VERSION ""

NS_ :

BS_:

BU_: RLPSU DPSU APSU PSB SHVU_RR vHS_B2 FCS EMCU SLB RCM CGW_CCU vDummy_HS_B ATS RLHV PFSU SGU ALBCU DSAU SWRC SHVU_FR RCS RRPSU BLTN_CAM SCM DLBCU OHCL RWPC RRHV WPC HOD ASAU

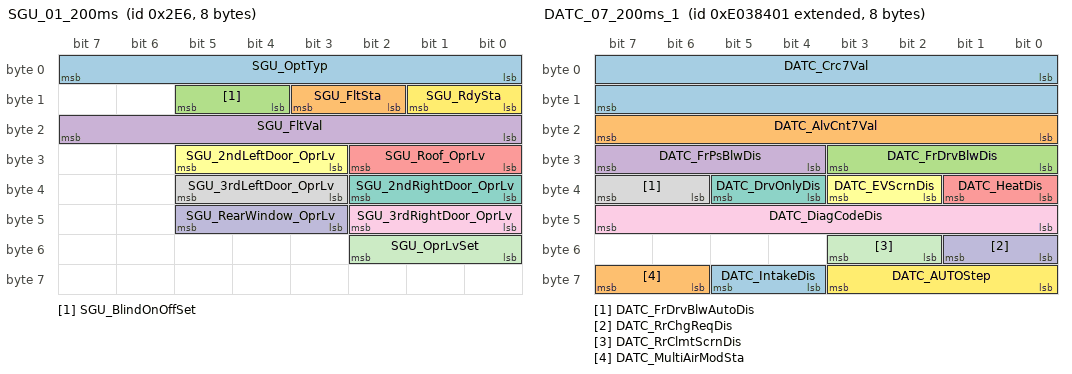
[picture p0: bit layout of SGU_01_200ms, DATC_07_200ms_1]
BO_ 742 SGU_01_200ms: 8 SGU
 SG_ SGU_OptTyp : 0|8@1+ (1,0) [0|0] ""  Vector__XXX
 SG_ SGU_FltSta : 10|2@1+ (1,0) [0|0] ""  Vector__XXX
 SG_ SGU_BlindOnOffSet : 12|2@1+ (1,0) [0|0] ""  CGW_CCU
 SG_ SGU_FltVal : 16|8@1+ (1,0) [0|0] ""  Vector__XXX
 SG_ SGU_Roof_OprLv : 24|3@1+ (1,0) [0|0] ""  CGW_CCU
 SG_ SGU_2ndLeftDoor_OprLv : 27|3@1+ (1,0) [0|0] ""  CGW_CCU
 SG_ SGU_2ndRightDoor_OprLv : 32|3@1+ (1,0) [0|0] ""  CGW_CCU
 SG_ SGU_3rdLeftDoor_OprLv : 35|3@1+ (1,0) [0|0] ""  CGW_CCU
 SG_ SGU_3rdRightDoor_OprLv : 40|3@1+ (1,0) [0|0] ""  CGW_CCU
 SG_ SGU_RearWindow_OprLv : 43|3@1+ (1,0) [0|0] ""  CGW_CCU
 SG_ SGU_OprLvSet : 48|3@1+ (1,0) [0|0] ""  CGW_CCU
 SG_ SGU_RdySta : 8|2@1+ (1,0) [0|0] ""  Vector__XXX

BO_ 2382595073 DATC_07_200ms_1: 8 CGW_CCU
 SG_ DATC_Crc7Val : 0|16@1+ (1,0) [0|0] ""  Vector__XXX
 SG_ DATC_AlvCnt7Val : 16|8@1+ (1,0) [0|0] ""  Vector__XXX
 SG_ DATC_FrDrvBlwDis : 24|4@1+ (1,0) [0|0] ""  ATS
 SG_ DATC_FrPsBlwDis : 28|4@1+ (1,0) [0|0] ""  ATS
 SG_ DATC_HeatDis : 32|2@1+ (1,0) [0|0] "flag"  ATS
 SG_ DATC_EVScrnDis : 34|2@1+ (1,0) [0|0] ""  Vector__XXX
 SG_ DATC_DrvOnlyDis : 36|2@1+ (1,0) [0|0] ""  ATS
 SG_ DATC_FrDrvBlwAutoDis : 38|2@1+ (1,0) [0|0] ""  Vector__XXX
 SG_ DATC_DiagCodeDis : 40|8@1+ (1,-1) [0|0] ""  Vector__XXX
 SG_ DATC_RrChgReqDis : 48|2@1+ (1,0) [0|0] ""  Vector__XXX
 SG_ DATC_RrClmtScrnDis : 50|2@1+ (1,0) [0|0] ""  ATS
 SG_ DATC_AUTOStep : 56|4@1+ (1,0) [0|0] ""  ATS
 SG_ DATC_IntakeDis : 60|2@1+ (1,0) [0|0] ""  ATS
 SG_ DATC_MultiAirModSta : 62|2@1+ (1,0) [0|0] ""  Vector__XXX

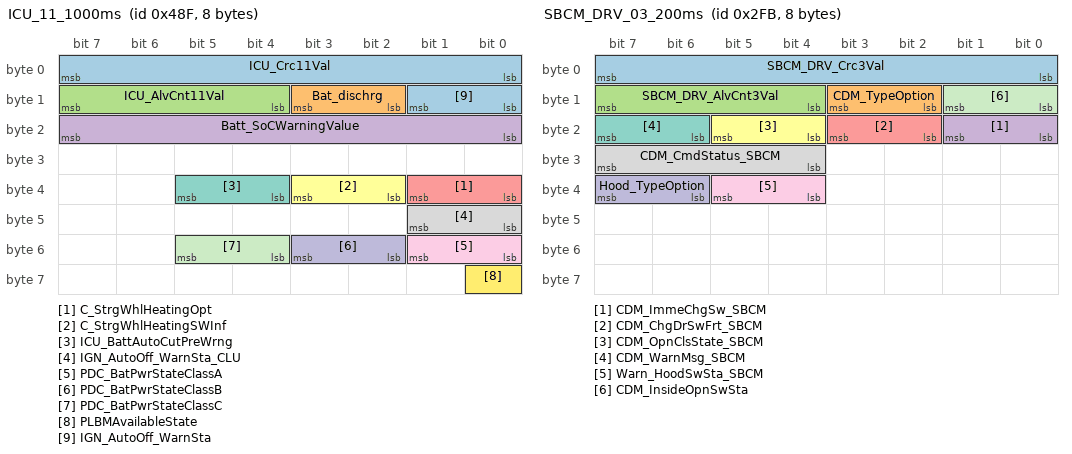
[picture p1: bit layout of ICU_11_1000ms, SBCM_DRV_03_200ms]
BO_ 1167 ICU_11_1000ms: 8 CGW_CCU
 SG_ ICU_Crc11Val : 0|8@1+ (1,0) [0|0] ""  Vector__XXX
 SG_ Bat_dischrg : 10|2@1+ (1,0) [0|0] ""  Vector__XXX
 SG_ ICU_AlvCnt11Val : 12|4@1+ (1,0) [0|0] ""  Vector__XXX
 SG_ Batt_SoCWarningValue : 16|8@1+ (1,0) [0|0] "%"  Vector__XXX
 SG_ C_StrgWhlHeatingOpt : 32|2@1+ (1,0) [0|0] ""  Vector__XXX
 SG_ C_StrgWhlHeatingSWInf : 34|2@1+ (1,0) [0|0] ""  Vector__XXX
 SG_ ICU_BattAutoCutPreWrng : 36|2@1+ (1,0) [0|0] ""  BLTN_CAM
 SG_ IGN_AutoOff_WarnSta_CLU : 40|2@1+ (1,0) [0|0] ""  Vector__XXX
 SG_ PDC_BatPwrStateClassA : 48|2@1+ (1,0) [0|0] ""  Vector__XXX
 SG_ PDC_BatPwrStateClassB : 50|2@1+ (1,0) [0|0] ""  Vector__XXX
 SG_ PDC_BatPwrStateClassC : 52|2@1+ (1,0) [0|0] ""  Vector__XXX
 SG_ PLBMAvailableState : 56|1@1+ (1,0) [0|0] ""  Vector__XXX
 SG_ IGN_AutoOff_WarnSta : 8|2@1+ (1,0) [0|0] ""  Vector__XXX

BO_ 763 SBCM_DRV_03_200ms: 8 CGW_CCU
 SG_ SBCM_DRV_Crc3Val : 0|8@1+ (1,0) [0|0] ""  Vector__XXX
 SG_ CDM_TypeOption : 10|2@1+ (1,0) [0|0] ""  Vector__XXX
 SG_ SBCM_DRV_AlvCnt3Val : 12|4@1+ (1,0) [0|0] ""  Vector__XXX
 SG_ CDM_ImmeChgSw_SBCM : 16|2@1+ (1,0) [0|0] ""  Vector__XXX
 SG_ CDM_ChgDrSwFrt_SBCM : 18|2@1+ (1,0) [0|0] ""  Vector__XXX
 SG_ CDM_OpnClsState_SBCM : 20|2@1+ (1,0) [0|0] ""  Vector__XXX
 SG_ CDM_WarnMsg_SBCM : 22|2@1+ (1,0) [0|0] ""  Vector__XXX
 SG_ CDM_CmdStatus_SBCM : 28|4@1+ (1,0) [0|0] ""  Vector__XXX
 SG_ Warn_HoodSwSta_SBCM : 36|2@1+ (1,0) [0|0] ""  BLTN_CAM
 SG_ Hood_TypeOption : 38|2@1+ (1,0) [0|0] ""  BLTN_CAM
 SG_ CDM_InsideOpnSwSta : 8|2@1+ (1,0) [0|0] ""  Vector__XXX

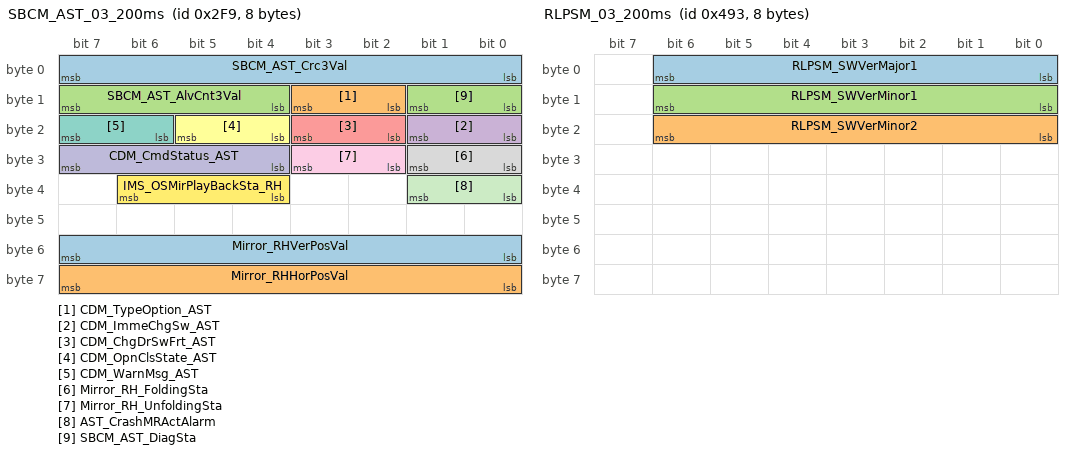
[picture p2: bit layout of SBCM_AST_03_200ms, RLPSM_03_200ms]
BO_ 761 SBCM_AST_03_200ms: 8 CGW_CCU
 SG_ SBCM_AST_Crc3Val : 0|8@1+ (1,0) [0|0] ""  Vector__XXX
 SG_ CDM_TypeOption_AST : 10|2@1+ (1,0) [0|0] ""  Vector__XXX
 SG_ SBCM_AST_AlvCnt3Val : 12|4@1+ (1,0) [0|0] ""  Vector__XXX
 SG_ CDM_ImmeChgSw_AST : 16|2@1+ (1,0) [0|0] ""  Vector__XXX
 SG_ CDM_ChgDrSwFrt_AST : 18|2@1+ (1,0) [0|0] ""  Vector__XXX
 SG_ CDM_OpnClsState_AST : 20|2@1+ (1,0) [0|0] ""  Vector__XXX
 SG_ CDM_WarnMsg_AST : 22|2@1+ (1,0) [0|0] ""  Vector__XXX
 SG_ Mirror_RH_FoldingSta : 24|2@1+ (1,0) [0|0] ""  Vector__XXX
 SG_ Mirror_RH_UnfoldingSta : 26|2@1+ (1,0) [0|0] ""  Vector__XXX
 SG_ CDM_CmdStatus_AST : 28|4@1+ (1,0) [0|0] ""  Vector__XXX
 SG_ AST_CrashMRActAlarm : 32|2@1+ (1,0) [0|0] ""  Vector__XXX
 SG_ IMS_OSMirPlayBackSta_RH : 36|3@1+ (1,0) [0|0] ""  DPSU
 SG_ Mirror_RHVerPosVal : 48|8@1+ (0.02,0) [0|0] "V"  Vector__XXX
 SG_ Mirror_RHHorPosVal : 56|8@1+ (0.02,0) [0|0] "V"  Vector__XXX
 SG_ SBCM_AST_DiagSta : 8|2@1+ (1,0) [0|0] ""  Vector__XXX

BO_ 1171 RLPSM_03_200ms: 8 RLPSU
 SG_ RLPSM_SWVerMajor1 : 0|7@1+ (1,0) [0|0] ""  Vector__XXX
 SG_ RLPSM_SWVerMinor2 : 16|7@1+ (1,0) [0|0] ""  Vector__XXX
 SG_ RLPSM_SWVerMinor1 : 8|7@1+ (1,0) [0|0] ""  Vector__XXX

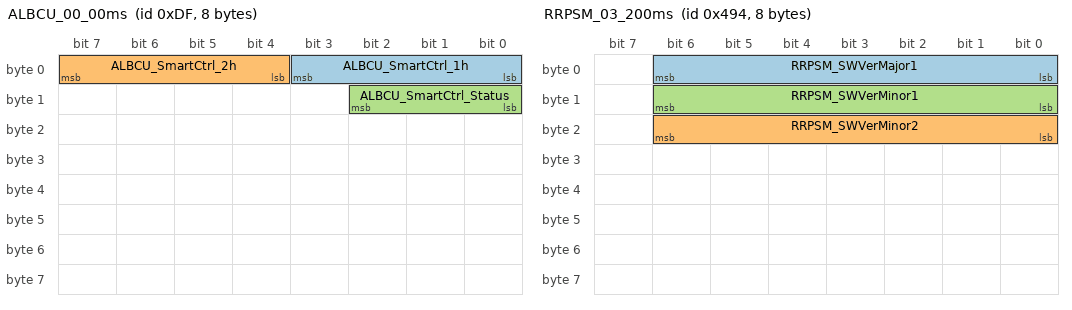
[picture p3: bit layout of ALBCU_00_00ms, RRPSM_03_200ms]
BO_ 223 ALBCU_00_00ms: 8 ALBCU
 SG_ ALBCU_SmartCtrl_1h : 0|4@1+ (1,0) [0|0] ""  CGW_CCU
 SG_ ALBCU_SmartCtrl_2h : 4|4@1+ (1,0) [0|0] ""  CGW_CCU
 SG_ ALBCU_SmartCtrl_Status : 8|3@1+ (1,0) [0|0] ""  CGW_CCU

BO_ 1172 RRPSM_03_200ms: 8 RRPSU
 SG_ RRPSM_SWVerMajor1 : 0|7@1+ (1,0) [0|0] ""  Vector__XXX
 SG_ RRPSM_SWVerMinor2 : 16|7@1+ (1,0) [0|0] ""  Vector__XXX
 SG_ RRPSM_SWVerMinor1 : 8|7@1+ (1,0) [0|0] ""  Vector__XXX

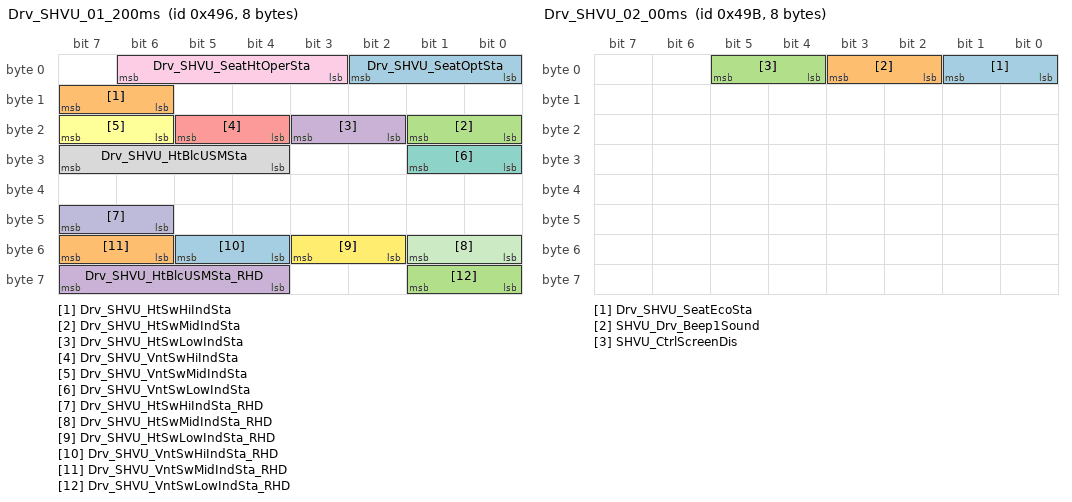
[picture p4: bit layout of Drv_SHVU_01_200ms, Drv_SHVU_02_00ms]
BO_ 1174 Drv_SHVU_01_200ms: 8 APSU
 SG_ Drv_SHVU_SeatOptSta : 0|3@1+ (1,0) [0|0] ""  CGW_CCU,FCS,CGW_CCU
 SG_ Drv_SHVU_HtSwHiIndSta : 14|2@1+ (1,0) [0|0] ""  FCS,CGW_CCU
 SG_ Drv_SHVU_HtSwMidIndSta : 16|2@1+ (1,0) [0|0] ""  FCS,CGW_CCU
 SG_ Drv_SHVU_HtSwLowIndSta : 18|2@1+ (1,0) [0|0] ""  FCS,CGW_CCU
 SG_ Drv_SHVU_VntSwHiIndSta : 20|2@1+ (1,0) [0|0] ""  FCS,CGW_CCU
 SG_ Drv_SHVU_VntSwMidIndSta : 22|2@1+ (1,0) [0|0] ""  FCS,CGW_CCU
 SG_ Drv_SHVU_VntSwLowIndSta : 24|2@1+ (1,0) [0|0] ""  FCS,CGW_CCU
 SG_ Drv_SHVU_HtBlcUSMSta : 28|4@1+ (1,0) [0|0] ""  CGW_CCU
 SG_ Drv_SHVU_SeatHtOperSta : 3|4@1+ (1,0) [0|0] ""  CGW_CCU
 SG_ Drv_SHVU_HtSwHiIndSta_RHD : 46|2@1+ (1,0) [0|0] ""  FCS,CGW_CCU
 SG_ Drv_SHVU_HtSwMidIndSta_RHD : 48|2@1+ (1,0) [0|0] ""  FCS,CGW_CCU
 SG_ Drv_SHVU_HtSwLowIndSta_RHD : 50|2@1+ (1,0) [0|0] ""  FCS,CGW_CCU
 SG_ Drv_SHVU_VntSwHiIndSta_RHD : 52|2@1+ (1,0) [0|0] ""  FCS,CGW_CCU
 SG_ Drv_SHVU_VntSwMidIndSta_RHD : 54|2@1+ (1,0) [0|0] ""  FCS,CGW_CCU
 SG_ Drv_SHVU_VntSwLowIndSta_RHD : 56|2@1+ (1,0) [0|0] ""  FCS,CGW_CCU
 SG_ Drv_SHVU_HtBlcUSMSta_RHD : 60|4@1+ (1,0) [0|0] ""  CGW_CCU

BO_ 1179 Drv_SHVU_02_00ms: 8 APSU
 SG_ Drv_SHVU_SeatEcoSta : 0|2@1+ (1,0) [0|0] ""  CGW_CCU
 SG_ SHVU_Drv_Beep1Sound : 2|2@1+ (1,0) [0|0] ""  CGW_CCU
 SG_ SHVU_CtrlScreenDis : 4|2@1+ (1,0) [0|0] ""  CGW_CCU

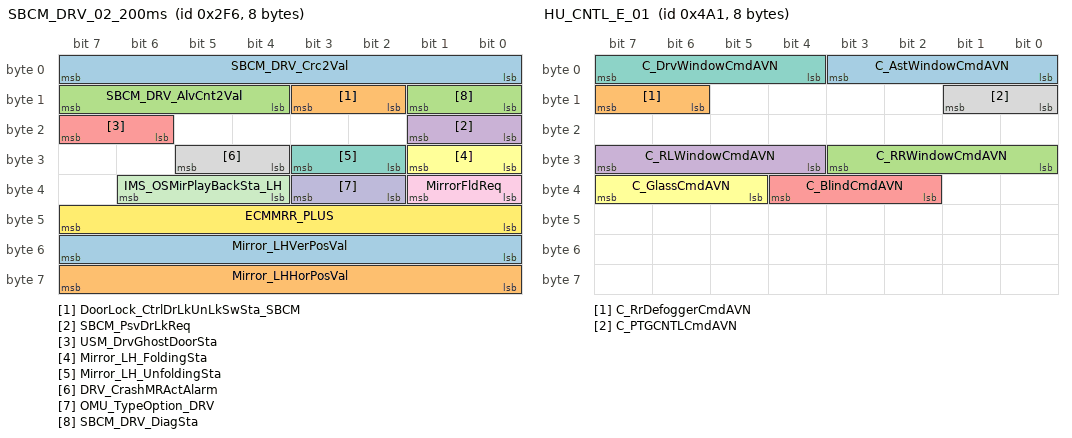
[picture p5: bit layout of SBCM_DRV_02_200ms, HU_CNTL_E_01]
BO_ 758 SBCM_DRV_02_200ms: 8 CGW_CCU
 SG_ SBCM_DRV_Crc2Val : 0|8@1+ (1,0) [0|0] ""  Vector__XXX
 SG_ DoorLock_CtrlDrLkUnLkSwSta_SBCM : 10|2@1+ (1,0) [0|0] ""  Vector__XXX
 SG_ SBCM_DRV_AlvCnt2Val : 12|4@1+ (1,0) [0|0] ""  Vector__XXX
 SG_ SBCM_PsvDrLkReq : 16|2@1+ (1,0) [0|0] ""  Vector__XXX
 SG_ USM_DrvGhostDoorSta : 22|2@1+ (1,0) [0|0] ""  Vector__XXX
 SG_ Mirror_LH_FoldingSta : 24|2@1+ (1,0) [0|0] ""  Vector__XXX
 SG_ Mirror_LH_UnfoldingSta : 26|2@1+ (1,0) [0|0] ""  Vector__XXX
 SG_ DRV_CrashMRActAlarm : 28|2@1+ (1,0) [0|0] ""  Vector__XXX
 SG_ MirrorFldReq : 32|2@1+ (1,0) [0|0] ""  Vector__XXX
 SG_ OMU_TypeOption_DRV : 34|2@1+ (1,0) [0|0] ""  Vector__XXX
 SG_ IMS_OSMirPlayBackSta_LH : 36|3@1+ (1,0) [0|0] ""  DPSU
 SG_ ECMMRR_PLUS : 40|8@1+ (1,0) [0|0] ""  Vector__XXX
 SG_ Mirror_LHVerPosVal : 48|8@1+ (0.02,0) [0|0] "V"  Vector__XXX
 SG_ Mirror_LHHorPosVal : 56|8@1+ (0.02,0) [0|0] "V"  Vector__XXX
 SG_ SBCM_DRV_DiagSta : 8|2@1+ (1,0) [0|0] ""  Vector__XXX

BO_ 208 RR_SHVU_03_200ms: 8 SHVU_FR
 SG_ RR_SHVU_DTCdisplay : 0|8@1+ (1,0) [0|0] ""  ATS
 SG_ RR_SHVU_DiagMode : 8|2@1+ (1,0) [0|0] ""  ATS

BO_ 1180 Ast_SHVU_02_00ms: 8 SHVU_FR
 SG_ SHVU_Ast_Beep1Sound : 2|2@1+ (1,0) [0|0] ""  CGW_CCU
 SG_ Ast_SHVU_SeatEcoSta : 26|2@1+ (1,0) [0|0] ""  CGW_CCU

BO_ 1181 RL_SHVU_02_00ms: 8 RLHV
 SG_ RL_SHVU_SeatEcoSta : 0|2@1+ (1,0) [0|0] ""  ATS,CGW_CCU

BO_ 1182 RR_SHVU_02_00ms: 8 SHVU_FR
 SG_ RR_SHVU_SeatEcoSta : 0|2@1+ (1,0) [0|0] ""  ATS,CGW_CCU

BO_ 1186 HU_GW_E_02: 8 CGW_CCU
 SG_ C_PTGMStopRlyIBOX : 10|3@1+ (1,0) [0|0] ""  Vector__XXX
 SG_ C_PTGMCmdRlyIBOX : 14|2@1+ (1,0) [0|0] ""  Vector__XXX
 SG_ C_RemoteWdwCMDHU : 16|2@1+ (1,0) [0|0] ""  Vector__XXX
 SG_ C_EsyAcsProfileID_HU : 18|2@1+ (1,0) [0|0] ""  DPSU
 SG_ C_TeleDefoggerHeatingCmdIBOX : 22|2@1+ (1,0) [0|0] ""  Vector__XXX
 SG_ C_TeleFrontHeatingCmdIBOX : 26|2@1+ (1,0) [0|0] ""  Vector__XXX
 SG_ HU_CDMOpenCmd : 28|2@1+ (1,0) [0|0] ""  Vector__XXX
 SG_ C_PreCrankReq : 30|2@1+ (1,0) [0|0] ""  BLTN_CAM
 SG_ C_TeleAstSeatOpCmdIBOX : 32|4@1+ (1,0) [0|0] ""  APSU,SHVU_FR
 SG_ C_TeleDrvSeatOpCmdIBOX : 36|4@1+ (1,0) [0|0] ""  SHVU_FR,DPSU
 SG_ C_TeleRRSeatOpCmdIBOX : 40|4@1+ (1,0) [0|0] ""  RRHV,SHVU_FR,SHVU_RR,RRPSU,RLPSU,ATS
 SG_ C_TeleRLSeatOpCmdIBOX : 44|4@1+ (1,0) [0|0] ""  RLHV,SHVU_FR,SHVU_RR,RRPSU,RLPSU,ATS
 SG_ C_HazardFromCCS : 48|2@1+ (1,0) [0|0] ""  Vector__XXX
 SG_ C_PanicFromCCS : 50|2@1+ (1,0) [0|0] ""  Vector__XXX
 SG_ C_CtrlDrUnlockRlyCCS : 52|2@1+ (1,0) [0|0] ""  Vector__XXX
 SG_ C_CtrlDrLockRlyCCS : 54|2@1+ (1,0) [0|0] ""  Vector__XXX
 SG_ C_DrvPSDCloseRlyIBOX : 56|2@1+ (1,0) [0|0] ""  Vector__XXX
 SG_ C_DrvPSDOpenRlyIBOX : 58|2@1+ (1,0) [0|0] ""  Vector__XXX
 SG_ C_AstPSDCloseRlyIBOX : 60|2@1+ (1,0) [0|0] ""  Vector__XXX
 SG_ C_AstPSDOpenRlyIBOX : 62|2@1+ (1,0) [0|0] ""  Vector__XXX

BO_ 1185 HU_CNTL_E_01: 8 CGW_CCU
 SG_ C_AstWindowCmdAVN : 0|4@1+ (1,0) [0|0] ""  Vector__XXX
 SG_ C_RrDefoggerCmdAVN : 14|2@1+ (1,0) [0|0] ""  Vector__XXX
 SG_ C_RRWindowCmdAVN : 24|4@1+ (1,0) [0|0] ""  Vector__XXX
 SG_ C_RLWindowCmdAVN : 28|4@1+ (1,0) [0|0] ""  Vector__XXX
 SG_ C_BlindCmdAVN : 34|3@1+ (1,0) [0|0] ""  RCM
 SG_ C_GlassCmdAVN : 37|3@1+ (1,0) [0|0] ""  RCM
 SG_ C_DrvWindowCmdAVN : 4|4@1+ (1,0) [0|0] ""  Vector__XXX
 SG_ C_PTGCNTLCmdAVN : 8|2@1+ (1,0) [0|0] ""  Vector__XXX

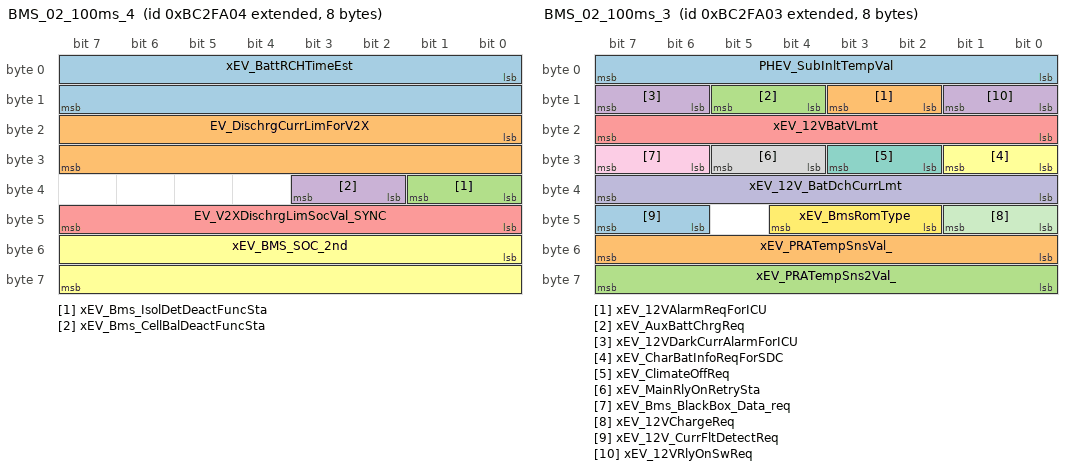
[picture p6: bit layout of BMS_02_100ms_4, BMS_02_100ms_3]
BO_ 2344811012 BMS_02_100ms_4: 8 CGW_CCU
 SG_ xEV_BattRCHTimeEst : 0|16@1+ (1,0) [0|0] "Min"  Vector__XXX
 SG_ EV_DischrgCurrLimForV2X : 16|16@1+ (0.1,0) [0|0] "A"  Vector__XXX
 SG_ xEV_Bms_IsolDetDeactFuncSta : 32|2@1+ (1,0) [0|0] "flg"  Vector__XXX
 SG_ xEV_Bms_CellBalDeactFuncSta : 34|2@1+ (1,0) [0|0] "flag"  Vector__XXX
 SG_ EV_V2XDischrgLimSocVal_SYNC : 40|8@1+ (0.5,0) [0|0] "%"  Vector__XXX
 SG_ xEV_BMS_SOC_2nd : 48|16@1+ (0.05,0) [0|0] "%"  Vector__XXX

BO_ 2344811011 BMS_02_100ms_3: 8 CGW_CCU
 SG_ PHEV_SubInltTempVal : 0|8@1- (1,0) [0|0] "¡É"  Vector__XXX
 SG_ xEV_12VAlarmReqForICU : 10|2@1+ (1,0) [0|0] ""  Vector__XXX
 SG_ xEV_AuxBattChrgReq : 12|2@1+ (1,0) [0|0] ""  Vector__XXX
 SG_ xEV_12VDarkCurrAlarmForICU : 14|2@1+ (1,0) [0|0] ""  Vector__XXX
 SG_ xEV_12VBatVLmt : 16|8@1+ (0.1,0) [0|0] "V"  Vector__XXX
 SG_ xEV_CharBatInfoReqForSDC : 24|2@1+ (1,0) [0|0] ""  Vector__XXX
 SG_ xEV_ClimateOffReq : 26|2@1+ (1,0) [0|0] ""  Vector__XXX
 SG_ xEV_MainRlyOnRetrySta : 28|2@1+ (1,0) [0|0] ""  Vector__XXX
 SG_ xEV_Bms_BlackBox_Data_req : 30|2@1+ (1,0) [0|0] ""  Vector__XXX
 SG_ xEV_12V_BatDchCurrLmt : 32|8@1+ (1,0) [0|0] "A"  Vector__XXX
 SG_ xEV_12VChargeReq : 40|2@1+ (1,0) [0|0] ""  Vector__XXX
 SG_ xEV_BmsRomType : 42|3@1+ (1,0) [0|0] ""  Vector__XXX
 SG_ xEV_12V_CurrFltDetectReq : 46|2@1+ (1,0) [0|0] ""  Vector__XXX
 SG_ xEV_PRATempSnsVal_ : 48|8@1- (2,0) [0|0] "¡É"  Vector__XXX
 SG_ xEV_PRATempSns2Val_ : 56|8@1- (2,0) [0|0] "¡É"  Vector__XXX
 SG_ xEV_12VRlyOnSwReq : 8|2@1+ (1,0) [0|0] ""  Vector__XXX

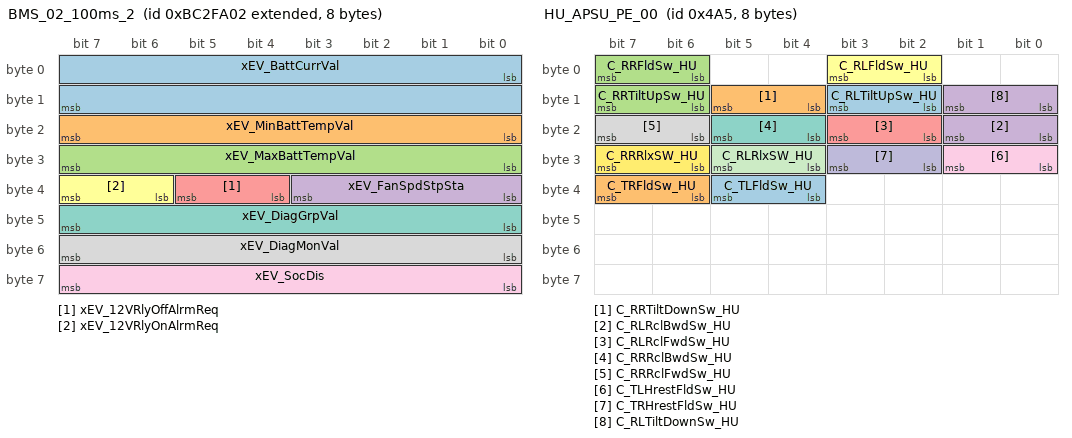
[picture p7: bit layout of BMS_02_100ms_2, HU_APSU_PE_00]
BO_ 2344811010 BMS_02_100ms_2: 8 CGW_CCU
 SG_ xEV_BattCurrVal : 0|16@1- (0.1,0) [0|0] "A"  Vector__XXX
 SG_ xEV_MinBattTempVal : 16|8@1- (1,0) [0|0] "¡É"  Vector__XXX
 SG_ xEV_MaxBattTempVal : 24|8@1- (1,0) [0|0] "¡É"  Vector__XXX
 SG_ xEV_FanSpdStpSta : 32|4@1+ (1,0) [0|0] "Step"  Vector__XXX
 SG_ xEV_12VRlyOffAlrmReq : 36|2@1+ (1,0) [0|0] ""  Vector__XXX
 SG_ xEV_12VRlyOnAlrmReq : 38|2@1+ (1,0) [0|0] ""  Vector__XXX
 SG_ xEV_DiagGrpVal : 40|8@1+ (1,0) [0|0] ""  Vector__XXX
 SG_ xEV_DiagMonVal : 48|8@1+ (1,0) [0|0] ""  Vector__XXX
 SG_ xEV_SocDis : 56|8@1+ (0.5,0) [0|0] "%"  SWRC

BO_ 1189 HU_APSU_PE_00: 8 CGW_CCU
 SG_ C_RLTiltUpSw_HU : 10|2@1+ (1,0) [0|0] ""  APSU,RRPSU,RLPSU
 SG_ C_RRTiltDownSw_HU : 12|2@1+ (1,0) [0|0] ""  APSU,RRPSU,RLPSU
 SG_ C_RRTiltUpSw_HU : 14|2@1+ (1,0) [0|0] ""  APSU,RRPSU,RLPSU
 SG_ C_RLRclBwdSw_HU : 16|2@1+ (1,0) [0|0] ""  APSU,RRPSU,RLPSU
 SG_ C_RLRclFwdSw_HU : 18|2@1+ (1,0) [0|0] ""  APSU,RRPSU,RLPSU
 SG_ C_RLFldSw_HU : 2|2@1+ (1,0) [0|0] ""  RLPSU
 SG_ C_RRRclBwdSw_HU : 20|2@1+ (1,0) [0|0] ""  APSU,RRPSU,RLPSU
 SG_ C_RRRclFwdSw_HU : 22|2@1+ (1,0) [0|0] ""  APSU,RRPSU,RLPSU
 SG_ C_TLHrestFldSw_HU : 24|2@1+ (1,0) [0|0] ""  PFSU
 SG_ C_TRHrestFldSw_HU : 26|2@1+ (1,0) [0|0] ""  PFSU
 SG_ C_RLRlxSW_HU : 28|2@1+ (1,0) [0|0] ""  RLPSU
 SG_ C_RRRlxSW_HU : 30|2@1+ (1,0) [0|0] ""  RRPSU
 SG_ C_TLFldSw_HU : 36|2@1+ (1,0) [0|0] ""  PFSU
 SG_ C_TRFldSw_HU : 38|2@1+ (1,0) [0|0] ""  PFSU
 SG_ C_RRFldSw_HU : 6|2@1+ (1,0) [0|0] ""  RRPSU
 SG_ C_RLTiltDownSw_HU : 8|2@1+ (1,0) [0|0] ""  APSU,RRPSU,RLPSU

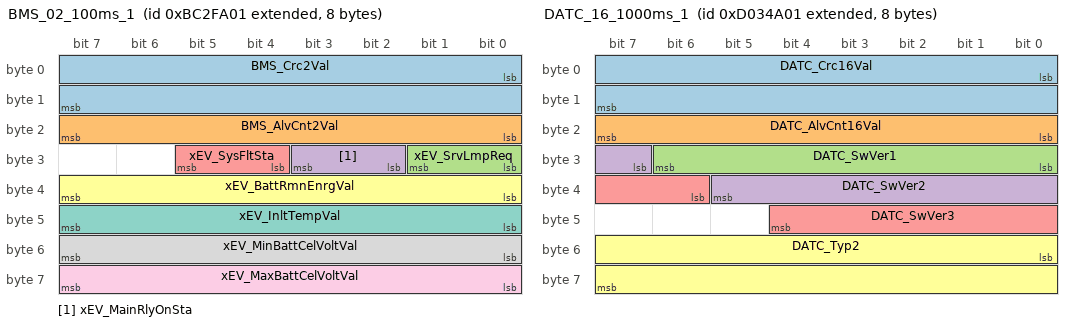
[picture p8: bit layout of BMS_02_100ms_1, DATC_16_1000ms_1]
BO_ 2344811009 BMS_02_100ms_1: 8 CGW_CCU
 SG_ BMS_Crc2Val : 0|16@1+ (1,0) [0|0] ""  Vector__XXX
 SG_ BMS_AlvCnt2Val : 16|8@1+ (1,0) [0|0] ""  Vector__XXX
 SG_ xEV_SrvLmpReq : 24|2@1+ (1,0) [0|0] ""  Vector__XXX
 SG_ xEV_MainRlyOnSta : 26|2@1+ (1,0) [0|0] ""  Vector__XXX
 SG_ xEV_SysFltSta : 28|2@1+ (1,0) [0|0] ""  Vector__XXX
 SG_ xEV_BattRmnEnrgVal : 32|8@1+ (1,0) [0|0] ""  Vector__XXX
 SG_ xEV_InltTempVal : 40|8@1- (1,0) [0|0] "¡É"  Vector__XXX
 SG_ xEV_MinBattCelVoltVal : 48|8@1+ (0.02,0) [0|0] "V"  Vector__XXX
 SG_ xEV_MaxBattCelVoltVal : 56|8@1+ (0.02,0) [0|0] "V"  Vector__XXX

BO_ 1195 HU_USM_E_04: 8 CGW_CCU
 SG_ CF_AVN_CluWelcomeSnd : 0|2@1+ (1,0) [0|0] ""  Vector__XXX
 SG_ CF_AVN_CluTransmissionDisp : 10|2@1+ (1,0) [0|0] ""  Vector__XXX
 SG_ CF_AVN_CluWiperLight : 12|2@1+ (1,0) [0|0] ""  Vector__XXX
 SG_ CF_AVN_CluRoadInfoGuide : 14|2@1+ (1,0) [0|0] ""  Vector__XXX
 SG_ CF_AVN_CluUserSettingPeriod : 17|7@1+ (1,0) [0|0] ""  Vector__XXX
 SG_ CF_AVN_CluAutoInitFuelEconomy : 2|3@1+ (1,0) [0|0] ""  Vector__XXX
 SG_ CF_AVN_CluFuelEconUnit_mi : 27|2@1+ (1,0) [0|0] ""  Vector__XXX
 SG_ CF_AVN_CluFuelEconUnit_km : 29|2@1+ (1,0) [0|0] ""  Vector__XXX
 SG_ CF_AVN_CluUserSettingDistance : 31|17@1+ (1,0) [0|0] ""  Vector__XXX
 SG_ CF_AVN_CluRheostatLvl : 49|5@1+ (1,0) [0|0] ""  Vector__XXX
 SG_ CF_AVN_CluVoiceVolume : 5|3@1+ (1,0) [0|0] ""  Vector__XXX
 SG_ CF_AVN_EVReset : 54|2@1+ (1,0) [0|0] ""  Vector__XXX
 SG_ CF_AVN_UnitReset : 56|2@1+ (1,0) [0|0] ""  Vector__XXX
 SG_ CF_AVN_IcyRoadWarn : 58|2@1+ (1,0) [0|0] ""  Vector__XXX
 SG_ CF_AVN_CluServiceReminderReset : 60|2@1+ (1,0) [0|0] ""  Vector__XXX
 SG_ CF_AVN_CluUSMReset : 62|2@1+ (1,0) [0|0] ""  WPC,RWPC,PSB,SLB,APSU,RLHV,RRHV,SHVU_FR,SHVU_RR,DPSU,DLBCU,PFSU,RRPSU,RLPSU,ATS,DSAU,ASAU,BLTN_CAM,ALBCU
 SG_ CF_AVN_CluServiceReminderSet : 8|2@1+ (1,0) [0|0] ""  Vector__XXX

BO_ 1193 HU_USM_E_02: 8 CGW_CCU
 SG_ C_PTGMNValueSet : 0|2@1+ (1,0) [0|0] ""  Vector__XXX
 SG_ CF_AVN_PSMNValueSet : 10|3@1+ (1,0) [0|0] ""  DPSU
 SG_ C_HfreeTrunkTgNValueSet : 13|3@1+ (1,0) [0|0] ""  Vector__XXX
 SG_ CF_AVN_TrfChgSet : 17|2@1+ (1,0) [0|0] ""  Vector__XXX
 SG_ CF_AVN_SCMNValueSet : 19|2@1+ (1,0) [0|0] ""  Vector__XXX
 SG_ CF_AVN_ADrUNValueSet : 2|3@1+ (1,0) [0|0] ""  Vector__XXX
 SG_ CF_AVN_OTTurnNValueSet : 21|3@1+ (1,0) [0|0] ""  Vector__XXX
 SG_ CF_Gway_WPCNValueSet : 24|2@1+ (1,0) [0|0] ""  WPC
 SG_ C_AVN_RearWiperNValueSet : 26|2@1+ (1,0) [0|0] ""  Vector__XXX
 SG_ C_UnlockWelocomeNValueSet : 28|2@1+ (1,0) [0|0] ""  Vector__XXX
 SG_ C_SmartWelocomeNValueSet : 30|2@1+ (1,0) [0|0] ""  Vector__XXX
 SG_ CF_AVN_PTGSpeedNValueSet : 32|2@1+ (1,0) [0|0] ""  Vector__XXX
 SG_ CR_Datc_DRSeatWheel_USM_Set : 34|2@1+ (1,0) [0|0] ""  Vector__XXX
 SG_ CF_AVN_TTUnlockNValueSet : 38|2@1+ (1,0) [0|0] ""  Vector__XXX
 SG_ CF_Gway_RWPCNValueSet : 40|2@1+ (1,0) [0|0] ""  RWPC
 SG_ C_PSDNValueSet : 44|2@1+ (1,0) [0|0] ""  Vector__XXX
 SG_ CF_Avn_HAPTICWARNINGNValueSet : 49|3@1+ (1,0) [0|0] ""  Vector__XXX
 SG_ CR_Datc_DRSeatHeat_USM_Set : 52|2@1+ (1,0) [0|0] ""  Vector__XXX
 SG_ C_WALNValueSet : 54|2@1+ (1,0) [0|0] ""  Vector__XXX
 SG_ C_ApprUnlockNValue : 56|2@1+ (1,0) [0|0] ""  Vector__XXX
 SG_ CF_AVN_SEW_NEWNValueSet : 58|2@1+ (1,0) [0|0] ""  Vector__XXX
 SG_ CF_AVN_SEA_NEWNValueSet : 60|2@1+ (1,0) [0|0] ""  Vector__XXX
 SG_ CF_AVN_EscortHLNValueSet : 8|2@1+ (1,0) [0|0] ""  Vector__XXX

BO_ 2365803012 DATC_16_1000ms_4: 8 CGW_CCU

BO_ 2365803011 DATC_16_1000ms_3: 8 CGW_CCU

BO_ 2365803010 DATC_16_1000ms_2: 8 CGW_CCU
 SG_ DATC_SwVer4 : 0|7@1+ (1,0) [0|0] ""  Vector__XXX
 SG_ DATC_SwVer5 : 7|7@1+ (1,0) [0|0] ""  Vector__XXX

BO_ 2365803009 DATC_16_1000ms_1: 8 CGW_CCU
 SG_ DATC_Crc16Val : 0|16@1+ (1,0) [0|0] ""  Vector__XXX
 SG_ DATC_AlvCnt16Val : 16|8@1+ (1,0) [0|0] ""  Vector__XXX
 SG_ DATC_SwVer1 : 24|7@1+ (1,0) [0|0] ""  Vector__XXX
 SG_ DATC_SwVer2 : 31|7@1+ (1,0) [0|0] ""  Vector__XXX
 SG_ DATC_SwVer3 : 38|7@1+ (1,0) [0|0] ""  Vector__XXX
 SG_ DATC_Typ2 : 48|16@1+ (1,0) [0|0] ""  ATS

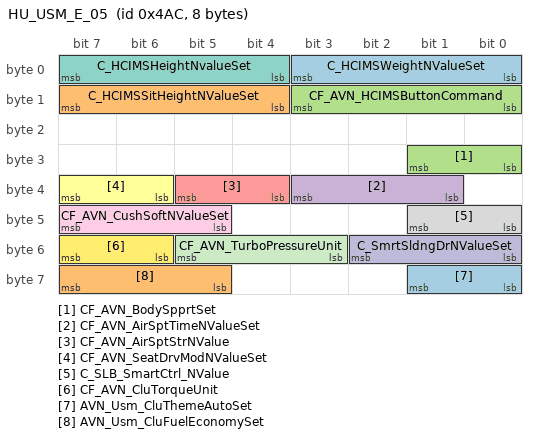
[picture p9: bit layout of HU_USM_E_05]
BO_ 1196 HU_USM_E_05: 8 CGW_CCU
 SG_ C_HCIMSWeightNValueSet : 0|4@1+ (1,0) [0|0] ""  DPSU
 SG_ C_HCIMSSitHeightNValueSet : 12|4@1+ (1,0) [0|0] ""  DPSU
 SG_ CF_AVN_BodySpprtSet : 24|2@1+ (1,0) [0|0] ""  DPSU,DLBCU,DSAU
 SG_ CF_AVN_AirSptTimeNValueSet : 33|3@1+ (1,0) [0|0] ""  DLBCU
 SG_ CF_AVN_AirSptStrNValue : 36|2@1+ (1,0) [0|0] ""  DLBCU
 SG_ CF_AVN_SeatDrvModNValueSet : 38|2@1+ (1,0) [0|0] ""  DPSU,DLBCU,DSAU
 SG_ C_HCIMSHeightNvalueSet : 4|4@1+ (1,0) [0|0] ""  DPSU
 SG_ C_SLB_SmartCtrl_NValue : 40|2@1+ (1,0) [0|0] ""  Vector__XXX
 SG_ CF_AVN_CushSoftNValueSet : 45|3@1+ (1,0) [0|0] ""  DLBCU
 SG_ C_SmrtSldngDrNValueSet : 48|3@1+ (1,0) [0|0] ""  Vector__XXX
 SG_ CF_AVN_TurboPressureUnit : 51|3@1+ (1,0) [0|0] ""  Vector__XXX
 SG_ CF_AVN_CluTorqueUnit : 54|2@1+ (1,0) [0|0] ""  Vector__XXX
 SG_ AVN_Usm_CluThemeAutoSet : 56|2@1+ (1,0) [0|0] ""  Vector__XXX
 SG_ AVN_Usm_CluFuelEconomySet : 61|3@1+ (1,0) [0|0] ""  Vector__XXX
 SG_ CF_AVN_HCIMSButtonCommand : 8|4@1+ (1,0) [0|0] ""  DPSU

BO_ 255 BCM_20_200ms: 8 CGW_CCU
 SG_ BCM_Crc20Val : 0|8@1+ (1,0) [0|0] ""  Vector__XXX
 SG_ BCM_AlvCnt20Val : 12|4@1+ (1,0) [0|0] ""  Vector__XXX
 SG_ BckGls_RrGlsHtdOnCmd : 16|2@1+ (1,0) [0|0] ""  Vector__XXX
 SG_ Wndshld_FrtGlsHtdOnCmd : 18|2@1+ (1,0) [0|0] ""  Vector__XXX
 SG_ Mirror_MirFldOpt : 20|2@1+ (1,0) [0|0] ""  Vector__XXX
 SG_ Window_AsstPwrWdwSunroofEnblSta : 22|2@1+ (1,0) [0|0] ""  RCM
 SG_ Window_RrPwrWdwEnblSta : 24|2@1+ (1,0) [0|0] ""  Vector__XXX
 SG_ Window_RrPwrWdwLkInd : 26|2@1+ (1,0) [0|0] ""  Vector__XXX
 SG_ Window_DrvPwrWdwCmd : 28|2@1+ (1,0) [0|0] ""  Vector__XXX
 SG_ Window_AsstPwrWdwCmd : 30|2@1+ (1,0) [0|0] ""  Vector__XXX
 SG_ Window_RrLftPwrWdwCmd : 32|2@1+ (1,0) [0|0] ""  Vector__XXX
 SG_ Window_RrRtPwrWdwCmd : 34|2@1+ (1,0) [0|0] ""  Vector__XXX
 SG_ Mirror_FldUnfldCmd : 36|2@1+ (1,0) [0|0] ""  Vector__XXX
 SG_ Mirror_FldCtrlSta : 38|2@1+ (1,0) [0|0] ""  Vector__XXX
 SG_ Mirror_UnFldCtrlSta : 40|2@1+ (1,0) [0|0] ""  Vector__XXX
 SG_ Mirror_PosMnlCmd : 42|3@1+ (1,0) [0|0] ""  Vector__XXX
 SG_ Mirror_SelSwIndCmd : 45|3@1+ (1,0) [0|0] ""  Vector__XXX
 SG_ BCM_SafetyWdwOptTyp2 : 49|3@1+ (1,0) [0|0] ""  Vector__XXX
 SG_ Mirror_LHOSMirPlyBckSta : 52|4@1+ (1,0) [0|0] ""  DPSU
 SG_ Mirror_RHOSMirPlyBckSta : 56|4@1+ (1,0) [0|0] ""  DPSU
 SG_ Mirror_SelSwSta : 60|3@1+ (1,0) [0|0] ""  Vector__XXX
 SG_ BckGls_RrGlsHtdOpt : 8|2@1+ (1,0) [0|0] ""  Vector__XXX

BO_TX_BU_ 1174 : APSU,SHVU_FR,DPSU;
BO_TX_BU_ 1179 : APSU,SHVU_FR;
BO_TX_BU_ 208 : SHVU_FR,SHVU_RR,RRHV;
BO_TX_BU_ 1181 : RLHV,SHVU_RR,RLPSU,SHVU_FR;
BO_TX_BU_ 1182 : SHVU_FR,RRPSU,SHVU_RR,RRHV;
CM_ BO_ 223 "[EC] On Event and On Change";
CM_ SG_ 223 ALBCU_SmartCtrl_1h "Smart Posture Adjust 1hr";
CM_ SG_ 223 ALBCU_SmartCtrl_2h "Smart Posture Adjust AVN Display (2hr)";
CM_ SG_ 223 ALBCU_SmartCtrl_Status "Smart Posture Adjust 2nd Interlocked Move AVN popup request";
CM_ BO_ 1180 "[EC] On Event and On Change";
CM_ SG_ 1180 SHVU_Ast_Beep1Sound "SHVU_FR Assistant's Seat Heater or Ventilation Switch input Beep Request";
CM_ SG_ 1180 Ast_SHVU_SeatEcoSta "Assistant (Passenger) Seat Eco+ Mode Status";
CM_ BO_ 255 "[PE] Periodic and On Event";
CM_ SG_ 255 BCM_Crc20Val "BCM_CyclicRedundancyCheck20Value";
CM_ SG_ 255 BCM_AlvCnt20Val "BCM_AliveCounter20Value";
CM_ SG_ 255 Mirror_MirFldOpt "Outside Mirror Electric Fold Option Signal";
CM_ SG_ 255 Mirror_FldUnfldCmd "Mirror Folding Unfolding Command";
CM_ SG_ 255 Mirror_FldCtrlSta "Mirror Fold and Folding Control State";
CM_ SG_ 255 Mirror_UnFldCtrlSta "Mirror Unfold and Unfolding Control State";
CM_ SG_ 255 Mirror_PosMnlCmd "Mirror Positioning Request";
CM_ SG_ 255 Mirror_SelSwIndCmd "Mirror Select Switch Indicator Command";
CM_ SG_ 255 Mirror_LHOSMirPlyBckSta "This siganl indicates Left O/S Mirror moving state for IMS From BDC";
CM_ SG_ 255 Mirror_RHOSMirPlyBckSta "This siganl indicates Right O/S Mirror moving state for IMS From BDC";
CM_ SG_ 255 Mirror_SelSwSta "Outside Mirror Select Button Status";
CM_ SG_ 255 BckGls_RrGlsHtdOpt "Back Glass_Rear Glass Heated Option Signal";
CM_ BO_ 2344811009 "[P] Periodic";
CM_ SG_ 2344811009 BMS_Crc2Val "BMS_CyclicRedundancyCheck2Value";
CM_ SG_ 2344811009 BMS_AlvCnt2Val "BMS_AliveCounter2Value";
CM_ SG_ 2344811009 xEV_SrvLmpReq "xEV_ServiceLampRequest";
CM_ SG_ 2344811009 xEV_MainRlyOnSta "xEV_MainRelayOnStatus";
CM_ SG_ 2344811009 xEV_SysFltSta "xEV_SystemFaultStatus";
CM_ SG_ 2344811009 xEV_BattRmnEnrgVal "xEV_BatteryRemainEnergyValue";
CM_ SG_ 2344811009 xEV_InltTempVal "xEV_InletTemperatureValue";
CM_ SG_ 2344811009 xEV_MinBattCelVoltVal "xEV_MinimumBatteryCellVoltageValue";
CM_ SG_ 2344811009 xEV_MaxBattCelVoltVal "xEV_MaximumBatteryCellVoltageValue";
CM_ BO_ 2344811010 "[P] Periodic";
CM_ SG_ 2344811010 xEV_BattCurrVal "xEV_BatteryCurrentValue";
CM_ SG_ 2344811010 xEV_MinBattTempVal "xEV_MinimumBatteryTemperatureValue";
CM_ SG_ 2344811010 xEV_MaxBattTempVal "xEV_MaximumBatteryTemperatureValue";
CM_ SG_ 2344811010 xEV_FanSpdStpSta "xEV_FanSpeedStepStatus";
CM_ SG_ 2344811010 xEV_12VRlyOffAlrmReq "xEV_12VRelayOffAlarmRequest";
CM_ SG_ 2344811010 xEV_12VRlyOnAlrmReq "xEV_12VRelayOnAlarmRequest";
CM_ SG_ 2344811010 xEV_DiagGrpVal "xEV_DiagnosticGroupValue";
CM_ SG_ 2344811010 xEV_DiagMonVal "xEV_DiagnosticMonitorValue";
CM_ SG_ 2344811010 xEV_SocDis "xEV_StateOfChargeDisplay";
CM_ BO_ 2344811011 "[P] Periodic";
CM_ SG_ 2344811011 PHEV_SubInltTempVal "PHEV_SubInletTemperatureValue";
CM_ SG_ 2344811011 xEV_12VAlarmReqForICU "xEV_12VBatteryAlarmRequestForICU";
CM_ SG_ 2344811011 xEV_AuxBattChrgReq "Aux. Battery Charge Request Flag";
CM_ SG_ 2344811011 xEV_12VDarkCurrAlarmForICU "xEV_12VDarkCurrentAlarmForICU";
CM_ SG_ 2344811011 xEV_12VBatVLmt "xEV_12VBatteryVoltageLimit";
CM_ SG_ 2344811011 xEV_CharBatInfoReqForSDC "xEV_ChargeBatteryInformationRequestForSDC";
CM_ SG_ 2344811011 xEV_ClimateOffReq "xEV_ClimateOffRequest";
CM_ SG_ 2344811011 xEV_MainRlyOnRetrySta "xEV_MainRelayONRetryStatus";
CM_ SG_ 2344811011 xEV_Bms_BlackBox_Data_req "For Saving BMS data set, this signal transmits to MCU";
CM_ SG_ 2344811011 xEV_12V_BatDchCurrLmt "xEV_12VBatteryDischargeCurrentLimit";
CM_ SG_ 2344811011 xEV_12VChargeReq "xEV_12V BatteryChargeRequest";
CM_ SG_ 2344811011 xEV_12V_CurrFltDetectReq "xEV_12VBatteryCurrentSensorFaultDetectRequest";
CM_ SG_ 2344811011 xEV_PRATempSnsVal_ "PRA Temperature #1 (Relay Busbar Temperature #1)";
CM_ SG_ 2344811011 xEV_PRATempSns2Val_ "PRA Temperature #2 (Relay Busbar Temperature #2)";
CM_ SG_ 2344811011 xEV_12VRlyOnSwReq "xEV_12VRelayOnSwitchRequest";
CM_ BO_ 2344811012 "[P] Periodic";
CM_ SG_ 2344811012 xEV_BattRCHTimeEst "calculated charging power by estimated output OBC power";
CM_ SG_ 2344811012 EV_DischrgCurrLimForV2X "Discharge Current Limit(for V2X)";
CM_ SG_ 2344811012 xEV_Bms_IsolDetDeactFuncSta "xEV_Isolation Detection Circuit Deactivate Function Status (GDS Function)";
CM_ SG_ 2344811012 xEV_Bms_CellBalDeactFuncSta "xEV_Cell Balancing Deactivate Function Status (GDS Function)";
CM_ SG_ 2344811012 EV_V2XDischrgLimSocVal_SYNC "Feedback SOC of  V2X discharge limitation for sync by BMS";
CM_ SG_ 2344811012 xEV_BMS_SOC_2nd "2nd SOC for NEV (Unit 0.05%)";
CM_ BO_ 2382595073 "[PE] Periodic and On Event";
CM_ SG_ 2382595073 DATC_Crc7Val "DATC_CyclicRedundancyCheck7Value";
CM_ SG_ 2382595073 DATC_AlvCnt7Val "DATC_AliveCounter7Value";
CM_ SG_ 2382595073 DATC_FrDrvBlwDis "DATC_FrontDriverBlowerDisplay";
CM_ SG_ 2382595073 DATC_FrPsBlwDis "DATC_FrontPassengerBlowerDisplay";
CM_ SG_ 2382595073 DATC_HeatDis "DATC_HeatDisplay";
CM_ SG_ 2382595073 DATC_EVScrnDis "DATC_EVScreenDisplay";
CM_ SG_ 2382595073 DATC_DrvOnlyDis "DATC_DriverOnlyDisplay";
CM_ SG_ 2382595073 DATC_FrDrvBlwAutoDis "BLOWER AUTO Symbol display signal";
CM_ SG_ 2382595073 DATC_DiagCodeDis "DATC_DiagnosisCodeDisplay";
CM_ SG_ 2382595073 DATC_RrChgReqDis "DATC_RearChangeRequestDisplay";
CM_ SG_ 2382595073 DATC_RrClmtScrnDis "DATC_RearClimateScreenDisplay";
CM_ SG_ 2382595073 DATC_AUTOStep "This signal indicates AUTO step status in case Multi Auto Blower type.";
CM_ SG_ 2382595073 DATC_IntakeDis "This signal indicates intake indicator & display";
CM_ SG_ 2382595073 DATC_MultiAirModSta "This signal indicates MultiAirModeStatus";
CM_ BO_ 2365803009 "[P] Periodic";
CM_ SG_ 2365803009 DATC_Crc16Val "DATC_CyclicRedundancyCheck16Value";
CM_ SG_ 2365803009 DATC_AlvCnt16Val "DATC_AliveCounter16Value";
CM_ SG_ 2365803009 DATC_SwVer1 "this signal indicates DATC Software Version to display on H_U";
CM_ SG_ 2365803009 DATC_SwVer2 "This signal indicates DATC software vertion to display on H_U";
CM_ SG_ 2365803009 DATC_Typ2 "DATC_Type2";
CM_ BO_ 2365803010 "[P] Periodic";
CM_ SG_ 2365803010 DATC_SwVer4 "this signal indicates DATC Detail Software Version";
CM_ SG_ 2365803010 DATC_SwVer5 "this signal indicates DATC Detail Software Version";
CM_ BO_ 2365803011 "[P] Periodic";
CM_ BO_ 2365803012 "[P] Periodic";
CM_ BO_ 1174 "[PE] Periodic and On Event";
CM_ SG_ 1174 Drv_SHVU_SeatOptSta "Drv Seat Heater/Vent option info";
CM_ SG_ 1174 Drv_SHVU_HtSwHiIndSta "Drv Seat Heater Switch High Indicator Status";
CM_ SG_ 1174 Drv_SHVU_HtSwMidIndSta "Drv Seat Heater Switch Mid Indicator Status";
CM_ SG_ 1174 Drv_SHVU_HtSwLowIndSta "Drv Seat Heater Switch Low Indicator Status";
CM_ SG_ 1174 Drv_SHVU_VntSwHiIndSta "Drv Seat Vent Switch High Indicator Status";
CM_ SG_ 1174 Drv_SHVU_VntSwMidIndSta "Drv Seat Vent Switch Mid Indicator Status";
CM_ SG_ 1174 Drv_SHVU_VntSwLowIndSta "Drv Seat Vent Switch Low Indicator Status";
CM_ SG_ 1174 Drv_SHVU_HtBlcUSMSta "Hetaer Balance Driver USM R vaule";
CM_ SG_ 1174 Drv_SHVU_SeatHtOperSta "Drv Seat Heater/Vent current operation state";
CM_ SG_ 1174 Drv_SHVU_HtSwHiIndSta_RHD "Drv Seat Heater Switch High Indicator Status(RHD)";
CM_ SG_ 1174 Drv_SHVU_HtSwMidIndSta_RHD "Drv Seat Heater Switch Mid Indicator Status(RHD)";
CM_ SG_ 1174 Drv_SHVU_HtSwLowIndSta_RHD "Drv Seat Heater Switch Low Indicator Status(RHD)";
CM_ SG_ 1174 Drv_SHVU_VntSwHiIndSta_RHD "Drv Seat Vent Switch High Indicator Status(RHD)";
CM_ SG_ 1174 Drv_SHVU_VntSwMidIndSta_RHD "Drv Seat Vent Switch Mid Indicator Status(RHD)";
CM_ SG_ 1174 Drv_SHVU_VntSwLowIndSta_RHD "Drv Seat Vent Switch Low Indicator Status(RHD)";
CM_ SG_ 1174 Drv_SHVU_HtBlcUSMSta_RHD "Hetaer Balance Driver USM R vaule(RHD)";
CM_ BO_ 1179 "[EC] On Event and On Change";
CM_ SG_ 1179 Drv_SHVU_SeatEcoSta "Driver Seat Eco+ Mode Status";
CM_ SG_ 1179 SHVU_Drv_Beep1Sound "SHVU_FR Driver's Seat Heater or Ventilation Switch input Beep Request";
CM_ SG_ 1179 SHVU_CtrlScreenDis "Request AVN screen change for controlling Seat Heater or Ventilation";
CM_ BO_ 1189 "[PE] Periodic and On Event";
CM_ SG_ 1189 C_RLTiltUpSw_HU "2nd Left side seat Moving control : Tilt Up";
CM_ SG_ 1189 C_RRTiltDownSw_HU "2nd Right side seat Moving control : Tilt Down";
CM_ SG_ 1189 C_RRTiltUpSw_HU "2nd Right side seat Moving control : Tilt Up";
CM_ SG_ 1189 C_RLRclBwdSw_HU "2nd Left side seat Moving control :Recline Backward";
CM_ SG_ 1189 C_RLRclFwdSw_HU "2nd Left side seat Moving control : Recline Forward";
CM_ SG_ 1189 C_RLFldSw_HU "2nd Left side seat folding control : Folding";
CM_ SG_ 1189 C_RRRclBwdSw_HU "2nd Right side seat Moving control :Recline Backward";
CM_ SG_ 1189 C_RRRclFwdSw_HU "2nd Right side seat Moving control :Recline Forward";
CM_ SG_ 1189 C_TLHrestFldSw_HU "3rdLeft side seat Headrest folding control : Folding";
CM_ SG_ 1189 C_TRHrestFldSw_HU "3rd Right side seat Headrest folding control : Folding";
CM_ SG_ 1189 C_RLRlxSW_HU "2nd Left side seat Moving control : Relax mode";
CM_ SG_ 1189 C_RRRlxSW_HU "2nd Right side seat Moving control : Relax mode";
CM_ SG_ 1189 C_TLFldSw_HU "3rd Left side seat folding control : Folding";
CM_ SG_ 1189 C_TRFldSw_HU "3rd Right side seat folding control : Folding";
CM_ SG_ 1189 C_RRFldSw_HU "2nd Right side seat folding control : Folding";
CM_ SG_ 1189 C_RLTiltDownSw_HU "2nd Left side seat Moving control : Tilt Down";
CM_ BO_ 1185 "[EC] On Event and On Change";
CM_ SG_ 1185 C_AstWindowCmdAVN "This signal indicates AST Window Open/Close Command";
CM_ SG_ 1185 C_RrDefoggerCmdAVN "This signal indicates Rear Defogger Button Command";
CM_ SG_ 1185 C_RRWindowCmdAVN "This signal indicates RR Window Open/Close Command";
CM_ SG_ 1185 C_RLWindowCmdAVN "This signal indicates RL Window Open/Close Command";
CM_ SG_ 1185 C_BlindCmdAVN "This signal indicates Sunroof Blind Open/Close Command";
CM_ SG_ 1185 C_GlassCmdAVN "This signal indicates Sunroof Glass Open/Close Command";
CM_ SG_ 1185 C_DrvWindowCmdAVN "This signal indicates DRV Window Open/Close Command";
CM_ SG_ 1185 C_PTGCNTLCmdAVN "This signal indicates PowerTailgate Open/Close  Command";
CM_ BO_ 1186 "[EC] On Event and On Change";
CM_ SG_ 1186 C_RemoteWdwCMDHU "Signal for control window (TMS), HI only";
CM_ SG_ 1186 C_EsyAcsProfileID_HU "This signal indicates the current detected profile ID by smartphone APP.
(The drv seat move to the easy access position of the detected profile ID when receive the signal)";
CM_ SG_ 1186 C_TeleDefoggerHeatingCmdIBOX "'Command for Remote Heating
(Rear Window, Side Mirror)";
CM_ SG_ 1186 C_TeleFrontHeatingCmdIBOX "Command for Remote Heating (Front Window)";
CM_ SG_ 1186 HU_CDMOpenCmd "Command for CDM open/close";
CM_ SG_ 1186 C_PreCrankReq "Command for B-CAN wake up signal
(Need to send this signal before other remote commands)";
CM_ SG_ 1186 C_TeleAstSeatOpCmdIBOX "Command for Remote Seat Heat/Vent control (Passenger)";
CM_ SG_ 1186 C_TeleDrvSeatOpCmdIBOX "Command for Remote Seat Heat/Vent control (Driver)";
CM_ SG_ 1186 C_TeleRRSeatOpCmdIBOX "Command for Remote Seat Heat/Vent control (Rear Right)";
CM_ SG_ 1186 C_TeleRLSeatOpCmdIBOX "Command for Remote Seat Heat/Vent control (Rear Left)";
CM_ SG_ 1186 C_HazardFromCCS "Command for Remote Hazard";
CM_ SG_ 1186 C_PanicFromCCS "Command for Remote Panic (Only for USA)";
CM_ SG_ 1186 C_CtrlDrUnlockRlyCCS "Command for Remote Door UnLock";
CM_ SG_ 1186 C_CtrlDrLockRlyCCS "Command for Remote Door Lock";
CM_ BO_ 1193 "[EC] On Event and On Change";
CM_ SG_ 1193 C_PTGMNValueSet "Request to set PTGM Mode";
CM_ SG_ 1193 CF_AVN_PSMNValueSet "This signal is used for a request to set the value of UMS Menus. This signal requests to set Seat Easy Access Mode. When this signal change, the message is sent 3 times.";
CM_ SG_ 1193 C_HfreeTrunkTgNValueSet "Request to set Smart Trunk/Tailgate Mode";
CM_ SG_ 1193 CF_AVN_TrfChgSet "This signal is used for a request to set the value of UMS Menus. This signal requests to set Traffic Change Mode. When this signal change, the message is sent 3 times.";
CM_ SG_ 1193 CF_AVN_SCMNValueSet "Request to set Steering Easy Access mode";
CM_ SG_ 1193 CF_AVN_ADrUNValueSet "Request to set Auto Door Unlock Mode";
CM_ SG_ 1193 CF_AVN_OTTurnNValueSet "This signal is used for a request current setting value of USM Menus. When this signal change, the message is sent 3 times.";
CM_ SG_ 1193 CF_Gway_WPCNValueSet "Request to set Wireless Phone Charging mode";
CM_ SG_ 1193 C_AVN_RearWiperNValueSet "Request to set Rear Wiper operation in reverse";
CM_ SG_ 1193 C_UnlockWelocomeNValueSet "Request to set Door Unlock Welcome Setting Option";
CM_ SG_ 1193 C_SmartWelocomeNValueSet "Request to set Smart Key Welcome Setting Option";
CM_ SG_ 1193 CF_AVN_PTGSpeedNValueSet "Setting Value For Power Tailgate Speed";
CM_ SG_ 1193 CR_Datc_DRSeatWheel_USM_Set "SteeringWheel USM Set";
CM_ SG_ 1193 CF_AVN_TTUnlockNValueSet "Setting Value for Two Turn Unlock";
CM_ SG_ 1193 CF_Gway_RWPCNValueSet "Rear Wireless Phone Charger ON/OFF Request";
CM_ SG_ 1193 C_PSDNValueSet "Request to set PSD Mode. USM request signal for setting Power Sliding Door.";
CM_ SG_ 1193 CF_Avn_HAPTICWARNINGNValueSet "USM request for Steering Wheel Haptic Warning";
CM_ SG_ 1193 CR_Datc_DRSeatHeat_USM_Set "Driver Seat Heat/Ventl USM Set";
CM_ SG_ 1193 C_WALNValueSet "USM Function for Walk Away Lock(WAL)";
CM_ SG_ 1193 C_ApprUnlockNValue "USM request for Approach Unlock";
CM_ SG_ 1193 CF_AVN_SEW_NEWNValueSet "Reguest to Safety Exit Warning";
CM_ SG_ 1193 CF_AVN_SEA_NEWNValueSet "Reguest to Safety Exit Assist";
CM_ SG_ 1193 CF_AVN_EscortHLNValueSet "Request to set Head Lamp Escort Option";
CM_ BO_ 1195 "[EC] On Event and On Change";
CM_ SG_ 1195 CF_AVN_CluWelcomeSnd "Request to set CLU welcome soun";
CM_ SG_ 1195 CF_AVN_CluTransmissionDisp "Request to set CLU transmission display";
CM_ SG_ 1195 CF_AVN_CluWiperLight "Request to set CLU wiper & light mode";
CM_ SG_ 1195 CF_AVN_CluRoadInfoGuide "Request to set CLU road info guidance";
CM_ SG_ 1195 CF_AVN_CluUserSettingPeriod "Request to set CLU sservice period set by user";
CM_ SG_ 1195 CF_AVN_CluAutoInitFuelEconomy "Request to set CLU auto initailizing fuel economy";
CM_ SG_ 1195 CF_AVN_CluFuelEconUnit_mi "Cluster setting status for cluster Fuel Economy Unit (mile)";
CM_ SG_ 1195 CF_AVN_CluFuelEconUnit_km "Cluster setting status for cluster Fuel Economy unit (km)";
CM_ SG_ 1195 CF_AVN_CluUserSettingDistance "Request to set CLU service distance set by user";
CM_ SG_ 1195 CF_AVN_CluRheostatLvl "Request to set CLU rheostat level";
CM_ SG_ 1195 CF_AVN_CluVoiceVolume "Request to set CLU Volume level";
CM_ SG_ 1195 CF_AVN_EVReset "Request to reset EV Service (0x1 : EV USM Reset)";
CM_ SG_ 1195 CF_AVN_UnitReset "Request to reset Unit setting";
CM_ SG_ 1195 CF_AVN_IcyRoadWarn "Request to set CLU icy road warning";
CM_ SG_ 1195 CF_AVN_CluServiceReminderReset "Request to reset CLU service reminder";
CM_ SG_ 1195 CF_AVN_CluUSMReset "Request to reset all USM service";
CM_ SG_ 1195 CF_AVN_CluServiceReminderSet "Request to set CLU service notification";
CM_ BO_ 1196 "[EC] On Event and On Change";
CM_ SG_ 1196 C_HCIMSWeightNValueSet "This signal is used for Healthcare IMS to input user's weight";
CM_ SG_ 1196 C_HCIMSSitHeightNValueSet "This signal is used for Healthcare IMS to input user's sitting height";
CM_ SG_ 1196 CF_AVN_BodySpprtSet "This signal is for the seat body support USM";
CM_ SG_ 1196 CF_AVN_AirSptTimeNValueSet "This signal is for the seat massage function time setting";
CM_ SG_ 1196 CF_AVN_AirSptStrNValue "This signal is for the seat massage intensity USM";
CM_ SG_ 1196 CF_AVN_SeatDrvModNValueSet "This signal is for the auto seat-drivemode user setting menu";
CM_ SG_ 1196 C_HCIMSHeightNvalueSet "This signal is used for Healthcare IMS to input user's height";
CM_ SG_ 1196 CF_AVN_CushSoftNValueSet "This signal is for the cushsoftness setting";
CM_ SG_ 1196 AVN_Usm_CluFuelEconomySet "RG3 ÀÌÈÄ ´ëÈ­¸é Å¬·¯½ºÅÍ Àû¿ë½Ã º» »ç¾çÀ¸·Î Æò±Õ¿¬ºñ ÀÚµ¿ ÃÊ±âÈ­ ±â´É Àû¿ë";
CM_ SG_ 1196 CF_AVN_HCIMSButtonCommand "User's input value in healthcare IMS mode";
CM_ BO_ 1167 "[PE] Periodic and On Event";
CM_ SG_ 1167 ICU_Crc11Val "ICU_CyclicRedundancyCheck11Value";
CM_ SG_ 1167 Bat_dischrg "Battery discharge notification flag #2G# Bat_dischrg";
CM_ SG_ 1167 ICU_AlvCnt11Val "ICU_AliveCounter11Value";
CM_ SG_ 1167 Batt_SoCWarningValue "Value of SoC warning level. ##2G## -  - Batt_SoCWarningValue";
CM_ SG_ 1167 ICU_BattAutoCutPreWrng "This is a warning signal before blocking the dark current of the ICU by the battery SOC.";
CM_ SG_ 1167 IGN_AutoOff_WarnSta_CLU "this signal is defined as the warning signal related with battery discharge";
CM_ SG_ 1167 PDC_BatPwrStateClassA "Battery Power State ClassA";
CM_ SG_ 1167 PDC_BatPwrStateClassB "Battery Power State ClassB";
CM_ SG_ 1167 PDC_BatPwrStateClassC "Battery Power State ClassC";
CM_ SG_ 1167 IGN_AutoOff_WarnSta "this signal is defined as the warning signal related with battery discharge";
CM_ BO_ 1171 "[PE] Periodic and On Event";
CM_ SG_ 1171 RLPSM_SWVerMajor1 "First Word(ASCII) in RLPSM S/W Ver";
CM_ SG_ 1171 RLPSM_SWVerMinor2 "Third Word(ASCII) in RLPSM S/W Ver";
CM_ SG_ 1171 RLPSM_SWVerMinor1 "Second Word(ASCII) in RLPSM S/W Ver";
CM_ BO_ 1181 "[EC] On Event and On Change";
CM_ SG_ 1181 RL_SHVU_SeatEcoSta "Rear LH Seat Eco+ Mode Status";
CM_ BO_ 1172 "[PE] Periodic and On Event";
CM_ SG_ 1172 RRPSM_SWVerMajor1 "First Word(ASCII) in RRPSM S/W Ver";
CM_ SG_ 1172 RRPSM_SWVerMinor2 "Third Word(ASCII) in RRPSM S/W Ver";
CM_ SG_ 1172 RRPSM_SWVerMinor1 "Second Word(ASCII) in RRPSM S/W Ver";
CM_ BO_ 1182 "[EC] On Event and On Change";
CM_ SG_ 1182 RR_SHVU_SeatEcoSta "Rear RH Seat Eco+ Mode Status";
CM_ BO_ 208 "[PE] Periodic and On Event";
CM_ SG_ 208 RR_SHVU_DTCdisplay "0x00: DTC is not exist(Fail is not exist)/0x01:IGN2 Fuse Open Detection/0x02:Switch Input Detection at Same Time/0x03:NTC/Heating wire Open Detection/0x04:NTC+/NTC- Terminal Short Detection/0x05:NTC+/Heater+ Terminal Short Detection/0x06:NTC+/Heater-, Heater+/Heater-, Heater+/NTC- Terminal Short Detection/0x07:NTC+/Heater- Wiring Short Detection/0x08:NTC+/Heater-, Heater+/Heater-, Heater+/NTC- Wiring Short Detection/0x09:Target Temperature Dissatisfied/0x0A:Blower+/Blower- Short, Blower+/Blower Speed, Blower-/Blower Speed Wiring Short Detection/0x0B:Blower+/Blower RPM, Blower-/Blower RPM, Blower Speed/Blower RPM Short Detection/0x0C:Blower+, Blower-, Blower Speed Signal open Detection/0x0D:Blower RPM signal Open Detection/0x0E~0xFD:Unused/0xFE:No Display/0xFF:Invalid";
CM_ SG_ 208 RR_SHVU_DiagMode "0x0:Default/0x1:DTC Mode/0x2:Normal Mode/0x3:Invalid";
CM_ BO_ 761 "[PE] Periodic and On Event";
CM_ SG_ 761 SBCM_AST_Crc3Val "SBCM_AST_CyclicRedundancyCheck3Value";
CM_ SG_ 761 SBCM_AST_AlvCnt3Val "SBCM_AST_AliveCounter3Value";
CM_ SG_ 761 Mirror_RHVerPosVal "RH Outside Mirror Vertical Position sensor value";
CM_ SG_ 761 Mirror_RHHorPosVal "RH Outside Mirror Horizontal Position sensor value";
CM_ BO_ 758 "[PE] Periodic and On Event";
CM_ SG_ 758 SBCM_DRV_Crc2Val "SBCM_DRV_CyclicRedundancyCheck2Value";
CM_ SG_ 758 DoorLock_CtrlDrLkUnLkSwSta_SBCM "Central Door Lock/Unlock Switch State";
CM_ SG_ 758 SBCM_DRV_AlvCnt2Val "SBCM_DRV_AliveCounter2Value";
CM_ SG_ 758 ECMMRR_PLUS "ECM Voltage value";
CM_ SG_ 758 Mirror_LHVerPosVal "LH Outside Mirror Vertical Position sensor value";
CM_ SG_ 758 Mirror_LHHorPosVal "LH Outside Mirror Horizontal Position Sensor Voltage";
CM_ BO_ 763 "[PE] Periodic and On Event";
CM_ SG_ 763 SBCM_DRV_Crc3Val "SBCM_DRV_CyclicRedundancyCheck3Value";
CM_ SG_ 763 CDM_TypeOption "CDM_HS_OptionType";
CM_ SG_ 763 SBCM_DRV_AlvCnt3Val "SBCM_DRV_AliveCounter3Value";
CM_ SG_ 763 CDM_ImmeChgSw_SBCM "State of Immediate Charging Switch";
CM_ SG_ 763 CDM_OpnClsState_SBCM "CDM_HS_ OpenCloseState";
CM_ SG_ 763 CDM_WarnMsg_SBCM "CDM_HS_WarningMessage";
CM_ SG_ 763 CDM_CmdStatus_SBCM "CDM_HS_CommandStatus";
CM_ SG_ 763 Hood_TypeOption "E-Hood_Option Type";
CM_ BO_ 742 "[PE] Periodic and On Event";
CM_ SG_ 742 SGU_FltSta "It indicates if SGU is normal or fault";
CM_ SG_ 742 SGU_BlindOnOffSet "It indicates smart glass user setting for roll blind operation.";
CM_ SG_ 742 SGU_FltVal "It indicates details of SGU fault status";
CM_ SG_ 742 SGU_Roof_OprLv "It indicates tranmittance of Roof Smart Glass";
CM_ SG_ 742 SGU_2ndLeftDoor_OprLv "It indicates tranmittance of 2nd Row Left Door Smart Glass";
CM_ SG_ 742 SGU_2ndRightDoor_OprLv "It indicates transmittance of 2nd Row Right Door Smart Glass";
CM_ SG_ 742 SGU_3rdLeftDoor_OprLv "It Indicates transmittance of 3rd Row Left Door Smart Glass";
CM_ SG_ 742 SGU_3rdRightDoor_OprLv "It Indicates transmittance of 3rd Row Right Door Smart Glass";
CM_ SG_ 742 SGU_RearWindow_OprLv "It indicates transmittance of Rear Window Smart Glass";
CM_ SG_ 742 SGU_OprLvSet "It indicates Smart Glass Operation Level Set";
CM_ SG_ 742 SGU_RdySta "It indicates if SGU is ready or not to operate smart glass";
BA_DEF_ BO_ "DiagState" ENUM "No","Yes" ;
BA_DEF_ BO_ "DiagResponse" ENUM "No","Yes" ;
BA_DEF_ BO_ "DiagRequest" ENUM "No","Yes" ;
BA_DEF_ BO_ "TpMessage" ENUM "No","Yes" ;
BA_DEF_ BO_ "UsrMsgIDSforwardDeviation" INT 0 100 ;
BA_DEF_ BO_ "UsrMsgIDSbackwardDeviation" INT 50 1000 ;
BA_DEF_ BO_ "GenMsgCycleTime" INT 0 2000 ;
BA_DEF_ BO_ "GenMsgStartDelayTime" INT 0 2000 ;
BA_DEF_ BO_ "GenMsgSendType" ENUM "Cyclic","NoMsgSendType" ;
BA_DEF_ BO_ "GenMsgCycleTimeFast" INT 0 500 ;
BA_DEF_ BO_ "GenMsgDelayTime" INT 0 20 ;
BA_DEF_ BO_ "GenMsgILSupport" ENUM "No","Yes" ;
BA_DEF_ BO_ "GenMsgNrOfRepetition" INT 0 3 ;
BA_DEF_ BO_ "NmMessage" ENUM "No","Yes" ;
BA_DEF_ BO_ "NWM-Botschaft" ENUM "No","Yes" ;
BA_DEF_ BO_ "TpTxIndex" INT 0 255 ;
BA_DEF_ BO_ "VFrameFormat" ENUM "StandardCAN","ExtendedCAN","reserved","reserved","reserved","reserved","reserved","reserved","reserved","reserved","reserved","reserved","reserved","reserved","StandardCAN_FD","ExtendedCAN_FD" ;
BA_DEF_ SG_ "UserSigValidity" ENUM "B+","ACC","IG","IG1","IG2","IG3","IG1 or IG2","IG1 or IG3","Undef" ;
BA_DEF_ SG_ "TimeoutValue" STRING ;
BA_DEF_ SG_ "UsrSigPurpose" ENUM "Undef","FN","DIAG","DIAG(Req)","DIAG(Res)","DIAG(Phy)","DEV","CCP(Req)","CCP(Res)","NM","TP" ;
BA_DEF_ SG_ "GenSigStartValue" INT 0 1215752192 ;
BA_DEF_ SG_ "NetworkRequest" ENUM "Yes","No" ;
BA_DEF_ SG_ "NetworkRequestHoldingTime" INT 0 65535 ;
BA_DEF_ SG_ "Description" STRING ;
BA_DEF_ SG_ "Version" STRING ;
BA_DEF_ SG_ "GenSigEnvVarType" ENUM "Int","Float","Undef" ;
BA_DEF_ SG_ "GenSigSendType" ENUM "Cyclic","OnWrite","OnWriteWithRepetition","OnChange","OnChangeWithRepetition","IfActive","IfActiveWithRepetition","NoSigSendType","OnChangeAndIfActive","OnChangeAndIfActiveWithRepetition" ;
BA_DEF_ SG_ "GwSigLatencyTime" INT 0 65536 ;
BA_DEF_ SG_ "GwSigMissingSourceType" ENUM "Undef","OldValue","DefaultValue","InitialValue" ;
BA_DEF_ SG_ "NWM-WakeupAllowed" ENUM "<n.a.>" ;
BA_DEF_ SG_ "RoutingFactor" INT 1 1215752192 ;
BA_DEF_REL_ BU_SG_REL_ "GenSigTimeoutTime" INT 0 7000 ;
BA_DEF_DEF_ "DiagState" "No" ;
BA_DEF_DEF_ "DiagResponse" "No" ;
BA_DEF_DEF_ "DiagRequest" "No" ;
BA_DEF_DEF_ "TpMessage" "No" ;
BA_DEF_DEF_ "UsrMsgIDSforwardDeviation" 10 ;
BA_DEF_DEF_ "UsrMsgIDSbackwardDeviation" 100 ;
BA_DEF_DEF_ "GenMsgCycleTime" 200 ;
BA_DEF_DEF_ "GenMsgStartDelayTime" 0 ;
BA_DEF_DEF_ "GenMsgSendType" "NoMsgSendType" ;
BA_DEF_DEF_ "GenMsgCycleTimeFast" 40 ;
BA_DEF_DEF_ "GenMsgDelayTime" 20 ;
BA_DEF_DEF_ "GenMsgILSupport" "Yes" ;
BA_DEF_DEF_ "GenMsgNrOfRepetition" 3 ;
BA_DEF_DEF_ "NmMessage" "No" ;
BA_DEF_DEF_ "NWM-Botschaft" "No" ;
BA_DEF_DEF_ "TpTxIndex" 0 ;
BA_DEF_DEF_ "VFrameFormat" "StandardCAN" ;
BA_DEF_DEF_ "UserSigValidity" "IG" ;
BA_DEF_DEF_ "TimeoutValue" "" ;
BA_DEF_DEF_ "UsrSigPurpose" "FN" ;
BA_DEF_DEF_ "GenSigStartValue" 0 ;
BA_DEF_DEF_ "NetworkRequest" "No" ;
BA_DEF_DEF_ "NetworkRequestHoldingTime" 0 ;
BA_DEF_DEF_ "Description" "" ;
BA_DEF_DEF_ "Version" "" ;
BA_DEF_DEF_ "GenSigEnvVarType" "Undef" ;
BA_DEF_DEF_ "GenSigSendType" "NoSigSendType" ;
BA_DEF_DEF_ "GwSigLatencyTime" 40 ;
BA_DEF_DEF_ "GwSigMissingSourceType" "Undef" ;
BA_DEF_DEF_ "NWM-WakeupAllowed" "<n.a.>" ;
BA_DEF_DEF_ "RoutingFactor" 1 ;
BA_DEF_DEF_REL_ "GenSigTimeoutTime" 500 ;
BA_ "GenMsgCycleTime" BO_ 223 0;
BA_ "Description" SG_ 223 ALBCU_SmartCtrl_1h "Smart Posture Adjust AVN Display (1hr)";
BA_ "GenSigSendType" SG_ 223 ALBCU_SmartCtrl_1h 4;
BA_ "UserSigValidity" SG_ 223 ALBCU_SmartCtrl_1h 1;
BA_REL_ "GenSigTimeoutTime" BU_SG_REL_ CGW_CCU SG_ 223 ALBCU_SmartCtrl_1h 0;
BA_ "RoutingFactor" SG_ 223 ALBCU_SmartCtrl_1h 0;
BA_ "Version" SG_ 223 ALBCU_SmartCtrl_1h "20.10.02";
BA_ "Description" SG_ 223 ALBCU_SmartCtrl_2h "Smart Posture Adjust AVN Display (2hr)";
BA_ "GenSigSendType" SG_ 223 ALBCU_SmartCtrl_2h 4;
BA_ "UserSigValidity" SG_ 223 ALBCU_SmartCtrl_2h 1;
BA_REL_ "GenSigTimeoutTime" BU_SG_REL_ CGW_CCU SG_ 223 ALBCU_SmartCtrl_2h 0;
BA_ "RoutingFactor" SG_ 223 ALBCU_SmartCtrl_2h 0;
BA_ "Version" SG_ 223 ALBCU_SmartCtrl_2h "20.10.02";
BA_ "Description" SG_ 223 ALBCU_SmartCtrl_Status "Smart Posture Adjust 2nd Interlocked Move AVN popup request";
BA_ "GenSigSendType" SG_ 223 ALBCU_SmartCtrl_Status 4;
BA_ "UserSigValidity" SG_ 223 ALBCU_SmartCtrl_Status 1;
BA_REL_ "GenSigTimeoutTime" BU_SG_REL_ CGW_CCU SG_ 223 ALBCU_SmartCtrl_Status 0;
BA_ "RoutingFactor" SG_ 223 ALBCU_SmartCtrl_Status 0;
BA_ "Version" SG_ 223 ALBCU_SmartCtrl_Status "20.10.02";
BA_ "GenMsgCycleTime" BO_ 1180 0;
BA_ "Description" SG_ 1180 SHVU_Ast_Beep1Sound "Play touch beep sound one time

Beep sound on/off

Default : Off

Goes On when play beep sound";
BA_ "GenSigSendType" SG_ 1180 SHVU_Ast_Beep1Sound 4;
BA_ "UserSigValidity" SG_ 1180 SHVU_Ast_Beep1Sound 3;
BA_REL_ "GenSigTimeoutTime" BU_SG_REL_ CGW_CCU SG_ 1180 SHVU_Ast_Beep1Sound 0;
BA_ "Version" SG_ 1180 SHVU_Ast_Beep1Sound "20.01.02";
BA_ "Description" SG_ 1180 Ast_SHVU_SeatEcoSta "Ast ½ÃÆ® ¿¡ÄÚÇÃ·¯½º ¸ðµå ÁøÀÔ Á¤º¸";
BA_ "GenSigSendType" SG_ 1180 Ast_SHVU_SeatEcoSta 4;
BA_ "UserSigValidity" SG_ 1180 Ast_SHVU_SeatEcoSta 3;
BA_REL_ "GenSigTimeoutTime" BU_SG_REL_ CGW_CCU SG_ 1180 Ast_SHVU_SeatEcoSta 0;
BA_ "NetworkRequest" SG_ 1180 Ast_SHVU_SeatEcoSta 0;
BA_ "NetworkRequestHoldingTime" SG_ 1180 Ast_SHVU_SeatEcoSta 5000;
BA_ "Version" SG_ 1180 Ast_SHVU_SeatEcoSta "20.01.01";
BA_ "GenMsgSendType" BO_ 255 0;
BA_ "Description" SG_ 255 BCM_Crc20Val "The data area for CRC calculation is based on the data length (DLC) of the message DB.

The CRC shall be calculated over the entire data block (excluding the CRC bytes) including the user data, alive counter and Data ID 

 

- CRC Polynomial (0x1D) , Initial Value : 0x00, XOR value : 0xFF, Data ID Mode : Both, Data ID : Message ID + 0xF800 

- The initial value is for CRC calculation and the message should be sent with the calculated result value. 

The mathematical expression to 8 bit CRC polynomial is given here. G(x) = x8 + x4 + x3 + x2 + 1";
BA_ "GenSigSendType" SG_ 255 BCM_Crc20Val 4;
BA_ "GenSigStartValue" SG_ 255 BCM_Crc20Val 255;
BA_ "UserSigValidity" SG_ 255 BCM_Crc20Val 0;
BA_ "Version" SG_ 255 BCM_Crc20Val "20.08.01";
BA_ "Description" SG_ 255 BCM_AlvCnt20Val "For the first transmission request for a data element the counter shall be initialized with 0 and shall be incremented by 1

for every subsequent send request. When the counter reaches the maximum value(0xE), then it shall restart with 0 for the next send request";
BA_ "GenSigSendType" SG_ 255 BCM_AlvCnt20Val 4;
BA_ "UserSigValidity" SG_ 255 BCM_AlvCnt20Val 0;
BA_ "Version" SG_ 255 BCM_AlvCnt20Val "20.08.01";
BA_ "Description" SG_ 255 BckGls_RrGlsHtdOnCmd "Rear Glass Heated Command";
BA_ "GenSigSendType" SG_ 255 BckGls_RrGlsHtdOnCmd 4;
BA_ "UserSigValidity" SG_ 255 BckGls_RrGlsHtdOnCmd 0;
BA_ "NetworkRequest" SG_ 255 BckGls_RrGlsHtdOnCmd 0;
BA_ "NetworkRequestHoldingTime" SG_ 255 BckGls_RrGlsHtdOnCmd 5000;
BA_ "Version" SG_ 255 BckGls_RrGlsHtdOnCmd "21.09.05";
BA_ "Description" SG_ 255 Wndshld_FrtGlsHtdOnCmd "Front Heated Glass Command";
BA_ "GenSigSendType" SG_ 255 Wndshld_FrtGlsHtdOnCmd 4;
BA_ "UserSigValidity" SG_ 255 Wndshld_FrtGlsHtdOnCmd 0;
BA_ "NetworkRequest" SG_ 255 Wndshld_FrtGlsHtdOnCmd 0;
BA_ "NetworkRequestHoldingTime" SG_ 255 Wndshld_FrtGlsHtdOnCmd 5000;
BA_ "Version" SG_ 255 Wndshld_FrtGlsHtdOnCmd "20.08.02";
BA_ "Description" SG_ 255 Mirror_MirFldOpt "Outside Mirror Electric Fold Option Signal";
BA_ "GenSigSendType" SG_ 255 Mirror_MirFldOpt 4;
BA_ "UserSigValidity" SG_ 255 Mirror_MirFldOpt 0;
BA_ "NetworkRequest" SG_ 255 Mirror_MirFldOpt 0;
BA_ "NetworkRequestHoldingTime" SG_ 255 Mirror_MirFldOpt 5000;
BA_ "Version" SG_ 255 Mirror_MirFldOpt "21.04.00";
BA_ "Description" SG_ 255 Window_AsstPwrWdwSunroofEnblSta "Assist Power Window And Sunroof Enable";
BA_ "GenSigSendType" SG_ 255 Window_AsstPwrWdwSunroofEnblSta 4;
BA_ "UserSigValidity" SG_ 255 Window_AsstPwrWdwSunroofEnblSta 0;
BA_REL_ "GenSigTimeoutTime" BU_SG_REL_ RCM SG_ 255 Window_AsstPwrWdwSunroofEnblSta 1500;
BA_ "NetworkRequest" SG_ 255 Window_AsstPwrWdwSunroofEnblSta 0;
BA_ "NetworkRequestHoldingTime" SG_ 255 Window_AsstPwrWdwSunroofEnblSta 5000;
BA_ "Version" SG_ 255 Window_AsstPwrWdwSunroofEnblSta "20.08.02";
BA_ "Description" SG_ 255 Window_RrPwrWdwEnblSta "Rear Power Window Enable";
BA_ "GenSigSendType" SG_ 255 Window_RrPwrWdwEnblSta 4;
BA_ "UserSigValidity" SG_ 255 Window_RrPwrWdwEnblSta 0;
BA_ "NetworkRequest" SG_ 255 Window_RrPwrWdwEnblSta 0;
BA_ "NetworkRequestHoldingTime" SG_ 255 Window_RrPwrWdwEnblSta 5000;
BA_ "Version" SG_ 255 Window_RrPwrWdwEnblSta "20.08.02";
BA_ "Description" SG_ 255 Window_RrPwrWdwLkInd "RearPpower Window Lock Indicator Command";
BA_ "GenSigSendType" SG_ 255 Window_RrPwrWdwLkInd 4;
BA_ "UserSigValidity" SG_ 255 Window_RrPwrWdwLkInd 0;
BA_ "NetworkRequest" SG_ 255 Window_RrPwrWdwLkInd 0;
BA_ "NetworkRequestHoldingTime" SG_ 255 Window_RrPwrWdwLkInd 5000;
BA_ "Version" SG_ 255 Window_RrPwrWdwLkInd "20.08.02";
BA_ "Description" SG_ 255 Window_DrvPwrWdwCmd "Driver Power Window Command";
BA_ "GenSigSendType" SG_ 255 Window_DrvPwrWdwCmd 4;
BA_ "UserSigValidity" SG_ 255 Window_DrvPwrWdwCmd 0;
BA_ "NetworkRequest" SG_ 255 Window_DrvPwrWdwCmd 0;
BA_ "NetworkRequestHoldingTime" SG_ 255 Window_DrvPwrWdwCmd 5000;
BA_ "Version" SG_ 255 Window_DrvPwrWdwCmd "21.01.06";
BA_ "Description" SG_ 255 Window_AsstPwrWdwCmd "Assist Power Window Command";
BA_ "GenSigSendType" SG_ 255 Window_AsstPwrWdwCmd 4;
BA_ "UserSigValidity" SG_ 255 Window_AsstPwrWdwCmd 0;
BA_ "NetworkRequest" SG_ 255 Window_AsstPwrWdwCmd 0;
BA_ "NetworkRequestHoldingTime" SG_ 255 Window_AsstPwrWdwCmd 5000;
BA_ "Version" SG_ 255 Window_AsstPwrWdwCmd "21.03.00";
BA_ "Description" SG_ 255 Window_RrLftPwrWdwCmd "Rear Left Power Window Command";
BA_ "GenSigSendType" SG_ 255 Window_RrLftPwrWdwCmd 4;
BA_ "UserSigValidity" SG_ 255 Window_RrLftPwrWdwCmd 0;
BA_ "NetworkRequest" SG_ 255 Window_RrLftPwrWdwCmd 0;
BA_ "NetworkRequestHoldingTime" SG_ 255 Window_RrLftPwrWdwCmd 5000;
BA_ "Version" SG_ 255 Window_RrLftPwrWdwCmd "21.03.00";
BA_ "Description" SG_ 255 Window_RrRtPwrWdwCmd "Rear Right Power Window Command";
BA_ "GenSigSendType" SG_ 255 Window_RrRtPwrWdwCmd 4;
BA_ "UserSigValidity" SG_ 255 Window_RrRtPwrWdwCmd 0;
BA_ "NetworkRequest" SG_ 255 Window_RrRtPwrWdwCmd 0;
BA_ "NetworkRequestHoldingTime" SG_ 255 Window_RrRtPwrWdwCmd 5000;
BA_ "Version" SG_ 255 Window_RrRtPwrWdwCmd "21.03.00";
BA_ "Description" SG_ 255 Mirror_FldUnfldCmd "Mirror Folding Unfolding Command";
BA_ "GenSigSendType" SG_ 255 Mirror_FldUnfldCmd 4;
BA_ "UserSigValidity" SG_ 255 Mirror_FldUnfldCmd 0;
BA_ "NetworkRequest" SG_ 255 Mirror_FldUnfldCmd 0;
BA_ "NetworkRequestHoldingTime" SG_ 255 Mirror_FldUnfldCmd 5000;
BA_ "Version" SG_ 255 Mirror_FldUnfldCmd "21.03.00";
BA_ "Description" SG_ 255 Mirror_FldCtrlSta "Mirror Fold and Folding Control State";
BA_ "GenSigSendType" SG_ 255 Mirror_FldCtrlSta 4;
BA_ "UserSigValidity" SG_ 255 Mirror_FldCtrlSta 0;
BA_ "NetworkRequest" SG_ 255 Mirror_FldCtrlSta 0;
BA_ "NetworkRequestHoldingTime" SG_ 255 Mirror_FldCtrlSta 5000;
BA_ "Version" SG_ 255 Mirror_FldCtrlSta "21.03.00";
BA_ "Description" SG_ 255 Mirror_UnFldCtrlSta "Mirror Unfold and Unfolding Control State";
BA_ "GenSigSendType" SG_ 255 Mirror_UnFldCtrlSta 4;
BA_ "UserSigValidity" SG_ 255 Mirror_UnFldCtrlSta 0;
BA_ "NetworkRequest" SG_ 255 Mirror_UnFldCtrlSta 0;
BA_ "NetworkRequestHoldingTime" SG_ 255 Mirror_UnFldCtrlSta 5000;
BA_ "Version" SG_ 255 Mirror_UnFldCtrlSta "21.03.00";
BA_ "Description" SG_ 255 Mirror_PosMnlCmd "Mirror Positioning Request";
BA_ "GenSigSendType" SG_ 255 Mirror_PosMnlCmd 4;
BA_ "UserSigValidity" SG_ 255 Mirror_PosMnlCmd 0;
BA_ "NetworkRequest" SG_ 255 Mirror_PosMnlCmd 0;
BA_ "NetworkRequestHoldingTime" SG_ 255 Mirror_PosMnlCmd 5000;
BA_ "Version" SG_ 255 Mirror_PosMnlCmd "21.03.00";
BA_ "Description" SG_ 255 Mirror_SelSwIndCmd "Mirror Select Switch Indicator Command";
BA_ "GenSigSendType" SG_ 255 Mirror_SelSwIndCmd 4;
BA_ "UserSigValidity" SG_ 255 Mirror_SelSwIndCmd 0;
BA_ "NetworkRequest" SG_ 255 Mirror_SelSwIndCmd 0;
BA_ "NetworkRequestHoldingTime" SG_ 255 Mirror_SelSwIndCmd 5000;
BA_ "Version" SG_ 255 Mirror_SelSwIndCmd "21.03.00";
BA_ "Description" SG_ 255 BCM_SafetyWdwOptTyp2 "Option Signal for Safety Window System";
BA_ "GenSigSendType" SG_ 255 BCM_SafetyWdwOptTyp2 4;
BA_ "UserSigValidity" SG_ 255 BCM_SafetyWdwOptTyp2 0;
BA_ "NetworkRequest" SG_ 255 BCM_SafetyWdwOptTyp2 0;
BA_ "NetworkRequestHoldingTime" SG_ 255 BCM_SafetyWdwOptTyp2 5000;
BA_ "Version" SG_ 255 BCM_SafetyWdwOptTyp2 "20.08.05";
BA_ "Description" SG_ 255 Mirror_LHOSMirPlyBckSta "This siganl indicates Left O/S Mirror moving state for IMS From BDC";
BA_ "GenSigSendType" SG_ 255 Mirror_LHOSMirPlyBckSta 4;
BA_ "UserSigValidity" SG_ 255 Mirror_LHOSMirPlyBckSta 0;
BA_REL_ "GenSigTimeoutTime" BU_SG_REL_ DPSU SG_ 255 Mirror_LHOSMirPlyBckSta 1500;
BA_ "NetworkRequest" SG_ 255 Mirror_LHOSMirPlyBckSta 0;
BA_ "NetworkRequestHoldingTime" SG_ 255 Mirror_LHOSMirPlyBckSta 5000;
BA_ "Version" SG_ 255 Mirror_LHOSMirPlyBckSta "21.03.00";
BA_ "Description" SG_ 255 Mirror_RHOSMirPlyBckSta "This siganl indicates Right O/S Mirror moving state for IMS From BDC";
BA_ "GenSigSendType" SG_ 255 Mirror_RHOSMirPlyBckSta 4;
BA_ "UserSigValidity" SG_ 255 Mirror_RHOSMirPlyBckSta 0;
BA_REL_ "GenSigTimeoutTime" BU_SG_REL_ DPSU SG_ 255 Mirror_RHOSMirPlyBckSta 1500;
BA_ "NetworkRequest" SG_ 255 Mirror_RHOSMirPlyBckSta 0;
BA_ "NetworkRequestHoldingTime" SG_ 255 Mirror_RHOSMirPlyBckSta 5000;
BA_ "Version" SG_ 255 Mirror_RHOSMirPlyBckSta "21.03.00";
BA_ "Description" SG_ 255 Mirror_SelSwSta "Outside Mirror Select Button Status";
BA_ "GenSigSendType" SG_ 255 Mirror_SelSwSta 4;
BA_ "UserSigValidity" SG_ 255 Mirror_SelSwSta 0;
BA_ "NetworkRequest" SG_ 255 Mirror_SelSwSta 0;
BA_ "NetworkRequestHoldingTime" SG_ 255 Mirror_SelSwSta 5000;
BA_ "Version" SG_ 255 Mirror_SelSwSta "20.12.00";
BA_ "Description" SG_ 255 BckGls_RrGlsHtdOpt "Back Glass_Rear Glass Heated Option Signal";
BA_ "GenSigSendType" SG_ 255 BckGls_RrGlsHtdOpt 4;
BA_ "UserSigValidity" SG_ 255 BckGls_RrGlsHtdOpt 0;
BA_ "Version" SG_ 255 BckGls_RrGlsHtdOpt "21.06.08";
BA_ "GenMsgSendType" BO_ 2344811009 0;
BA_ "GenMsgCycleTimeFast" BO_ 2344811009 0;
BA_ "GenMsgNrOfRepetition" BO_ 2344811009 0;
BA_ "VFrameFormat" BO_ 2344811009 1;
BA_ "Description" SG_ 2344811009 BMS_Crc2Val "The data area for CRC calculation is based on the data length (DLC) of the message DB.

The CRC shall be calculated over the entire data block (excluding the CRC bytes) including the user data, alive counter and Data ID

 

- CRC Polynomial (0x1021) , Initial Value : 0xFFFF, XOR value : 0x0000, Data ID : Message ID + 0xF800 

- The initial value is for CRC calculation and the message should be sent with the calculated result value. 

- The mathematical expression to 16 bit CRC polynomial is given here. G(x) = x16 + x12 + x5 + 1";
BA_ "GenSigStartValue" SG_ 2344811009 BMS_Crc2Val 65535;
BA_ "UserSigValidity" SG_ 2344811009 BMS_Crc2Val 3;
BA_ "RoutingFactor" SG_ 2344811009 BMS_Crc2Val 2;
BA_ "Version" SG_ 2344811009 BMS_Crc2Val "18.11.08";
BA_ "Description" SG_ 2344811009 BMS_AlvCnt2Val "For the first transmission request for a data element the counter shall be initialized with 0 and shall be incremented by 1 for every subsequent send request. 

When the counter reaches the maximum value(0xFF), then it shall restart with 0 for the next send request";
BA_ "UserSigValidity" SG_ 2344811009 BMS_AlvCnt2Val 3;
BA_ "RoutingFactor" SG_ 2344811009 BMS_AlvCnt2Val 2;
BA_ "Version" SG_ 2344811009 BMS_AlvCnt2Val "18.11.08";
BA_ "Description" SG_ 2344811009 xEV_SrvLmpReq "Service Lamp request";
BA_ "UserSigValidity" SG_ 2344811009 xEV_SrvLmpReq 7;
BA_ "RoutingFactor" SG_ 2344811009 xEV_SrvLmpReq 2;
BA_ "Version" SG_ 2344811009 xEV_SrvLmpReq "18.11.01";
BA_ "Description" SG_ 2344811009 xEV_MainRlyOnSta "Main Relay On Status";
BA_ "UserSigValidity" SG_ 2344811009 xEV_MainRlyOnSta 7;
BA_ "RoutingFactor" SG_ 2344811009 xEV_MainRlyOnSta 2;
BA_ "Version" SG_ 2344811009 xEV_MainRlyOnSta "18.11.01";
BA_ "Description" SG_ 2344811009 xEV_SysFltSta "BMS Fault";
BA_ "UserSigValidity" SG_ 2344811009 xEV_SysFltSta 7;
BA_ "RoutingFactor" SG_ 2344811009 xEV_SysFltSta 2;
BA_ "Version" SG_ 2344811009 xEV_SysFltSta "18.11.01";
BA_ "Description" SG_ 2344811009 xEV_BattRmnEnrgVal "Difference of increased or decreased battery resistance";
BA_ "UserSigValidity" SG_ 2344811009 xEV_BattRmnEnrgVal 7;
BA_ "RoutingFactor" SG_ 2344811009 xEV_BattRmnEnrgVal 2;
BA_ "Version" SG_ 2344811009 xEV_BattRmnEnrgVal "18.11.01";
BA_ "Description" SG_ 2344811009 xEV_InltTempVal "Battery Inlet Temperature";
BA_ "UserSigValidity" SG_ 2344811009 xEV_InltTempVal 7;
BA_ "RoutingFactor" SG_ 2344811009 xEV_InltTempVal 2;
BA_ "Version" SG_ 2344811009 xEV_InltTempVal "20.07.05";
BA_ "Description" SG_ 2344811009 xEV_MinBattCelVoltVal "Minimum Battery Cell Voltage";
BA_ "GenSigStartValue" SG_ 2344811009 xEV_MinBattCelVoltVal 3;
BA_ "UserSigValidity" SG_ 2344811009 xEV_MinBattCelVoltVal 7;
BA_ "RoutingFactor" SG_ 2344811009 xEV_MinBattCelVoltVal 2;
BA_ "Version" SG_ 2344811009 xEV_MinBattCelVoltVal "18.11.01";
BA_ "Description" SG_ 2344811009 xEV_MaxBattCelVoltVal "Maximum Battery Cell Voltage";
BA_ "GenSigStartValue" SG_ 2344811009 xEV_MaxBattCelVoltVal 3;
BA_ "UserSigValidity" SG_ 2344811009 xEV_MaxBattCelVoltVal 7;
BA_ "RoutingFactor" SG_ 2344811009 xEV_MaxBattCelVoltVal 2;
BA_ "Version" SG_ 2344811009 xEV_MaxBattCelVoltVal "18.11.01";
BA_ "GenMsgSendType" BO_ 2344811010 0;
BA_ "GenMsgCycleTimeFast" BO_ 2344811010 0;
BA_ "GenMsgNrOfRepetition" BO_ 2344811010 0;
BA_ "VFrameFormat" BO_ 2344811010 1;
BA_ "Description" SG_ 2344811010 xEV_BattCurrVal "xEV_Battery Current Value (CR_Bms_BatI_A)";
BA_ "UserSigValidity" SG_ 2344811010 xEV_BattCurrVal 7;
BA_ "RoutingFactor" SG_ 2344811010 xEV_BattCurrVal 2;
BA_ "Version" SG_ 2344811010 xEV_BattCurrVal "18.11.01";
BA_ "Description" SG_ 2344811010 xEV_MinBattTempVal "Minimum Battery Temperature";
BA_ "UserSigValidity" SG_ 2344811010 xEV_MinBattTempVal 7;
BA_ "RoutingFactor" SG_ 2344811010 xEV_MinBattTempVal 2;
BA_ "Version" SG_ 2344811010 xEV_MinBattTempVal "18.11.01";
BA_ "Description" SG_ 2344811010 xEV_MaxBattTempVal "Maximum Battery Temperature";
BA_ "UserSigValidity" SG_ 2344811010 xEV_MaxBattTempVal 7;
BA_ "RoutingFactor" SG_ 2344811010 xEV_MaxBattTempVal 2;
BA_ "Version" SG_ 2344811010 xEV_MaxBattTempVal "18.11.01";
BA_ "Description" SG_ 2344811010 xEV_FanSpdStpSta "Battery Cooling Fan Speed Step";
BA_ "UserSigValidity" SG_ 2344811010 xEV_FanSpdStpSta 7;
BA_ "RoutingFactor" SG_ 2344811010 xEV_FanSpdStpSta 2;
BA_ "Version" SG_ 2344811010 xEV_FanSpdStpSta "18.11.01";
BA_ "Description" SG_ 2344811010 xEV_12VRlyOffAlrmReq "12V Battery Relay Off Alarm Request";
BA_ "UserSigValidity" SG_ 2344811010 xEV_12VRlyOffAlrmReq 7;
BA_ "RoutingFactor" SG_ 2344811010 xEV_12VRlyOffAlrmReq 2;
BA_ "Version" SG_ 2344811010 xEV_12VRlyOffAlrmReq "18.11.01";
BA_ "Description" SG_ 2344811010 xEV_12VRlyOnAlrmReq "12V Battery Relay On Alarm Request";
BA_ "UserSigValidity" SG_ 2344811010 xEV_12VRlyOnAlrmReq 7;
BA_ "RoutingFactor" SG_ 2344811010 xEV_12VRlyOnAlrmReq 2;
BA_ "Version" SG_ 2344811010 xEV_12VRlyOnAlrmReq "18.11.01";
BA_ "Description" SG_ 2344811010 xEV_DiagGrpVal "Diagnosis code";
BA_ "UserSigValidity" SG_ 2344811010 xEV_DiagGrpVal 7;
BA_ "RoutingFactor" SG_ 2344811010 xEV_DiagGrpVal 2;
BA_ "Version" SG_ 2344811010 xEV_DiagGrpVal "18.11.01";
BA_ "Description" SG_ 2344811010 xEV_DiagMonVal "Diagnosis data";
BA_ "UserSigValidity" SG_ 2344811010 xEV_DiagMonVal 7;
BA_ "RoutingFactor" SG_ 2344811010 xEV_DiagMonVal 2;
BA_ "Version" SG_ 2344811010 xEV_DiagMonVal "18.11.01";
BA_ "Description" SG_ 2344811010 xEV_SocDis "Cluster, AVN Display SOC";
BA_ "UserSigValidity" SG_ 2344811010 xEV_SocDis 7;
BA_REL_ "GenSigTimeoutTime" BU_SG_REL_ SWRC SG_ 2344811010 xEV_SocDis 1500;
BA_ "RoutingFactor" SG_ 2344811010 xEV_SocDis 2;
BA_ "Version" SG_ 2344811010 xEV_SocDis "20.07.05";
BA_ "GenMsgSendType" BO_ 2344811011 0;
BA_ "GenMsgCycleTimeFast" BO_ 2344811011 0;
BA_ "GenMsgNrOfRepetition" BO_ 2344811011 0;
BA_ "VFrameFormat" BO_ 2344811011 1;
BA_ "Description" SG_ 2344811011 PHEV_SubInltTempVal "Sub Pack Inlet Temperature

(If MSB is 1, (PH) = 1 * (HEX) ? 256 [¡É]

else (PH) = 1 * (HEX) [¡É])";
BA_ "UserSigValidity" SG_ 2344811011 PHEV_SubInltTempVal 7;
BA_ "RoutingFactor" SG_ 2344811011 PHEV_SubInltTempVal 2;
BA_ "Version" SG_ 2344811011 PHEV_SubInltTempVal "18.11.01";
BA_ "Description" SG_ 2344811011 xEV_12VAlarmReqForICU "xEV_12V Battery Alarm Request For ICU";
BA_ "UserSigValidity" SG_ 2344811011 xEV_12VAlarmReqForICU 7;
BA_ "RoutingFactor" SG_ 2344811011 xEV_12VAlarmReqForICU 2;
BA_ "Version" SG_ 2344811011 xEV_12VAlarmReqForICU "18.11.01";
BA_ "Description" SG_ 2344811011 xEV_AuxBattChrgReq "Aux. Battery Charge Request Flag

***new signal***";
BA_ "UserSigValidity" SG_ 2344811011 xEV_AuxBattChrgReq 7;
BA_ "RoutingFactor" SG_ 2344811011 xEV_AuxBattChrgReq 2;
BA_ "Version" SG_ 2344811011 xEV_AuxBattChrgReq "19.06.00";
BA_ "Description" SG_ 2344811011 xEV_12VDarkCurrAlarmForICU "12V Battery Alarm request for ICU(CGW)";
BA_ "UserSigValidity" SG_ 2344811011 xEV_12VDarkCurrAlarmForICU 7;
BA_ "RoutingFactor" SG_ 2344811011 xEV_12VDarkCurrAlarmForICU 2;
BA_ "Version" SG_ 2344811011 xEV_12VDarkCurrAlarmForICU "18.11.01";
BA_ "Description" SG_ 2344811011 xEV_12VBatVLmt "xEV_12VBatteryVoltageLimit(CR_Bms_12V_BatV_Lmt)";
BA_ "UserSigValidity" SG_ 2344811011 xEV_12VBatVLmt 7;
BA_ "RoutingFactor" SG_ 2344811011 xEV_12VBatVLmt 2;
BA_ "Version" SG_ 2344811011 xEV_12VBatVLmt "18.11.01";
BA_ "Description" SG_ 2344811011 xEV_CharBatInfoReqForSDC "Function of determining first battery to charge (12V battery or High voltage battery)";
BA_ "UserSigValidity" SG_ 2344811011 xEV_CharBatInfoReqForSDC 7;
BA_ "RoutingFactor" SG_ 2344811011 xEV_CharBatInfoReqForSDC 2;
BA_ "Version" SG_ 2344811011 xEV_CharBatInfoReqForSDC "18.11.01";
BA_ "Description" SG_ 2344811011 xEV_ClimateOffReq "xEV_ClimateOffRequest  --Alarm flag at climate off requested (CF_Bms_ClimateOffReq)";
BA_ "UserSigValidity" SG_ 2344811011 xEV_ClimateOffReq 7;
BA_ "RoutingFactor" SG_ 2344811011 xEV_ClimateOffReq 2;
BA_ "Version" SG_ 2344811011 xEV_ClimateOffReq "18.11.01";
BA_ "Description" SG_ 2344811011 xEV_MainRlyOnRetrySta "BMS sets this Flag until BMS completes Relay ON Sequence for Relay recontact";
BA_ "UserSigValidity" SG_ 2344811011 xEV_MainRlyOnRetrySta 7;
BA_ "RoutingFactor" SG_ 2344811011 xEV_MainRlyOnRetrySta 2;
BA_ "Version" SG_ 2344811011 xEV_MainRlyOnRetrySta "18.11.01";
BA_ "Description" SG_ 2344811011 xEV_Bms_BlackBox_Data_req "For Saving BMS data set, this signal transmits to MCU";
BA_ "UserSigValidity" SG_ 2344811011 xEV_Bms_BlackBox_Data_req 7;
BA_ "RoutingFactor" SG_ 2344811011 xEV_Bms_BlackBox_Data_req 2;
BA_ "Version" SG_ 2344811011 xEV_Bms_BlackBox_Data_req "20.03.06";
BA_ "Description" SG_ 2344811011 xEV_12V_BatDchCurrLmt "xEV_12V Battery Discharge Current Limit (CR_Bms_12V_BatDchI_Lmt)";
BA_ "UserSigValidity" SG_ 2344811011 xEV_12V_BatDchCurrLmt 7;
BA_ "RoutingFactor" SG_ 2344811011 xEV_12V_BatDchCurrLmt 2;
BA_ "Version" SG_ 2344811011 xEV_12V_BatDchCurrLmt "18.11.01";
BA_ "Description" SG_ 2344811011 xEV_12VChargeReq "xEV_12VBatteryChargeRequest (for 12V battery over-discharge protection) (CF_Bms_12_ChargeReq)";
BA_ "UserSigValidity" SG_ 2344811011 xEV_12VChargeReq 7;
BA_ "RoutingFactor" SG_ 2344811011 xEV_12VChargeReq 2;
BA_ "Version" SG_ 2344811011 xEV_12VChargeReq "18.11.02";
BA_ "Description" SG_ 2344811011 xEV_BmsRomType "BMS rom type variation of Battery Pack Specification";
BA_ "UserSigValidity" SG_ 2344811011 xEV_BmsRomType 7;
BA_ "RoutingFactor" SG_ 2344811011 xEV_BmsRomType 2;
BA_ "Version" SG_ 2344811011 xEV_BmsRomType "21.01.03";
BA_ "Description" SG_ 2344811011 xEV_12V_CurrFltDetectReq "xEV_12V Battery Current Sensor Fault Detect Request";
BA_ "UserSigValidity" SG_ 2344811011 xEV_12V_CurrFltDetectReq 7;
BA_ "RoutingFactor" SG_ 2344811011 xEV_12V_CurrFltDetectReq 2;
BA_ "Version" SG_ 2344811011 xEV_12V_CurrFltDetectReq "19.01.00";
BA_ "Description" SG_ 2344811011 xEV_PRATempSnsVal_ "xEV_PRATemperatureSensorValue";
BA_ "UserSigValidity" SG_ 2344811011 xEV_PRATempSnsVal_ 7;
BA_ "RoutingFactor" SG_ 2344811011 xEV_PRATempSnsVal_ 2;
BA_ "Version" SG_ 2344811011 xEV_PRATempSnsVal_ "19.01.00";
BA_ "Description" SG_ 2344811011 xEV_PRATempSns2Val_ "xEV_PRATemperatureSensor2Value";
BA_ "UserSigValidity" SG_ 2344811011 xEV_PRATempSns2Val_ 7;
BA_ "RoutingFactor" SG_ 2344811011 xEV_PRATempSns2Val_ 2;
BA_ "Version" SG_ 2344811011 xEV_PRATempSns2Val_ "19.01.00";
BA_ "Description" SG_ 2344811011 xEV_12VRlyOnSwReq "12V relay ON switch ON status. BMS sets this Flag when 12V Relay Switch is ON.";
BA_ "UserSigValidity" SG_ 2344811011 xEV_12VRlyOnSwReq 7;
BA_ "RoutingFactor" SG_ 2344811011 xEV_12VRlyOnSwReq 2;
BA_ "Version" SG_ 2344811011 xEV_12VRlyOnSwReq "18.11.01";
BA_ "GenMsgSendType" BO_ 2344811012 0;
BA_ "GenMsgCycleTimeFast" BO_ 2344811012 0;
BA_ "GenMsgNrOfRepetition" BO_ 2344811012 0;
BA_ "VFrameFormat" BO_ 2344811012 1;
BA_ "Description" SG_ 2344811012 xEV_BattRCHTimeEst "calculated charging time by esrimated OBC output power

***HS CAN : BMS7(0x598), CR_Bms_RCHTimeEst***";
BA_ "UserSigValidity" SG_ 2344811012 xEV_BattRCHTimeEst 7;
BA_ "RoutingFactor" SG_ 2344811012 xEV_BattRCHTimeEst 2;
BA_ "Version" SG_ 2344811012 xEV_BattRCHTimeEst "19.04.06";
BA_ "Description" SG_ 2344811012 EV_DischrgCurrLimForV2X "Discharge Current Limit(for V2X)

***new signal***";
BA_ "UserSigValidity" SG_ 2344811012 EV_DischrgCurrLimForV2X 7;
BA_ "RoutingFactor" SG_ 2344811012 EV_DischrgCurrLimForV2X 2;
BA_ "Version" SG_ 2344811012 EV_DischrgCurrLimForV2X "20.04.03";
BA_ "Description" SG_ 2344811012 xEV_Bms_IsolDetDeactFuncSta "xEV_Isolation Detection Circuit Deactivate Function Status (GDS Function)";
BA_ "UserSigValidity" SG_ 2344811012 xEV_Bms_IsolDetDeactFuncSta 7;
BA_ "RoutingFactor" SG_ 2344811012 xEV_Bms_IsolDetDeactFuncSta 2;
BA_ "Version" SG_ 2344811012 xEV_Bms_IsolDetDeactFuncSta "20.06.10";
BA_ "Description" SG_ 2344811012 xEV_Bms_CellBalDeactFuncSta "xEV_Cell Balancing Deactivate Function Status (GDS Function)";
BA_ "UserSigValidity" SG_ 2344811012 xEV_Bms_CellBalDeactFuncSta 7;
BA_ "RoutingFactor" SG_ 2344811012 xEV_Bms_CellBalDeactFuncSta 2;
BA_ "Version" SG_ 2344811012 xEV_Bms_CellBalDeactFuncSta "20.06.10";
BA_ "Description" SG_ 2344811012 EV_V2XDischrgLimSocVal_SYNC "Feedback SOC of  V2X discharge limitation for sync by BMS

***New Signal***";
BA_ "UserSigValidity" SG_ 2344811012 EV_V2XDischrgLimSocVal_SYNC 7;
BA_ "RoutingFactor" SG_ 2344811012 EV_V2XDischrgLimSocVal_SYNC 2;
BA_ "Version" SG_ 2344811012 EV_V2XDischrgLimSocVal_SYNC "20.11.02";
BA_ "Description" SG_ 2344811012 xEV_BMS_SOC_2nd "2nd SOC for NEV";
BA_ "UserSigValidity" SG_ 2344811012 xEV_BMS_SOC_2nd 7;
BA_ "RoutingFactor" SG_ 2344811012 xEV_BMS_SOC_2nd 2;
BA_ "Version" SG_ 2344811012 xEV_BMS_SOC_2nd "20.03.07";
BA_ "GenMsgSendType" BO_ 2382595073 0;
BA_ "VFrameFormat" BO_ 2382595073 1;
BA_ "Description" SG_ 2382595073 DATC_Crc7Val "The data area for CRC calculation is based on the data length (DLC) of the message DB.

The CRC shall be calculated over the entire data block (excluding the CRC bytes) including the user data, alive counter and Data ID

 

- CRC Polynomial (0x1021) , Initial Value : 0xFFFF, XOR value : 0x0000, Data ID : Message ID + 0xF800 

- The initial value is for CRC calculation and the message should be sent with the calculated result value. 

- The mathematical expression to 16 bit CRC polynomial is given here. G(x) = x16 + x12 + x5 + 1";
BA_ "GenSigSendType" SG_ 2382595073 DATC_Crc7Val 4;
BA_ "GenSigStartValue" SG_ 2382595073 DATC_Crc7Val 65535;
BA_ "UserSigValidity" SG_ 2382595073 DATC_Crc7Val 3;
BA_ "Version" SG_ 2382595073 DATC_Crc7Val "18.11.08";
BA_ "Description" SG_ 2382595073 DATC_AlvCnt7Val "For the first transmission request for a data element the counter shall be initialized with 0 and shall be incremented by 1 for every subsequent send request. 

When the counter reaches the maximum value(0xFF), then it shall restart with 0 for the next send request";
BA_ "GenSigSendType" SG_ 2382595073 DATC_AlvCnt7Val 4;
BA_ "UserSigValidity" SG_ 2382595073 DATC_AlvCnt7Val 3;
BA_ "Version" SG_ 2382595073 DATC_AlvCnt7Val "18.11.08";
BA_ "Description" SG_ 2382595073 DATC_FrDrvBlwDis "This signal indicates step of Front blower Graphic.

This signal occurs when Front Blower switch(button) is selected either manually or automatically.";
BA_ "GenSigSendType" SG_ 2382595073 DATC_FrDrvBlwDis 4;
BA_ "UserSigValidity" SG_ 2382595073 DATC_FrDrvBlwDis 7;
BA_REL_ "GenSigTimeoutTime" BU_SG_REL_ ATS SG_ 2382595073 DATC_FrDrvBlwDis 1500;
BA_ "Version" SG_ 2382595073 DATC_FrDrvBlwDis "18.11.06";
BA_ "GenSigSendType" SG_ 2382595073 DATC_FrPsBlwDis 4;
BA_ "UserSigValidity" SG_ 2382595073 DATC_FrPsBlwDis 7;
BA_REL_ "GenSigTimeoutTime" BU_SG_REL_ ATS SG_ 2382595073 DATC_FrPsBlwDis 1500;
BA_ "Version" SG_ 2382595073 DATC_FrPsBlwDis "19.05.03";
BA_ "Description" SG_ 2382595073 DATC_HeatDis "This signal indicates Heat symbol Display";
BA_ "GenSigSendType" SG_ 2382595073 DATC_HeatDis 4;
BA_ "GenSigStartValue" SG_ 2382595073 DATC_HeatDis 3;
BA_ "UserSigValidity" SG_ 2382595073 DATC_HeatDis 6;
BA_REL_ "GenSigTimeoutTime" BU_SG_REL_ ATS SG_ 2382595073 DATC_HeatDis 1500;
BA_ "Version" SG_ 2382595073 DATC_HeatDis "17.11.00";
BA_ "Description" SG_ 2382595073 DATC_EVScrnDis "EV Only Screen Display";
BA_ "GenSigSendType" SG_ 2382595073 DATC_EVScrnDis 4;
BA_ "GenSigStartValue" SG_ 2382595073 DATC_EVScrnDis 3;
BA_ "UserSigValidity" SG_ 2382595073 DATC_EVScrnDis 4;
BA_ "Version" SG_ 2382595073 DATC_EVScrnDis "17.11.00";
BA_ "GenSigSendType" SG_ 2382595073 DATC_DrvOnlyDis 4;
BA_ "UserSigValidity" SG_ 2382595073 DATC_DrvOnlyDis 6;
BA_REL_ "GenSigTimeoutTime" BU_SG_REL_ ATS SG_ 2382595073 DATC_DrvOnlyDis 1500;
BA_ "Version" SG_ 2382595073 DATC_DrvOnlyDis "17.11.00";
BA_ "Description" SG_ 2382595073 DATC_FrDrvBlwAutoDis "When the Front BLOWER is operated with AUTO, it is a signal to display the AUTO symbol with the BLOWER currently in operation";
BA_ "GenSigSendType" SG_ 2382595073 DATC_FrDrvBlwAutoDis 4;
BA_ "UserSigValidity" SG_ 2382595073 DATC_FrDrvBlwAutoDis 7;
BA_ "Version" SG_ 2382595073 DATC_FrDrvBlwAutoDis "18.11.02";
BA_ "GenSigSendType" SG_ 2382595073 DATC_DiagCodeDis 4;
BA_ "UserSigValidity" SG_ 2382595073 DATC_DiagCodeDis 6;
BA_ "Version" SG_ 2382595073 DATC_DiagCodeDis "17.11.00";
BA_ "Description" SG_ 2382595073 DATC_RrChgReqDis "This signal indicates to show Climate Pop-up screen.

This signal occurs when any kinds of climate switch(button)s are selected manually.";
BA_ "GenSigSendType" SG_ 2382595073 DATC_RrChgReqDis 4;
BA_ "UserSigValidity" SG_ 2382595073 DATC_RrChgReqDis 6;
BA_ "Version" SG_ 2382595073 DATC_RrChgReqDis "17.11.00";
BA_ "Description" SG_ 2382595073 DATC_RrClmtScrnDis "This signal indicates that screen change to Climate Full screen.



This signal occurs when Climate switch(button) is selected manually.";
BA_ "GenSigSendType" SG_ 2382595073 DATC_RrClmtScrnDis 4;
BA_ "UserSigValidity" SG_ 2382595073 DATC_RrClmtScrnDis 6;
BA_REL_ "GenSigTimeoutTime" BU_SG_REL_ ATS SG_ 2382595073 DATC_RrClmtScrnDis 1500;
BA_ "Version" SG_ 2382595073 DATC_RrClmtScrnDis "17.11.00";
BA_ "Description" SG_ 2382595073 DATC_AUTOStep "This signal indicates AUTO step status in case Multi Auto Blower type.";
BA_ "GenSigSendType" SG_ 2382595073 DATC_AUTOStep 4;
BA_ "UserSigValidity" SG_ 2382595073 DATC_AUTOStep 7;
BA_REL_ "GenSigTimeoutTime" BU_SG_REL_ ATS SG_ 2382595073 DATC_AUTOStep 1500;
BA_ "Version" SG_ 2382595073 DATC_AUTOStep "18.12.08";
BA_ "Description" SG_ 2382595073 DATC_IntakeDis "This signal indicates intake indicator & display";
BA_ "GenSigSendType" SG_ 2382595073 DATC_IntakeDis 4;
BA_ "UserSigValidity" SG_ 2382595073 DATC_IntakeDis 7;
BA_REL_ "GenSigTimeoutTime" BU_SG_REL_ ATS SG_ 2382595073 DATC_IntakeDis 1500;
BA_ "Version" SG_ 2382595073 DATC_IntakeDis "18.12.08";
BA_ "Description" SG_ 2382595073 DATC_MultiAirModSta "This signal indicates MultiAirModeStatus";
BA_ "GenSigSendType" SG_ 2382595073 DATC_MultiAirModSta 4;
BA_ "UserSigValidity" SG_ 2382595073 DATC_MultiAirModSta 7;
BA_ "Version" SG_ 2382595073 DATC_MultiAirModSta "18.12.08";
BA_ "GenMsgSendType" BO_ 2365803009 0;
BA_ "GenMsgCycleTime" BO_ 2365803009 1000;
BA_ "GenMsgCycleTimeFast" BO_ 2365803009 0;
BA_ "GenMsgNrOfRepetition" BO_ 2365803009 0;
BA_ "VFrameFormat" BO_ 2365803009 1;
BA_ "Description" SG_ 2365803009 DATC_Crc16Val "The data area for CRC calculation is based on the data length (DLC) of the message DB.

The CRC shall be calculated over the entire data block (excluding the CRC bytes) including the user data, alive counter and Data ID

 

- CRC Polynomial (0x1021) , Initial Value : 0xFFFF, XOR value : 0x0000, Data ID : Message ID + 0xF800 

- The initial value is for CRC calculation and the message should be sent with the calculated result value. 

- The mathematical expression to 16 bit CRC polynomial is given here. G(x) = x16 + x12 + x5 + 1";
BA_ "GenSigStartValue" SG_ 2365803009 DATC_Crc16Val 65535;
BA_ "UserSigValidity" SG_ 2365803009 DATC_Crc16Val 7;
BA_ "Version" SG_ 2365803009 DATC_Crc16Val "19.09.02";
BA_ "Description" SG_ 2365803009 DATC_AlvCnt16Val "For the first transmission request for a data element the counter shall be initialized with 0 and shall be incremented by 1 for every subsequent send request. 

When the counter reaches the maximum value(0xFF), then it shall restart with 0 for the next send request";
BA_ "UserSigValidity" SG_ 2365803009 DATC_AlvCnt16Val 7;
BA_ "Version" SG_ 2365803009 DATC_AlvCnt16Val "19.09.02";
BA_ "Description" SG_ 2365803009 DATC_SwVer1 "This signal idnicates DATC Software Version to display on H_U



Change it to an ASCII code value.";
BA_ "GenSigStartValue" SG_ 2365803009 DATC_SwVer1 127;
BA_ "UserSigValidity" SG_ 2365803009 DATC_SwVer1 7;
BA_ "Version" SG_ 2365803009 DATC_SwVer1 "19.09.02";
BA_ "Description" SG_ 2365803009 DATC_SwVer2 "This signal indicates DATC Software Version to display on H_U



Change it to an ASCII code value.";
BA_ "GenSigStartValue" SG_ 2365803009 DATC_SwVer2 127;
BA_ "UserSigValidity" SG_ 2365803009 DATC_SwVer2 7;
BA_ "Version" SG_ 2365803009 DATC_SwVer2 "19.09.02";
BA_ "Description" SG_ 2365803009 DATC_SwVer3 "This signal indicates DATC Software Version to display on H_U



Change it to an ASCII code value.";
BA_ "GenSigStartValue" SG_ 2365803009 DATC_SwVer3 127;
BA_ "UserSigValidity" SG_ 2365803009 DATC_SwVer3 7;
BA_ "Version" SG_ 2365803009 DATC_SwVer3 "19.09.02";
BA_ "Description" SG_ 2365803009 DATC_Typ2 "Bit0: (AVN Controllable) :  0 ? NOT Apply / 1 ? Apply

Bit1~2 (Multi Auto Blower) : 0 ? Single / 1 ? 2 Step Type / 2 ? 3 Step Type  / 3 - Reserved

Bit3~5 (Front Mode Type) : 0 ? 4 MODE / 1 ? 6MODE / 2 ? 7MODE  / 3 ~ 7 ? Reserved

Bit6 (Fine Dust Sensor) : 0 - Fine Dust Sensor Not Applied / 1 - Fine Dust Sensor Applied.

Bit7~8 (Multi Auto Text) : 0 - Multi Auto State Text Not Applied / 1 - Multi Auto State Text Display Only Applied / 2 - Multi Auto State Text Display & Control Applied / 3 ? Reserved

Bit9 (Mode Def Type) : 0 ? Symbol Type / 1 ? Arrow Type

Bit10~15 : Reserved";
BA_ "UserSigValidity" SG_ 2365803009 DATC_Typ2 7;
BA_REL_ "GenSigTimeoutTime" BU_SG_REL_ ATS SG_ 2365803009 DATC_Typ2 5000;
BA_ "Version" SG_ 2365803009 DATC_Typ2 "20.03.06";
BA_ "GenMsgSendType" BO_ 2365803010 0;
BA_ "GenMsgCycleTime" BO_ 2365803010 1000;
BA_ "GenMsgCycleTimeFast" BO_ 2365803010 0;
BA_ "GenMsgNrOfRepetition" BO_ 2365803010 0;
BA_ "VFrameFormat" BO_ 2365803010 1;
BA_ "Description" SG_ 2365803010 DATC_SwVer4 "This signal idnicates DATC Detail Software Version



Change it to an ASCII code value.";
BA_ "GenSigStartValue" SG_ 2365803010 DATC_SwVer4 127;
BA_ "UserSigValidity" SG_ 2365803010 DATC_SwVer4 7;
BA_ "Version" SG_ 2365803010 DATC_SwVer4 "21.10.05";
BA_ "Description" SG_ 2365803010 DATC_SwVer5 "This signal idnicates DATC Detail Software Version



Change it to an ASCII code value.";
BA_ "GenSigStartValue" SG_ 2365803010 DATC_SwVer5 127;
BA_ "UserSigValidity" SG_ 2365803010 DATC_SwVer5 7;
BA_ "Version" SG_ 2365803010 DATC_SwVer5 "21.10.05";
BA_ "GenMsgSendType" BO_ 2365803011 0;
BA_ "GenMsgCycleTime" BO_ 2365803011 1000;
BA_ "GenMsgCycleTimeFast" BO_ 2365803011 0;
BA_ "GenMsgNrOfRepetition" BO_ 2365803011 0;
BA_ "VFrameFormat" BO_ 2365803011 1;
BA_ "GenMsgSendType" BO_ 2365803012 0;
BA_ "GenMsgCycleTime" BO_ 2365803012 1000;
BA_ "GenMsgCycleTimeFast" BO_ 2365803012 0;
BA_ "GenMsgNrOfRepetition" BO_ 2365803012 0;
BA_ "VFrameFormat" BO_ 2365803012 1;
BA_ "GenMsgSendType" BO_ 1174 0;
BA_ "Description" SG_ 1174 Drv_SHVU_SeatOptSta "¿îÀü¼® ½ÃÆ®¿¡ Àû¿ëµÈ È÷ÅÍ/ÅëÇ³ ¿É¼Ç »ç¾ç";
BA_ "GenSigSendType" SG_ 1174 Drv_SHVU_SeatOptSta 4;
BA_ "UserSigValidity" SG_ 1174 Drv_SHVU_SeatOptSta 3;
BA_REL_ "GenSigTimeoutTime" BU_SG_REL_ CGW_CCU SG_ 1174 Drv_SHVU_SeatOptSta 1500;
BA_REL_ "GenSigTimeoutTime" BU_SG_REL_ FCS SG_ 1174 Drv_SHVU_SeatOptSta 1500;
BA_REL_ "GenSigTimeoutTime" BU_SG_REL_ CGW_CCU SG_ 1174 Drv_SHVU_SeatOptSta 1500;
BA_ "NetworkRequest" SG_ 1174 Drv_SHVU_SeatOptSta 0;
BA_ "NetworkRequestHoldingTime" SG_ 1174 Drv_SHVU_SeatOptSta 5000;
BA_ "Version" SG_ 1174 Drv_SHVU_SeatOptSta "19.01.04";
BA_ "Description" SG_ 1174 Drv_SHVU_HtSwHiIndSta "¿îÀü¼® ½ÃÆ® ¿­¼± ½ºÀ§Ä¡ High Indicator Á¤º¸";
BA_ "GenSigSendType" SG_ 1174 Drv_SHVU_HtSwHiIndSta 4;
BA_ "UserSigValidity" SG_ 1174 Drv_SHVU_HtSwHiIndSta 3;
BA_REL_ "GenSigTimeoutTime" BU_SG_REL_ FCS SG_ 1174 Drv_SHVU_HtSwHiIndSta 1500;
BA_REL_ "GenSigTimeoutTime" BU_SG_REL_ CGW_CCU SG_ 1174 Drv_SHVU_HtSwHiIndSta 1500;
BA_ "NetworkRequest" SG_ 1174 Drv_SHVU_HtSwHiIndSta 0;
BA_ "NetworkRequestHoldingTime" SG_ 1174 Drv_SHVU_HtSwHiIndSta 5000;
BA_ "Version" SG_ 1174 Drv_SHVU_HtSwHiIndSta "21.07.06";
BA_ "Description" SG_ 1174 Drv_SHVU_HtSwMidIndSta "¿îÀü¼® ½ÃÆ® ¿­¼± ½ºÀ§Ä¡ Mid Indicator Á¤º¸";
BA_ "GenSigSendType" SG_ 1174 Drv_SHVU_HtSwMidIndSta 4;
BA_ "UserSigValidity" SG_ 1174 Drv_SHVU_HtSwMidIndSta 3;
BA_REL_ "GenSigTimeoutTime" BU_SG_REL_ FCS SG_ 1174 Drv_SHVU_HtSwMidIndSta 1500;
BA_REL_ "GenSigTimeoutTime" BU_SG_REL_ CGW_CCU SG_ 1174 Drv_SHVU_HtSwMidIndSta 1500;
BA_ "NetworkRequest" SG_ 1174 Drv_SHVU_HtSwMidIndSta 0;
BA_ "NetworkRequestHoldingTime" SG_ 1174 Drv_SHVU_HtSwMidIndSta 5000;
BA_ "Version" SG_ 1174 Drv_SHVU_HtSwMidIndSta "21.07.06";
BA_ "Description" SG_ 1174 Drv_SHVU_HtSwLowIndSta "¿îÀü¼® ½ÃÆ® ¿­¼± ½ºÀ§Ä¡ Low Indicator Á¤º¸";
BA_ "GenSigSendType" SG_ 1174 Drv_SHVU_HtSwLowIndSta 4;
BA_ "UserSigValidity" SG_ 1174 Drv_SHVU_HtSwLowIndSta 3;
BA_REL_ "GenSigTimeoutTime" BU_SG_REL_ FCS SG_ 1174 Drv_SHVU_HtSwLowIndSta 1500;
BA_REL_ "GenSigTimeoutTime" BU_SG_REL_ CGW_CCU SG_ 1174 Drv_SHVU_HtSwLowIndSta 1500;
BA_ "NetworkRequest" SG_ 1174 Drv_SHVU_HtSwLowIndSta 0;
BA_ "NetworkRequestHoldingTime" SG_ 1174 Drv_SHVU_HtSwLowIndSta 5000;
BA_ "Version" SG_ 1174 Drv_SHVU_HtSwLowIndSta "21.07.06";
BA_ "Description" SG_ 1174 Drv_SHVU_VntSwHiIndSta "¿îÀü¼® ½ÃÆ® ÅëÇ³ ½ºÀ§Ä¡ High Indicator Á¤º¸";
BA_ "GenSigSendType" SG_ 1174 Drv_SHVU_VntSwHiIndSta 4;
BA_ "UserSigValidity" SG_ 1174 Drv_SHVU_VntSwHiIndSta 3;
BA_REL_ "GenSigTimeoutTime" BU_SG_REL_ FCS SG_ 1174 Drv_SHVU_VntSwHiIndSta 1500;
BA_REL_ "GenSigTimeoutTime" BU_SG_REL_ CGW_CCU SG_ 1174 Drv_SHVU_VntSwHiIndSta 1500;
BA_ "NetworkRequest" SG_ 1174 Drv_SHVU_VntSwHiIndSta 0;
BA_ "NetworkRequestHoldingTime" SG_ 1174 Drv_SHVU_VntSwHiIndSta 5000;
BA_ "Version" SG_ 1174 Drv_SHVU_VntSwHiIndSta "21.07.06";
BA_ "Description" SG_ 1174 Drv_SHVU_VntSwMidIndSta "¿îÀü¼® ½ÃÆ® ÅëÇ³ ½ºÀ§Ä¡ Mid Indicator Á¤º¸";
BA_ "GenSigSendType" SG_ 1174 Drv_SHVU_VntSwMidIndSta 4;
BA_ "UserSigValidity" SG_ 1174 Drv_SHVU_VntSwMidIndSta 3;
BA_REL_ "GenSigTimeoutTime" BU_SG_REL_ FCS SG_ 1174 Drv_SHVU_VntSwMidIndSta 1500;
BA_REL_ "GenSigTimeoutTime" BU_SG_REL_ CGW_CCU SG_ 1174 Drv_SHVU_VntSwMidIndSta 1500;
BA_ "NetworkRequest" SG_ 1174 Drv_SHVU_VntSwMidIndSta 0;
BA_ "NetworkRequestHoldingTime" SG_ 1174 Drv_SHVU_VntSwMidIndSta 5000;
BA_ "Version" SG_ 1174 Drv_SHVU_VntSwMidIndSta "21.07.06";
BA_ "Description" SG_ 1174 Drv_SHVU_VntSwLowIndSta "¿îÀü¼® ½ÃÆ® ÅëÇ³ ½ºÀ§Ä¡ Low Indicator Á¤º¸";
BA_ "GenSigSendType" SG_ 1174 Drv_SHVU_VntSwLowIndSta 4;
BA_ "UserSigValidity" SG_ 1174 Drv_SHVU_VntSwLowIndSta 3;
BA_REL_ "GenSigTimeoutTime" BU_SG_REL_ FCS SG_ 1174 Drv_SHVU_VntSwLowIndSta 1500;
BA_REL_ "GenSigTimeoutTime" BU_SG_REL_ CGW_CCU SG_ 1174 Drv_SHVU_VntSwLowIndSta 1500;
BA_ "NetworkRequest" SG_ 1174 Drv_SHVU_VntSwLowIndSta 0;
BA_ "NetworkRequestHoldingTime" SG_ 1174 Drv_SHVU_VntSwLowIndSta 5000;
BA_ "Version" SG_ 1174 Drv_SHVU_VntSwLowIndSta "21.07.06";
BA_ "Description" SG_ 1174 Drv_SHVU_HtBlcUSMSta "Hetaer Balance Driver USM R vaule";
BA_ "GenSigSendType" SG_ 1174 Drv_SHVU_HtBlcUSMSta 4;
BA_ "UserSigValidity" SG_ 1174 Drv_SHVU_HtBlcUSMSta 0;
BA_REL_ "GenSigTimeoutTime" BU_SG_REL_ CGW_CCU SG_ 1174 Drv_SHVU_HtBlcUSMSta 1500;
BA_ "Version" SG_ 1174 Drv_SHVU_HtBlcUSMSta "19.01.04";
BA_ "Description" SG_ 1174 Drv_SHVU_SeatHtOperSta "¿îÀü¼® ½ÃÆ® ÇöÀç ÀÛµ¿ ÁßÀÎ È÷ÅÍ/ÅëÇ³ ´Ü¼ö »óÅÂ";
BA_ "GenSigSendType" SG_ 1174 Drv_SHVU_SeatHtOperSta 4;
BA_ "UserSigValidity" SG_ 1174 Drv_SHVU_SeatHtOperSta 3;
BA_REL_ "GenSigTimeoutTime" BU_SG_REL_ CGW_CCU SG_ 1174 Drv_SHVU_SeatHtOperSta 1500;
BA_ "NetworkRequest" SG_ 1174 Drv_SHVU_SeatHtOperSta 0;
BA_ "NetworkRequestHoldingTime" SG_ 1174 Drv_SHVU_SeatHtOperSta 5000;
BA_ "Version" SG_ 1174 Drv_SHVU_SeatHtOperSta "21.09.07";
BA_ "Description" SG_ 1174 Drv_SHVU_HtSwHiIndSta_RHD "¿îÀü¼® ½ÃÆ® ¿­¼± ½ºÀ§Ä¡ High Indicator Á¤º¸(RHD)";
BA_ "GenSigSendType" SG_ 1174 Drv_SHVU_HtSwHiIndSta_RHD 4;
BA_ "UserSigValidity" SG_ 1174 Drv_SHVU_HtSwHiIndSta_RHD 3;
BA_REL_ "GenSigTimeoutTime" BU_SG_REL_ FCS SG_ 1174 Drv_SHVU_HtSwHiIndSta_RHD 1500;
BA_REL_ "GenSigTimeoutTime" BU_SG_REL_ CGW_CCU SG_ 1174 Drv_SHVU_HtSwHiIndSta_RHD 1500;
BA_ "NetworkRequest" SG_ 1174 Drv_SHVU_HtSwHiIndSta_RHD 0;
BA_ "NetworkRequestHoldingTime" SG_ 1174 Drv_SHVU_HtSwHiIndSta_RHD 5000;
BA_ "Version" SG_ 1174 Drv_SHVU_HtSwHiIndSta_RHD "21.07.06";
BA_ "Description" SG_ 1174 Drv_SHVU_HtSwMidIndSta_RHD "¿îÀü¼® ½ÃÆ® ¿­¼± ½ºÀ§Ä¡ Mid Indicator Á¤º¸(RHD)";
BA_ "GenSigSendType" SG_ 1174 Drv_SHVU_HtSwMidIndSta_RHD 4;
BA_ "UserSigValidity" SG_ 1174 Drv_SHVU_HtSwMidIndSta_RHD 3;
BA_REL_ "GenSigTimeoutTime" BU_SG_REL_ FCS SG_ 1174 Drv_SHVU_HtSwMidIndSta_RHD 1500;
BA_REL_ "GenSigTimeoutTime" BU_SG_REL_ CGW_CCU SG_ 1174 Drv_SHVU_HtSwMidIndSta_RHD 1500;
BA_ "NetworkRequest" SG_ 1174 Drv_SHVU_HtSwMidIndSta_RHD 0;
BA_ "NetworkRequestHoldingTime" SG_ 1174 Drv_SHVU_HtSwMidIndSta_RHD 5000;
BA_ "Version" SG_ 1174 Drv_SHVU_HtSwMidIndSta_RHD "21.07.06";
BA_ "Description" SG_ 1174 Drv_SHVU_HtSwLowIndSta_RHD "¿îÀü¼® ½ÃÆ® ¿­¼± ½ºÀ§Ä¡ Low Indicator Á¤º¸(RHD)";
BA_ "GenSigSendType" SG_ 1174 Drv_SHVU_HtSwLowIndSta_RHD 4;
BA_ "UserSigValidity" SG_ 1174 Drv_SHVU_HtSwLowIndSta_RHD 3;
BA_REL_ "GenSigTimeoutTime" BU_SG_REL_ FCS SG_ 1174 Drv_SHVU_HtSwLowIndSta_RHD 1500;
BA_REL_ "GenSigTimeoutTime" BU_SG_REL_ CGW_CCU SG_ 1174 Drv_SHVU_HtSwLowIndSta_RHD 1500;
BA_ "NetworkRequest" SG_ 1174 Drv_SHVU_HtSwLowIndSta_RHD 0;
BA_ "NetworkRequestHoldingTime" SG_ 1174 Drv_SHVU_HtSwLowIndSta_RHD 5000;
BA_ "Version" SG_ 1174 Drv_SHVU_HtSwLowIndSta_RHD "21.07.06";
BA_ "Description" SG_ 1174 Drv_SHVU_VntSwHiIndSta_RHD "¿îÀü¼® ½ÃÆ® ÅëÇ³ ½ºÀ§Ä¡ High Indicator Á¤º¸(RHD)";
BA_ "GenSigSendType" SG_ 1174 Drv_SHVU_VntSwHiIndSta_RHD 4;
BA_ "UserSigValidity" SG_ 1174 Drv_SHVU_VntSwHiIndSta_RHD 3;
BA_REL_ "GenSigTimeoutTime" BU_SG_REL_ FCS SG_ 1174 Drv_SHVU_VntSwHiIndSta_RHD 1500;
BA_REL_ "GenSigTimeoutTime" BU_SG_REL_ CGW_CCU SG_ 1174 Drv_SHVU_VntSwHiIndSta_RHD 1500;
BA_ "NetworkRequest" SG_ 1174 Drv_SHVU_VntSwHiIndSta_RHD 0;
BA_ "NetworkRequestHoldingTime" SG_ 1174 Drv_SHVU_VntSwHiIndSta_RHD 5000;
BA_ "Version" SG_ 1174 Drv_SHVU_VntSwHiIndSta_RHD "21.07.06";
BA_ "Description" SG_ 1174 Drv_SHVU_VntSwMidIndSta_RHD "¿îÀü¼® ½ÃÆ® ÅëÇ³ ½ºÀ§Ä¡ Mid Indicator Á¤º¸(RHD)";
BA_ "GenSigSendType" SG_ 1174 Drv_SHVU_VntSwMidIndSta_RHD 4;
BA_ "UserSigValidity" SG_ 1174 Drv_SHVU_VntSwMidIndSta_RHD 3;
BA_REL_ "GenSigTimeoutTime" BU_SG_REL_ FCS SG_ 1174 Drv_SHVU_VntSwMidIndSta_RHD 1500;
BA_REL_ "GenSigTimeoutTime" BU_SG_REL_ CGW_CCU SG_ 1174 Drv_SHVU_VntSwMidIndSta_RHD 1500;
BA_ "NetworkRequest" SG_ 1174 Drv_SHVU_VntSwMidIndSta_RHD 0;
BA_ "NetworkRequestHoldingTime" SG_ 1174 Drv_SHVU_VntSwMidIndSta_RHD 5000;
BA_ "Version" SG_ 1174 Drv_SHVU_VntSwMidIndSta_RHD "21.07.06";
BA_ "Description" SG_ 1174 Drv_SHVU_VntSwLowIndSta_RHD "¿îÀü¼® ½ÃÆ® ÅëÇ³ ½ºÀ§Ä¡ Low Indicator Á¤º¸(RHD)";
BA_ "GenSigSendType" SG_ 1174 Drv_SHVU_VntSwLowIndSta_RHD 4;
BA_ "UserSigValidity" SG_ 1174 Drv_SHVU_VntSwLowIndSta_RHD 3;
BA_REL_ "GenSigTimeoutTime" BU_SG_REL_ FCS SG_ 1174 Drv_SHVU_VntSwLowIndSta_RHD 1500;
BA_REL_ "GenSigTimeoutTime" BU_SG_REL_ CGW_CCU SG_ 1174 Drv_SHVU_VntSwLowIndSta_RHD 1500;
BA_ "NetworkRequest" SG_ 1174 Drv_SHVU_VntSwLowIndSta_RHD 0;
BA_ "NetworkRequestHoldingTime" SG_ 1174 Drv_SHVU_VntSwLowIndSta_RHD 5000;
BA_ "Version" SG_ 1174 Drv_SHVU_VntSwLowIndSta_RHD "21.07.06";
BA_ "Description" SG_ 1174 Drv_SHVU_HtBlcUSMSta_RHD "Hetaer Balance Driver USM R vaule(RHD)";
BA_ "GenSigSendType" SG_ 1174 Drv_SHVU_HtBlcUSMSta_RHD 4;
BA_ "UserSigValidity" SG_ 1174 Drv_SHVU_HtBlcUSMSta_RHD 0;
BA_REL_ "GenSigTimeoutTime" BU_SG_REL_ CGW_CCU SG_ 1174 Drv_SHVU_HtBlcUSMSta_RHD 1500;
BA_ "Version" SG_ 1174 Drv_SHVU_HtBlcUSMSta_RHD "19.01.04";
BA_ "GenMsgCycleTime" BO_ 1179 0;
BA_ "Description" SG_ 1179 Drv_SHVU_SeatEcoSta "Drv ½ÃÆ® ¿¡ÄÚÇÃ·¯½º ¸ðµå ÁøÀÔ Á¤º¸";
BA_ "GenSigSendType" SG_ 1179 Drv_SHVU_SeatEcoSta 4;
BA_ "UserSigValidity" SG_ 1179 Drv_SHVU_SeatEcoSta 3;
BA_REL_ "GenSigTimeoutTime" BU_SG_REL_ CGW_CCU SG_ 1179 Drv_SHVU_SeatEcoSta 0;
BA_ "NetworkRequest" SG_ 1179 Drv_SHVU_SeatEcoSta 0;
BA_ "NetworkRequestHoldingTime" SG_ 1179 Drv_SHVU_SeatEcoSta 5000;
BA_ "Version" SG_ 1179 Drv_SHVU_SeatEcoSta "21.07.06";
BA_ "Description" SG_ 1179 SHVU_Drv_Beep1Sound "Play touch beep sound one time

Beep sound on/off

Default : Off

Goes On when play beep sound";
BA_ "GenSigSendType" SG_ 1179 SHVU_Drv_Beep1Sound 4;
BA_ "UserSigValidity" SG_ 1179 SHVU_Drv_Beep1Sound 3;
BA_REL_ "GenSigTimeoutTime" BU_SG_REL_ CGW_CCU SG_ 1179 SHVU_Drv_Beep1Sound 0;
BA_ "Version" SG_ 1179 SHVU_Drv_Beep1Sound "21.07.06";
BA_ "Description" SG_ 1179 SHVU_CtrlScreenDis "Change AVN Screen to control Seat Heater or Ventilation

Screen Display On : Pop up the menu of controlling Seat Heater & Ventilation

Default : Off";
BA_ "GenSigSendType" SG_ 1179 SHVU_CtrlScreenDis 4;
BA_ "UserSigValidity" SG_ 1179 SHVU_CtrlScreenDis 3;
BA_REL_ "GenSigTimeoutTime" BU_SG_REL_ CGW_CCU SG_ 1179 SHVU_CtrlScreenDis 0;
BA_ "Version" SG_ 1179 SHVU_CtrlScreenDis "21.07.06";
BA_ "GenMsgSendType" BO_ 1189 0;
BA_ "GenMsgStartDelayTime" BO_ 1189 80;
BA_ "Description" SG_ 1189 C_RLTiltUpSw_HU "18.10.03_2nd Left side seat Moving control : Tilt Up";
BA_ "GenSigSendType" SG_ 1189 C_RLTiltUpSw_HU 4;
BA_ "UserSigValidity" SG_ 1189 C_RLTiltUpSw_HU 0;
BA_REL_ "GenSigTimeoutTime" BU_SG_REL_ APSU SG_ 1189 C_RLTiltUpSw_HU 1500;
BA_REL_ "GenSigTimeoutTime" BU_SG_REL_ RRPSU SG_ 1189 C_RLTiltUpSw_HU 1500;
BA_REL_ "GenSigTimeoutTime" BU_SG_REL_ RLPSU SG_ 1189 C_RLTiltUpSw_HU 1500;
BA_ "Version" SG_ 1189 C_RLTiltUpSw_HU "18.10.03";
BA_ "Description" SG_ 1189 C_RRTiltDownSw_HU "18.10.03_2nd Right side seat Moving control : Tilt Down";
BA_ "GenSigSendType" SG_ 1189 C_RRTiltDownSw_HU 4;
BA_ "UserSigValidity" SG_ 1189 C_RRTiltDownSw_HU 0;
BA_REL_ "GenSigTimeoutTime" BU_SG_REL_ APSU SG_ 1189 C_RRTiltDownSw_HU 1500;
BA_REL_ "GenSigTimeoutTime" BU_SG_REL_ RRPSU SG_ 1189 C_RRTiltDownSw_HU 1500;
BA_REL_ "GenSigTimeoutTime" BU_SG_REL_ RLPSU SG_ 1189 C_RRTiltDownSw_HU 1500;
BA_ "Version" SG_ 1189 C_RRTiltDownSw_HU "18.10.03";
BA_ "Description" SG_ 1189 C_RRTiltUpSw_HU "18.10.03_2nd Right side seat Moving control : Tilt Up";
BA_ "GenSigSendType" SG_ 1189 C_RRTiltUpSw_HU 4;
BA_ "UserSigValidity" SG_ 1189 C_RRTiltUpSw_HU 0;
BA_REL_ "GenSigTimeoutTime" BU_SG_REL_ APSU SG_ 1189 C_RRTiltUpSw_HU 1500;
BA_REL_ "GenSigTimeoutTime" BU_SG_REL_ RRPSU SG_ 1189 C_RRTiltUpSw_HU 1500;
BA_REL_ "GenSigTimeoutTime" BU_SG_REL_ RLPSU SG_ 1189 C_RRTiltUpSw_HU 1500;
BA_ "Version" SG_ 1189 C_RRTiltUpSw_HU "18.10.03";
BA_ "Description" SG_ 1189 C_RLRclBwdSw_HU "18.10.03_2nd Left side seat Moving control :Recline Backward";
BA_ "GenSigSendType" SG_ 1189 C_RLRclBwdSw_HU 4;
BA_ "UserSigValidity" SG_ 1189 C_RLRclBwdSw_HU 0;
BA_REL_ "GenSigTimeoutTime" BU_SG_REL_ APSU SG_ 1189 C_RLRclBwdSw_HU 1500;
BA_REL_ "GenSigTimeoutTime" BU_SG_REL_ RRPSU SG_ 1189 C_RLRclBwdSw_HU 1500;
BA_REL_ "GenSigTimeoutTime" BU_SG_REL_ RLPSU SG_ 1189 C_RLRclBwdSw_HU 1500;
BA_ "Version" SG_ 1189 C_RLRclBwdSw_HU "18.10.03";
BA_ "Description" SG_ 1189 C_RLRclFwdSw_HU "18.10.03_2nd Left side seat Moving control : Recline Forward";
BA_ "GenSigSendType" SG_ 1189 C_RLRclFwdSw_HU 4;
BA_ "UserSigValidity" SG_ 1189 C_RLRclFwdSw_HU 0;
BA_REL_ "GenSigTimeoutTime" BU_SG_REL_ APSU SG_ 1189 C_RLRclFwdSw_HU 1500;
BA_REL_ "GenSigTimeoutTime" BU_SG_REL_ RRPSU SG_ 1189 C_RLRclFwdSw_HU 1500;
BA_REL_ "GenSigTimeoutTime" BU_SG_REL_ RLPSU SG_ 1189 C_RLRclFwdSw_HU 1500;
BA_ "Version" SG_ 1189 C_RLRclFwdSw_HU "18.10.03";
BA_ "Description" SG_ 1189 C_RLFldSw_HU "18.10.03_2nd Left side seat folding control : Folding";
BA_ "GenSigSendType" SG_ 1189 C_RLFldSw_HU 4;
BA_ "UserSigValidity" SG_ 1189 C_RLFldSw_HU 0;
BA_REL_ "GenSigTimeoutTime" BU_SG_REL_ RLPSU SG_ 1189 C_RLFldSw_HU 1500;
BA_ "Version" SG_ 1189 C_RLFldSw_HU "18.10.03";
BA_ "Description" SG_ 1189 C_RRRclBwdSw_HU "18.10.03_2nd Right side seat Moving control :Recline Backward";
BA_ "GenSigSendType" SG_ 1189 C_RRRclBwdSw_HU 4;
BA_ "UserSigValidity" SG_ 1189 C_RRRclBwdSw_HU 0;
BA_REL_ "GenSigTimeoutTime" BU_SG_REL_ APSU SG_ 1189 C_RRRclBwdSw_HU 1500;
BA_REL_ "GenSigTimeoutTime" BU_SG_REL_ RRPSU SG_ 1189 C_RRRclBwdSw_HU 1500;
BA_REL_ "GenSigTimeoutTime" BU_SG_REL_ RLPSU SG_ 1189 C_RRRclBwdSw_HU 1500;
BA_ "Version" SG_ 1189 C_RRRclBwdSw_HU "18.10.03";
BA_ "Description" SG_ 1189 C_RRRclFwdSw_HU "18.10.03_2nd Right side seat Moving control :Recline Forward";
BA_ "GenSigSendType" SG_ 1189 C_RRRclFwdSw_HU 4;
BA_ "UserSigValidity" SG_ 1189 C_RRRclFwdSw_HU 0;
BA_REL_ "GenSigTimeoutTime" BU_SG_REL_ APSU SG_ 1189 C_RRRclFwdSw_HU 1500;
BA_REL_ "GenSigTimeoutTime" BU_SG_REL_ RRPSU SG_ 1189 C_RRRclFwdSw_HU 1500;
BA_REL_ "GenSigTimeoutTime" BU_SG_REL_ RLPSU SG_ 1189 C_RRRclFwdSw_HU 1500;
BA_ "Version" SG_ 1189 C_RRRclFwdSw_HU "18.10.03";
BA_ "Description" SG_ 1189 C_TLHrestFldSw_HU "18.10.03_3rdLeft side seat Headrest folding control : Folding";
BA_ "GenSigSendType" SG_ 1189 C_TLHrestFldSw_HU 4;
BA_ "UserSigValidity" SG_ 1189 C_TLHrestFldSw_HU 0;
BA_REL_ "GenSigTimeoutTime" BU_SG_REL_ PFSU SG_ 1189 C_TLHrestFldSw_HU 1500;
BA_ "Version" SG_ 1189 C_TLHrestFldSw_HU "18.10.03";
BA_ "Description" SG_ 1189 C_TRHrestFldSw_HU "18.10.03_3rd Right side seat Headrest folding control : Folding";
BA_ "GenSigSendType" SG_ 1189 C_TRHrestFldSw_HU 4;
BA_ "UserSigValidity" SG_ 1189 C_TRHrestFldSw_HU 0;
BA_REL_ "GenSigTimeoutTime" BU_SG_REL_ PFSU SG_ 1189 C_TRHrestFldSw_HU 1500;
BA_ "Version" SG_ 1189 C_TRHrestFldSw_HU "18.10.03";
BA_ "Description" SG_ 1189 C_RLRlxSW_HU "18.10.03_2nd Left side seat Moving control : Relax mode";
BA_ "GenSigSendType" SG_ 1189 C_RLRlxSW_HU 4;
BA_ "UserSigValidity" SG_ 1189 C_RLRlxSW_HU 0;
BA_REL_ "GenSigTimeoutTime" BU_SG_REL_ RLPSU SG_ 1189 C_RLRlxSW_HU 1500;
BA_ "Version" SG_ 1189 C_RLRlxSW_HU "18.10.03";
BA_ "Description" SG_ 1189 C_RRRlxSW_HU "18.10.03_2nd Right side seat Moving control : Relax mode";
BA_ "GenSigSendType" SG_ 1189 C_RRRlxSW_HU 4;
BA_ "UserSigValidity" SG_ 1189 C_RRRlxSW_HU 0;
BA_REL_ "GenSigTimeoutTime" BU_SG_REL_ RRPSU SG_ 1189 C_RRRlxSW_HU 1500;
BA_ "Version" SG_ 1189 C_RRRlxSW_HU "18.10.03";
BA_ "Description" SG_ 1189 C_TLFldSw_HU "18.10.03_3rd Left side seat folding control : Folding";
BA_ "GenSigSendType" SG_ 1189 C_TLFldSw_HU 4;
BA_ "UserSigValidity" SG_ 1189 C_TLFldSw_HU 0;
BA_REL_ "GenSigTimeoutTime" BU_SG_REL_ PFSU SG_ 1189 C_TLFldSw_HU 1500;
BA_ "Version" SG_ 1189 C_TLFldSw_HU "18.10.03";
BA_ "Description" SG_ 1189 C_TRFldSw_HU "18.10.03_3rd Right side seat folding control : Folding";
BA_ "GenSigSendType" SG_ 1189 C_TRFldSw_HU 4;
BA_ "UserSigValidity" SG_ 1189 C_TRFldSw_HU 0;
BA_REL_ "GenSigTimeoutTime" BU_SG_REL_ PFSU SG_ 1189 C_TRFldSw_HU 1500;
BA_ "Version" SG_ 1189 C_TRFldSw_HU "18.10.03";
BA_ "Description" SG_ 1189 C_RRFldSw_HU "18.10.03_2nd Right side seat folding control : Folding";
BA_ "GenSigSendType" SG_ 1189 C_RRFldSw_HU 4;
BA_ "UserSigValidity" SG_ 1189 C_RRFldSw_HU 0;
BA_REL_ "GenSigTimeoutTime" BU_SG_REL_ RRPSU SG_ 1189 C_RRFldSw_HU 1500;
BA_ "Version" SG_ 1189 C_RRFldSw_HU "18.10.03";
BA_ "Description" SG_ 1189 C_RLTiltDownSw_HU "18.10.03_2ndLeft side seat Moving control : Tilt Down";
BA_ "GenSigSendType" SG_ 1189 C_RLTiltDownSw_HU 4;
BA_ "UserSigValidity" SG_ 1189 C_RLTiltDownSw_HU 0;
BA_REL_ "GenSigTimeoutTime" BU_SG_REL_ APSU SG_ 1189 C_RLTiltDownSw_HU 1500;
BA_REL_ "GenSigTimeoutTime" BU_SG_REL_ RRPSU SG_ 1189 C_RLTiltDownSw_HU 1500;
BA_REL_ "GenSigTimeoutTime" BU_SG_REL_ RLPSU SG_ 1189 C_RLTiltDownSw_HU 1500;
BA_ "Version" SG_ 1189 C_RLTiltDownSw_HU "18.10.03";
BA_ "GenMsgCycleTime" BO_ 1185 0;
BA_ "GenSigSendType" SG_ 1185 C_AstWindowCmdAVN 4;
BA_ "GenSigStartValue" SG_ 1185 C_AstWindowCmdAVN 15;
BA_ "UserSigValidity" SG_ 1185 C_AstWindowCmdAVN 0;
BA_ "Version" SG_ 1185 C_AstWindowCmdAVN "19.11.05";
BA_ "Description" SG_ 1185 C_RrDefoggerCmdAVN "18.08.09_";
BA_ "GenSigSendType" SG_ 1185 C_RrDefoggerCmdAVN 4;
BA_ "GenSigStartValue" SG_ 1185 C_RrDefoggerCmdAVN 3;
BA_ "UserSigValidity" SG_ 1185 C_RrDefoggerCmdAVN 3;
BA_ "Version" SG_ 1185 C_RrDefoggerCmdAVN "18.09.02";
BA_ "GenSigSendType" SG_ 1185 C_RRWindowCmdAVN 4;
BA_ "GenSigStartValue" SG_ 1185 C_RRWindowCmdAVN 15;
BA_ "UserSigValidity" SG_ 1185 C_RRWindowCmdAVN 0;
BA_ "Version" SG_ 1185 C_RRWindowCmdAVN "19.11.05";
BA_ "GenSigSendType" SG_ 1185 C_RLWindowCmdAVN 4;
BA_ "GenSigStartValue" SG_ 1185 C_RLWindowCmdAVN 15;
BA_ "UserSigValidity" SG_ 1185 C_RLWindowCmdAVN 0;
BA_ "Version" SG_ 1185 C_RLWindowCmdAVN "19.11.05";
BA_ "Description" SG_ 1185 C_BlindCmdAVN "18.08.09_";
BA_ "GenSigSendType" SG_ 1185 C_BlindCmdAVN 4;
BA_ "GenSigStartValue" SG_ 1185 C_BlindCmdAVN 7;
BA_ "UserSigValidity" SG_ 1185 C_BlindCmdAVN 1;
BA_REL_ "GenSigTimeoutTime" BU_SG_REL_ RCM SG_ 1185 C_BlindCmdAVN 0;
BA_ "Version" SG_ 1185 C_BlindCmdAVN "18.09.02";
BA_ "Description" SG_ 1185 C_GlassCmdAVN "18.08.09_";
BA_ "GenSigSendType" SG_ 1185 C_GlassCmdAVN 4;
BA_ "GenSigStartValue" SG_ 1185 C_GlassCmdAVN 7;
BA_ "UserSigValidity" SG_ 1185 C_GlassCmdAVN 1;
BA_REL_ "GenSigTimeoutTime" BU_SG_REL_ RCM SG_ 1185 C_GlassCmdAVN 0;
BA_ "Version" SG_ 1185 C_GlassCmdAVN "18.09.02";
BA_ "GenSigSendType" SG_ 1185 C_DrvWindowCmdAVN 4;
BA_ "GenSigStartValue" SG_ 1185 C_DrvWindowCmdAVN 15;
BA_ "UserSigValidity" SG_ 1185 C_DrvWindowCmdAVN 0;
BA_ "Version" SG_ 1185 C_DrvWindowCmdAVN "19.11.05";
BA_ "Description" SG_ 1185 C_PTGCNTLCmdAVN "18.08.09_";
BA_ "GenSigSendType" SG_ 1185 C_PTGCNTLCmdAVN 4;
BA_ "GenSigStartValue" SG_ 1185 C_PTGCNTLCmdAVN 3;
BA_ "UserSigValidity" SG_ 1185 C_PTGCNTLCmdAVN 3;
BA_ "Version" SG_ 1185 C_PTGCNTLCmdAVN "18.09.02";
BA_ "GenMsgCycleTime" BO_ 1186 0;
BA_ "Description" SG_ 1186 C_PTGMStopRlyIBOX "Remote control PTGM stop command 

Refer to RKE_01_00ms RKE_BtnReq";
BA_ "GenSigSendType" SG_ 1186 C_PTGMStopRlyIBOX 4;
BA_ "GenSigStartValue" SG_ 1186 C_PTGMStopRlyIBOX 7;
BA_ "UserSigValidity" SG_ 1186 C_PTGMStopRlyIBOX 0;
BA_ "NetworkRequest" SG_ 1186 C_PTGMStopRlyIBOX 0;
BA_ "NetworkRequestHoldingTime" SG_ 1186 C_PTGMStopRlyIBOX 2000;
BA_ "Version" SG_ 1186 C_PTGMStopRlyIBOX "19.12.08";
BA_ "Description" SG_ 1186 C_PTGMCmdRlyIBOX "Remote control PTGM open command";
BA_ "GenSigSendType" SG_ 1186 C_PTGMCmdRlyIBOX 4;
BA_ "GenSigStartValue" SG_ 1186 C_PTGMCmdRlyIBOX 3;
BA_ "UserSigValidity" SG_ 1186 C_PTGMCmdRlyIBOX 0;
BA_ "NetworkRequest" SG_ 1186 C_PTGMCmdRlyIBOX 0;
BA_ "NetworkRequestHoldingTime" SG_ 1186 C_PTGMCmdRlyIBOX 2000;
BA_ "Version" SG_ 1186 C_PTGMCmdRlyIBOX "19.12.08";
BA_ "Description" SG_ 1186 C_RemoteWdwCMDHU "18.09.06_";
BA_ "GenSigSendType" SG_ 1186 C_RemoteWdwCMDHU 4;
BA_ "GenSigStartValue" SG_ 1186 C_RemoteWdwCMDHU 3;
BA_ "UserSigValidity" SG_ 1186 C_RemoteWdwCMDHU 0;
BA_ "Version" SG_ 1186 C_RemoteWdwCMDHU "18.10.05";
BA_ "Description" SG_ 1186 C_EsyAcsProfileID_HU "18.08.09_";
BA_ "GenSigSendType" SG_ 1186 C_EsyAcsProfileID_HU 4;
BA_ "UserSigValidity" SG_ 1186 C_EsyAcsProfileID_HU 0;
BA_REL_ "GenSigTimeoutTime" BU_SG_REL_ DPSU SG_ 1186 C_EsyAcsProfileID_HU 0;
BA_ "Version" SG_ 1186 C_EsyAcsProfileID_HU "18.09.04";
BA_ "Description" SG_ 1186 C_TeleDefoggerHeatingCmdIBOX "18.08.09_";
BA_ "GenSigSendType" SG_ 1186 C_TeleDefoggerHeatingCmdIBOX 4;
BA_ "GenSigStartValue" SG_ 1186 C_TeleDefoggerHeatingCmdIBOX 3;
BA_ "UserSigValidity" SG_ 1186 C_TeleDefoggerHeatingCmdIBOX 0;
BA_ "NetworkRequest" SG_ 1186 C_TeleDefoggerHeatingCmdIBOX 0;
BA_ "Version" SG_ 1186 C_TeleDefoggerHeatingCmdIBOX "18.09.04";
BA_ "Description" SG_ 1186 C_TeleFrontHeatingCmdIBOX "Command for Remote Heating (Front Window)";
BA_ "GenSigSendType" SG_ 1186 C_TeleFrontHeatingCmdIBOX 4;
BA_ "GenSigStartValue" SG_ 1186 C_TeleFrontHeatingCmdIBOX 3;
BA_ "UserSigValidity" SG_ 1186 C_TeleFrontHeatingCmdIBOX 0;
BA_ "NetworkRequest" SG_ 1186 C_TeleFrontHeatingCmdIBOX 0;
BA_ "NetworkRequestHoldingTime" SG_ 1186 C_TeleFrontHeatingCmdIBOX 2000;
BA_ "Version" SG_ 1186 C_TeleFrontHeatingCmdIBOX "20.04.03";
BA_ "Description" SG_ 1186 HU_CDMOpenCmd "Command for CDM open/close";
BA_ "GenSigSendType" SG_ 1186 HU_CDMOpenCmd 4;
BA_ "UserSigValidity" SG_ 1186 HU_CDMOpenCmd 7;
BA_ "Version" SG_ 1186 HU_CDMOpenCmd "20.01.02";
BA_ "Description" SG_ 1186 C_PreCrankReq "18.08.09_Remote Control message";
BA_ "GenSigSendType" SG_ 1186 C_PreCrankReq 4;
BA_ "UserSigValidity" SG_ 1186 C_PreCrankReq 0;
BA_REL_ "GenSigTimeoutTime" BU_SG_REL_ BLTN_CAM SG_ 1186 C_PreCrankReq 0;
BA_ "NetworkRequest" SG_ 1186 C_PreCrankReq 0;
BA_ "Version" SG_ 1186 C_PreCrankReq "18.09.04";
BA_ "Description" SG_ 1186 C_TeleAstSeatOpCmdIBOX "18.08.09_Remote Control message";
BA_ "GenSigSendType" SG_ 1186 C_TeleAstSeatOpCmdIBOX 4;
BA_ "UserSigValidity" SG_ 1186 C_TeleAstSeatOpCmdIBOX 3;
BA_REL_ "GenSigTimeoutTime" BU_SG_REL_ APSU SG_ 1186 C_TeleAstSeatOpCmdIBOX 0;
BA_REL_ "GenSigTimeoutTime" BU_SG_REL_ SHVU_FR SG_ 1186 C_TeleAstSeatOpCmdIBOX 0;
BA_ "Version" SG_ 1186 C_TeleAstSeatOpCmdIBOX "18.09.04";
BA_ "Description" SG_ 1186 C_TeleDrvSeatOpCmdIBOX "18.08.09_Remote Control message";
BA_ "GenSigSendType" SG_ 1186 C_TeleDrvSeatOpCmdIBOX 4;
BA_ "UserSigValidity" SG_ 1186 C_TeleDrvSeatOpCmdIBOX 3;
BA_REL_ "GenSigTimeoutTime" BU_SG_REL_ SHVU_FR SG_ 1186 C_TeleDrvSeatOpCmdIBOX 0;
BA_REL_ "GenSigTimeoutTime" BU_SG_REL_ DPSU SG_ 1186 C_TeleDrvSeatOpCmdIBOX 0;
BA_ "Version" SG_ 1186 C_TeleDrvSeatOpCmdIBOX "18.09.04";
BA_ "Description" SG_ 1186 C_TeleRRSeatOpCmdIBOX "18.08.09_Remote Control message";
BA_ "GenSigSendType" SG_ 1186 C_TeleRRSeatOpCmdIBOX 4;
BA_ "UserSigValidity" SG_ 1186 C_TeleRRSeatOpCmdIBOX 3;
BA_REL_ "GenSigTimeoutTime" BU_SG_REL_ RRHV SG_ 1186 C_TeleRRSeatOpCmdIBOX 0;
BA_REL_ "GenSigTimeoutTime" BU_SG_REL_ SHVU_FR SG_ 1186 C_TeleRRSeatOpCmdIBOX 0;
BA_REL_ "GenSigTimeoutTime" BU_SG_REL_ SHVU_RR SG_ 1186 C_TeleRRSeatOpCmdIBOX 0;
BA_REL_ "GenSigTimeoutTime" BU_SG_REL_ RRPSU SG_ 1186 C_TeleRRSeatOpCmdIBOX 0;
BA_REL_ "GenSigTimeoutTime" BU_SG_REL_ RLPSU SG_ 1186 C_TeleRRSeatOpCmdIBOX 0;
BA_REL_ "GenSigTimeoutTime" BU_SG_REL_ ATS SG_ 1186 C_TeleRRSeatOpCmdIBOX 0;
BA_ "Version" SG_ 1186 C_TeleRRSeatOpCmdIBOX "18.09.04";
BA_ "Description" SG_ 1186 C_TeleRLSeatOpCmdIBOX "18.08.09_Remote Control message";
BA_ "GenSigSendType" SG_ 1186 C_TeleRLSeatOpCmdIBOX 4;
BA_ "UserSigValidity" SG_ 1186 C_TeleRLSeatOpCmdIBOX 3;
BA_REL_ "GenSigTimeoutTime" BU_SG_REL_ RLHV SG_ 1186 C_TeleRLSeatOpCmdIBOX 0;
BA_REL_ "GenSigTimeoutTime" BU_SG_REL_ SHVU_FR SG_ 1186 C_TeleRLSeatOpCmdIBOX 0;
BA_REL_ "GenSigTimeoutTime" BU_SG_REL_ SHVU_RR SG_ 1186 C_TeleRLSeatOpCmdIBOX 0;
BA_REL_ "GenSigTimeoutTime" BU_SG_REL_ RRPSU SG_ 1186 C_TeleRLSeatOpCmdIBOX 0;
BA_REL_ "GenSigTimeoutTime" BU_SG_REL_ RLPSU SG_ 1186 C_TeleRLSeatOpCmdIBOX 0;
BA_REL_ "GenSigTimeoutTime" BU_SG_REL_ ATS SG_ 1186 C_TeleRLSeatOpCmdIBOX 0;
BA_ "Version" SG_ 1186 C_TeleRLSeatOpCmdIBOX "18.09.04";
BA_ "GenSigSendType" SG_ 1186 C_HazardFromCCS 4;
BA_ "UserSigValidity" SG_ 1186 C_HazardFromCCS 0;
BA_ "NetworkRequest" SG_ 1186 C_HazardFromCCS 0;
BA_ "NetworkRequestHoldingTime" SG_ 1186 C_HazardFromCCS 2000;
BA_ "Version" SG_ 1186 C_HazardFromCCS "19.07.01";
BA_ "GenSigSendType" SG_ 1186 C_PanicFromCCS 4;
BA_ "UserSigValidity" SG_ 1186 C_PanicFromCCS 0;
BA_ "NetworkRequest" SG_ 1186 C_PanicFromCCS 0;
BA_ "NetworkRequestHoldingTime" SG_ 1186 C_PanicFromCCS 2000;
BA_ "Version" SG_ 1186 C_PanicFromCCS "19.07.01";
BA_ "GenSigSendType" SG_ 1186 C_CtrlDrUnlockRlyCCS 4;
BA_ "UserSigValidity" SG_ 1186 C_CtrlDrUnlockRlyCCS 0;
BA_ "NetworkRequest" SG_ 1186 C_CtrlDrUnlockRlyCCS 0;
BA_ "NetworkRequestHoldingTime" SG_ 1186 C_CtrlDrUnlockRlyCCS 2000;
BA_ "Version" SG_ 1186 C_CtrlDrUnlockRlyCCS "19.07.01";
BA_ "GenSigSendType" SG_ 1186 C_CtrlDrLockRlyCCS 4;
BA_ "UserSigValidity" SG_ 1186 C_CtrlDrLockRlyCCS 0;
BA_ "NetworkRequest" SG_ 1186 C_CtrlDrLockRlyCCS 0;
BA_ "NetworkRequestHoldingTime" SG_ 1186 C_CtrlDrLockRlyCCS 2000;
BA_ "Version" SG_ 1186 C_CtrlDrLockRlyCCS "19.07.01";
BA_ "Description" SG_ 1186 C_DrvPSDCloseRlyIBOX "Remote control left PSD close command";
BA_ "GenSigSendType" SG_ 1186 C_DrvPSDCloseRlyIBOX 4;
BA_ "GenSigStartValue" SG_ 1186 C_DrvPSDCloseRlyIBOX 3;
BA_ "UserSigValidity" SG_ 1186 C_DrvPSDCloseRlyIBOX 0;
BA_ "NetworkRequest" SG_ 1186 C_DrvPSDCloseRlyIBOX 0;
BA_ "NetworkRequestHoldingTime" SG_ 1186 C_DrvPSDCloseRlyIBOX 2000;
BA_ "Version" SG_ 1186 C_DrvPSDCloseRlyIBOX "19.12.08";
BA_ "Description" SG_ 1186 C_DrvPSDOpenRlyIBOX "Remote control left PSD open command";
BA_ "GenSigSendType" SG_ 1186 C_DrvPSDOpenRlyIBOX 4;
BA_ "GenSigStartValue" SG_ 1186 C_DrvPSDOpenRlyIBOX 3;
BA_ "UserSigValidity" SG_ 1186 C_DrvPSDOpenRlyIBOX 0;
BA_ "NetworkRequest" SG_ 1186 C_DrvPSDOpenRlyIBOX 0;
BA_ "NetworkRequestHoldingTime" SG_ 1186 C_DrvPSDOpenRlyIBOX 2000;
BA_ "Version" SG_ 1186 C_DrvPSDOpenRlyIBOX "19.12.08";
BA_ "Description" SG_ 1186 C_AstPSDCloseRlyIBOX "Remote control right PSD close command";
BA_ "GenSigSendType" SG_ 1186 C_AstPSDCloseRlyIBOX 4;
BA_ "GenSigStartValue" SG_ 1186 C_AstPSDCloseRlyIBOX 3;
BA_ "UserSigValidity" SG_ 1186 C_AstPSDCloseRlyIBOX 0;
BA_ "NetworkRequest" SG_ 1186 C_AstPSDCloseRlyIBOX 0;
BA_ "NetworkRequestHoldingTime" SG_ 1186 C_AstPSDCloseRlyIBOX 2000;
BA_ "Version" SG_ 1186 C_AstPSDCloseRlyIBOX "19.12.08";
BA_ "Description" SG_ 1186 C_AstPSDOpenRlyIBOX "Remote control right PSD open command";
BA_ "GenSigSendType" SG_ 1186 C_AstPSDOpenRlyIBOX 4;
BA_ "GenSigStartValue" SG_ 1186 C_AstPSDOpenRlyIBOX 3;
BA_ "UserSigValidity" SG_ 1186 C_AstPSDOpenRlyIBOX 0;
BA_ "NetworkRequest" SG_ 1186 C_AstPSDOpenRlyIBOX 0;
BA_ "NetworkRequestHoldingTime" SG_ 1186 C_AstPSDOpenRlyIBOX 2000;
BA_ "Version" SG_ 1186 C_AstPSDOpenRlyIBOX "19.12.08";
BA_ "GenMsgCycleTime" BO_ 1193 0;
BA_ "Description" SG_ 1193 C_PTGMNValueSet "18.08.09_";
BA_ "GenSigSendType" SG_ 1193 C_PTGMNValueSet 4;
BA_ "UserSigValidity" SG_ 1193 C_PTGMNValueSet 3;
BA_ "Version" SG_ 1193 C_PTGMNValueSet "18.09.04";
BA_ "Description" SG_ 1193 CF_AVN_PSMNValueSet "18.08.09_";
BA_ "GenSigSendType" SG_ 1193 CF_AVN_PSMNValueSet 4;
BA_ "UserSigValidity" SG_ 1193 CF_AVN_PSMNValueSet 3;
BA_REL_ "GenSigTimeoutTime" BU_SG_REL_ DPSU SG_ 1193 CF_AVN_PSMNValueSet 0;
BA_ "Version" SG_ 1193 CF_AVN_PSMNValueSet "18.09.04";
BA_ "Description" SG_ 1193 C_HfreeTrunkTgNValueSet "18.08.09_";
BA_ "GenSigSendType" SG_ 1193 C_HfreeTrunkTgNValueSet 4;
BA_ "UserSigValidity" SG_ 1193 C_HfreeTrunkTgNValueSet 3;
BA_ "Version" SG_ 1193 C_HfreeTrunkTgNValueSet "18.09.04";
BA_ "Description" SG_ 1193 CF_AVN_TrfChgSet "18.08.09_";
BA_ "GenSigSendType" SG_ 1193 CF_AVN_TrfChgSet 4;
BA_ "UserSigValidity" SG_ 1193 CF_AVN_TrfChgSet 3;
BA_ "Version" SG_ 1193 CF_AVN_TrfChgSet "18.09.04";
BA_ "Description" SG_ 1193 CF_AVN_SCMNValueSet "18.08.09_";
BA_ "GenSigSendType" SG_ 1193 CF_AVN_SCMNValueSet 4;
BA_ "UserSigValidity" SG_ 1193 CF_AVN_SCMNValueSet 3;
BA_ "Version" SG_ 1193 CF_AVN_SCMNValueSet "18.09.04";
BA_ "Description" SG_ 1193 CF_AVN_ADrUNValueSet "18.08.09_";
BA_ "GenSigSendType" SG_ 1193 CF_AVN_ADrUNValueSet 4;
BA_ "UserSigValidity" SG_ 1193 CF_AVN_ADrUNValueSet 3;
BA_ "Version" SG_ 1193 CF_AVN_ADrUNValueSet "18.09.04";
BA_ "Description" SG_ 1193 CF_AVN_OTTurnNValueSet "18.08.09_";
BA_ "GenSigSendType" SG_ 1193 CF_AVN_OTTurnNValueSet 4;
BA_ "UserSigValidity" SG_ 1193 CF_AVN_OTTurnNValueSet 3;
BA_ "Version" SG_ 1193 CF_AVN_OTTurnNValueSet "18.09.04";
BA_ "Description" SG_ 1193 CF_Gway_WPCNValueSet "18.08.09_";
BA_ "GenSigSendType" SG_ 1193 CF_Gway_WPCNValueSet 4;
BA_ "UserSigValidity" SG_ 1193 CF_Gway_WPCNValueSet 3;
BA_REL_ "GenSigTimeoutTime" BU_SG_REL_ WPC SG_ 1193 CF_Gway_WPCNValueSet 0;
BA_ "Version" SG_ 1193 CF_Gway_WPCNValueSet "18.09.04";
BA_ "Description" SG_ 1193 C_AVN_RearWiperNValueSet "18.08.09_";
BA_ "GenSigSendType" SG_ 1193 C_AVN_RearWiperNValueSet 4;
BA_ "UserSigValidity" SG_ 1193 C_AVN_RearWiperNValueSet 3;
BA_ "Version" SG_ 1193 C_AVN_RearWiperNValueSet "18.09.04";
BA_ "Description" SG_ 1193 C_UnlockWelocomeNValueSet "18.08.09_";
BA_ "GenSigSendType" SG_ 1193 C_UnlockWelocomeNValueSet 4;
BA_ "UserSigValidity" SG_ 1193 C_UnlockWelocomeNValueSet 3;
BA_ "Version" SG_ 1193 C_UnlockWelocomeNValueSet "18.09.04";
BA_ "Description" SG_ 1193 C_SmartWelocomeNValueSet "18.08.09_";
BA_ "GenSigSendType" SG_ 1193 C_SmartWelocomeNValueSet 4;
BA_ "UserSigValidity" SG_ 1193 C_SmartWelocomeNValueSet 3;
BA_ "Version" SG_ 1193 C_SmartWelocomeNValueSet "18.09.04";
BA_ "Description" SG_ 1193 CF_AVN_PTGSpeedNValueSet "18.08.09_";
BA_ "GenSigSendType" SG_ 1193 CF_AVN_PTGSpeedNValueSet 4;
BA_ "UserSigValidity" SG_ 1193 CF_AVN_PTGSpeedNValueSet 3;
BA_ "Version" SG_ 1193 CF_AVN_PTGSpeedNValueSet "18.09.04";
BA_ "Description" SG_ 1193 CR_Datc_DRSeatWheel_USM_Set "18.08.09_";
BA_ "GenSigSendType" SG_ 1193 CR_Datc_DRSeatWheel_USM_Set 4;
BA_ "UserSigValidity" SG_ 1193 CR_Datc_DRSeatWheel_USM_Set 3;
BA_ "Version" SG_ 1193 CR_Datc_DRSeatWheel_USM_Set "18.09.04";
BA_ "Description" SG_ 1193 CF_AVN_TTUnlockNValueSet "18.08.09_";
BA_ "GenSigSendType" SG_ 1193 CF_AVN_TTUnlockNValueSet 4;
BA_ "GenSigStartValue" SG_ 1193 CF_AVN_TTUnlockNValueSet 3;
BA_ "UserSigValidity" SG_ 1193 CF_AVN_TTUnlockNValueSet 3;
BA_ "Version" SG_ 1193 CF_AVN_TTUnlockNValueSet "18.09.04";
BA_ "Description" SG_ 1193 CF_Gway_RWPCNValueSet "18.08.09_";
BA_ "GenSigSendType" SG_ 1193 CF_Gway_RWPCNValueSet 4;
BA_ "UserSigValidity" SG_ 1193 CF_Gway_RWPCNValueSet 3;
BA_REL_ "GenSigTimeoutTime" BU_SG_REL_ RWPC SG_ 1193 CF_Gway_RWPCNValueSet 0;
BA_ "Version" SG_ 1193 CF_Gway_RWPCNValueSet "18.09.04";
BA_ "Description" SG_ 1193 C_PSDNValueSet "18.11.10_";
BA_ "GenSigSendType" SG_ 1193 C_PSDNValueSet 4;
BA_ "UserSigValidity" SG_ 1193 C_PSDNValueSet 3;
BA_ "Version" SG_ 1193 C_PSDNValueSet "18.12.01";
BA_ "Description" SG_ 1193 CF_Avn_HAPTICWARNINGNValueSet "18.11.09_";
BA_ "GenSigSendType" SG_ 1193 CF_Avn_HAPTICWARNINGNValueSet 4;
BA_ "UserSigValidity" SG_ 1193 CF_Avn_HAPTICWARNINGNValueSet 3;
BA_ "Version" SG_ 1193 CF_Avn_HAPTICWARNINGNValueSet "18.12.01";
BA_ "Description" SG_ 1193 CR_Datc_DRSeatHeat_USM_Set "18.08.09_";
BA_ "GenSigSendType" SG_ 1193 CR_Datc_DRSeatHeat_USM_Set 4;
BA_ "UserSigValidity" SG_ 1193 CR_Datc_DRSeatHeat_USM_Set 3;
BA_ "Version" SG_ 1193 CR_Datc_DRSeatHeat_USM_Set "18.09.04";
BA_ "Description" SG_ 1193 C_WALNValueSet "18.08.09_";
BA_ "GenSigSendType" SG_ 1193 C_WALNValueSet 4;
BA_ "UserSigValidity" SG_ 1193 C_WALNValueSet 3;
BA_ "Version" SG_ 1193 C_WALNValueSet "18.09.04";
BA_ "Description" SG_ 1193 C_ApprUnlockNValue "18.08.09_";
BA_ "GenSigSendType" SG_ 1193 C_ApprUnlockNValue 4;
BA_ "UserSigValidity" SG_ 1193 C_ApprUnlockNValue 3;
BA_ "Version" SG_ 1193 C_ApprUnlockNValue "18.09.04";
BA_ "Description" SG_ 1193 CF_AVN_SEW_NEWNValueSet "This siganl is used for SEW from KA4/NX4.

Before KA4, SEA and SDW are merged using CF_AVN_SEANValueSet@HU_USM_E_01";
BA_ "GenSigSendType" SG_ 1193 CF_AVN_SEW_NEWNValueSet 4;
BA_ "UserSigValidity" SG_ 1193 CF_AVN_SEW_NEWNValueSet 3;
BA_ "Version" SG_ 1193 CF_AVN_SEW_NEWNValueSet "19.09.05";
BA_ "Description" SG_ 1193 CF_AVN_SEA_NEWNValueSet "This signal is userd for SEA from KA4/NX4.

Before KA4, SEA and SEW are merged using CF_AVN_SEANValueSet@HU_USM_E_01";
BA_ "GenSigSendType" SG_ 1193 CF_AVN_SEA_NEWNValueSet 4;
BA_ "UserSigValidity" SG_ 1193 CF_AVN_SEA_NEWNValueSet 3;
BA_ "Version" SG_ 1193 CF_AVN_SEA_NEWNValueSet "19.09.05";
BA_ "Description" SG_ 1193 CF_AVN_EscortHLNValueSet "18.08.09_";
BA_ "GenSigSendType" SG_ 1193 CF_AVN_EscortHLNValueSet 4;
BA_ "UserSigValidity" SG_ 1193 CF_AVN_EscortHLNValueSet 3;
BA_ "Version" SG_ 1193 CF_AVN_EscortHLNValueSet "18.09.04";
BA_ "GenMsgCycleTime" BO_ 1195 0;
BA_ "Description" SG_ 1195 CF_AVN_CluWelcomeSnd "16.06.04_";
BA_ "GenSigSendType" SG_ 1195 CF_AVN_CluWelcomeSnd 4;
BA_ "UserSigValidity" SG_ 1195 CF_AVN_CluWelcomeSnd 3;
BA_ "Version" SG_ 1195 CF_AVN_CluWelcomeSnd "18.04.02";
BA_ "Description" SG_ 1195 CF_AVN_CluTransmissionDisp "16.06.04_";
BA_ "GenSigSendType" SG_ 1195 CF_AVN_CluTransmissionDisp 4;
BA_ "UserSigValidity" SG_ 1195 CF_AVN_CluTransmissionDisp 3;
BA_ "Version" SG_ 1195 CF_AVN_CluTransmissionDisp "18.04.02";
BA_ "Description" SG_ 1195 CF_AVN_CluWiperLight "16.06.04_";
BA_ "GenSigSendType" SG_ 1195 CF_AVN_CluWiperLight 4;
BA_ "UserSigValidity" SG_ 1195 CF_AVN_CluWiperLight 3;
BA_ "Version" SG_ 1195 CF_AVN_CluWiperLight "18.04.02";
BA_ "Description" SG_ 1195 CF_AVN_CluRoadInfoGuide "16.06.04_";
BA_ "GenSigSendType" SG_ 1195 CF_AVN_CluRoadInfoGuide 4;
BA_ "UserSigValidity" SG_ 1195 CF_AVN_CluRoadInfoGuide 3;
BA_ "Version" SG_ 1195 CF_AVN_CluRoadInfoGuide "18.04.02";
BA_ "Description" SG_ 1195 CF_AVN_CluUserSettingPeriod "16.06.04_";
BA_ "GenSigSendType" SG_ 1195 CF_AVN_CluUserSettingPeriod 4;
BA_ "GenSigStartValue" SG_ 1195 CF_AVN_CluUserSettingPeriod 127;
BA_ "UserSigValidity" SG_ 1195 CF_AVN_CluUserSettingPeriod 3;
BA_ "Version" SG_ 1195 CF_AVN_CluUserSettingPeriod "19.01.10";
BA_ "Description" SG_ 1195 CF_AVN_CluAutoInitFuelEconomy "16.06.04_";
BA_ "GenSigSendType" SG_ 1195 CF_AVN_CluAutoInitFuelEconomy 4;
BA_ "UserSigValidity" SG_ 1195 CF_AVN_CluAutoInitFuelEconomy 3;
BA_ "Version" SG_ 1195 CF_AVN_CluAutoInitFuelEconomy "18.04.02";
BA_ "Description" SG_ 1195 CF_AVN_CluFuelEconUnit_mi "18.08.08_";
BA_ "GenSigSendType" SG_ 1195 CF_AVN_CluFuelEconUnit_mi 4;
BA_ "UserSigValidity" SG_ 1195 CF_AVN_CluFuelEconUnit_mi 3;
BA_ "Version" SG_ 1195 CF_AVN_CluFuelEconUnit_mi "18.09.04";
BA_ "GenSigSendType" SG_ 1195 CF_AVN_CluFuelEconUnit_km 4;
BA_ "UserSigValidity" SG_ 1195 CF_AVN_CluFuelEconUnit_km 3;
BA_ "Version" SG_ 1195 CF_AVN_CluFuelEconUnit_km "20.08.02";
BA_ "Description" SG_ 1195 CF_AVN_CluUserSettingDistance "16.06.04_";
BA_ "GenSigSendType" SG_ 1195 CF_AVN_CluUserSettingDistance 4;
BA_ "GenSigStartValue" SG_ 1195 CF_AVN_CluUserSettingDistance 131071;
BA_ "UserSigValidity" SG_ 1195 CF_AVN_CluUserSettingDistance 3;
BA_ "Version" SG_ 1195 CF_AVN_CluUserSettingDistance "19.01.10";
BA_ "Description" SG_ 1195 CF_AVN_CluRheostatLvl "18.06.00_";
BA_ "GenSigSendType" SG_ 1195 CF_AVN_CluRheostatLvl 4;
BA_ "GenSigStartValue" SG_ 1195 CF_AVN_CluRheostatLvl 31;
BA_ "UserSigValidity" SG_ 1195 CF_AVN_CluRheostatLvl 3;
BA_ "Version" SG_ 1195 CF_AVN_CluRheostatLvl "18.06.04";
BA_ "Description" SG_ 1195 CF_AVN_CluVoiceVolume "16.06.04_";
BA_ "GenSigSendType" SG_ 1195 CF_AVN_CluVoiceVolume 4;
BA_ "UserSigValidity" SG_ 1195 CF_AVN_CluVoiceVolume 3;
BA_ "Version" SG_ 1195 CF_AVN_CluVoiceVolume "18.04.02";
BA_ "Description" SG_ 1195 CF_AVN_EVReset "18.08.08_Request to reset EV Service (0x1 : EV USM Reset)";
BA_ "GenSigSendType" SG_ 1195 CF_AVN_EVReset 4;
BA_ "UserSigValidity" SG_ 1195 CF_AVN_EVReset 7;
BA_ "Version" SG_ 1195 CF_AVN_EVReset "18.09.04";
BA_ "Description" SG_ 1195 CF_AVN_UnitReset "18.08.08_";
BA_ "GenSigSendType" SG_ 1195 CF_AVN_UnitReset 4;
BA_ "UserSigValidity" SG_ 1195 CF_AVN_UnitReset 3;
BA_ "Version" SG_ 1195 CF_AVN_UnitReset "18.09.04";
BA_ "Description" SG_ 1195 CF_AVN_IcyRoadWarn "17.02.05_";
BA_ "GenSigSendType" SG_ 1195 CF_AVN_IcyRoadWarn 4;
BA_ "UserSigValidity" SG_ 1195 CF_AVN_IcyRoadWarn 3;
BA_ "Version" SG_ 1195 CF_AVN_IcyRoadWarn "18.04.02";
BA_ "Description" SG_ 1195 CF_AVN_CluServiceReminderReset "16.11.03_";
BA_ "GenSigSendType" SG_ 1195 CF_AVN_CluServiceReminderReset 4;
BA_ "UserSigValidity" SG_ 1195 CF_AVN_CluServiceReminderReset 3;
BA_ "Version" SG_ 1195 CF_AVN_CluServiceReminderReset "18.04.02";
BA_ "GenSigSendType" SG_ 1195 CF_AVN_CluUSMReset 4;
BA_ "UserSigValidity" SG_ 1195 CF_AVN_CluUSMReset 3;
BA_REL_ "GenSigTimeoutTime" BU_SG_REL_ WPC SG_ 1195 CF_AVN_CluUSMReset 0;
BA_REL_ "GenSigTimeoutTime" BU_SG_REL_ RWPC SG_ 1195 CF_AVN_CluUSMReset 0;
BA_REL_ "GenSigTimeoutTime" BU_SG_REL_ PSB SG_ 1195 CF_AVN_CluUSMReset 0;
BA_REL_ "GenSigTimeoutTime" BU_SG_REL_ SLB SG_ 1195 CF_AVN_CluUSMReset 0;
BA_REL_ "GenSigTimeoutTime" BU_SG_REL_ APSU SG_ 1195 CF_AVN_CluUSMReset 0;
BA_REL_ "GenSigTimeoutTime" BU_SG_REL_ RLHV SG_ 1195 CF_AVN_CluUSMReset 0;
BA_REL_ "GenSigTimeoutTime" BU_SG_REL_ RRHV SG_ 1195 CF_AVN_CluUSMReset 0;
BA_REL_ "GenSigTimeoutTime" BU_SG_REL_ SHVU_FR SG_ 1195 CF_AVN_CluUSMReset 0;
BA_REL_ "GenSigTimeoutTime" BU_SG_REL_ SHVU_RR SG_ 1195 CF_AVN_CluUSMReset 0;
BA_REL_ "GenSigTimeoutTime" BU_SG_REL_ DPSU SG_ 1195 CF_AVN_CluUSMReset 0;
BA_REL_ "GenSigTimeoutTime" BU_SG_REL_ DLBCU SG_ 1195 CF_AVN_CluUSMReset 0;
BA_REL_ "GenSigTimeoutTime" BU_SG_REL_ PFSU SG_ 1195 CF_AVN_CluUSMReset 0;
BA_REL_ "GenSigTimeoutTime" BU_SG_REL_ RRPSU SG_ 1195 CF_AVN_CluUSMReset 0;
BA_REL_ "GenSigTimeoutTime" BU_SG_REL_ RLPSU SG_ 1195 CF_AVN_CluUSMReset 0;
BA_REL_ "GenSigTimeoutTime" BU_SG_REL_ ATS SG_ 1195 CF_AVN_CluUSMReset 0;
BA_REL_ "GenSigTimeoutTime" BU_SG_REL_ DSAU SG_ 1195 CF_AVN_CluUSMReset 0;
BA_REL_ "GenSigTimeoutTime" BU_SG_REL_ ASAU SG_ 1195 CF_AVN_CluUSMReset 0;
BA_REL_ "GenSigTimeoutTime" BU_SG_REL_ BLTN_CAM SG_ 1195 CF_AVN_CluUSMReset 0;
BA_REL_ "GenSigTimeoutTime" BU_SG_REL_ ALBCU SG_ 1195 CF_AVN_CluUSMReset 0;
BA_ "Version" SG_ 1195 CF_AVN_CluUSMReset "21.01.08";
BA_ "Description" SG_ 1195 CF_AVN_CluServiceReminderSet "16.06.04_";
BA_ "GenSigSendType" SG_ 1195 CF_AVN_CluServiceReminderSet 4;
BA_ "UserSigValidity" SG_ 1195 CF_AVN_CluServiceReminderSet 3;
BA_ "Version" SG_ 1195 CF_AVN_CluServiceReminderSet "18.04.02";
BA_ "GenMsgCycleTime" BO_ 1196 0;
BA_ "Description" SG_ 1196 C_HCIMSWeightNValueSet "18.08.09_";
BA_ "GenSigSendType" SG_ 1196 C_HCIMSWeightNValueSet 4;
BA_ "UserSigValidity" SG_ 1196 C_HCIMSWeightNValueSet 3;
BA_REL_ "GenSigTimeoutTime" BU_SG_REL_ DPSU SG_ 1196 C_HCIMSWeightNValueSet 0;
BA_ "Version" SG_ 1196 C_HCIMSWeightNValueSet "18.09.04";
BA_ "Description" SG_ 1196 C_HCIMSSitHeightNValueSet "18.08.09_";
BA_ "GenSigSendType" SG_ 1196 C_HCIMSSitHeightNValueSet 4;
BA_ "UserSigValidity" SG_ 1196 C_HCIMSSitHeightNValueSet 3;
BA_REL_ "GenSigTimeoutTime" BU_SG_REL_ DPSU SG_ 1196 C_HCIMSSitHeightNValueSet 0;
BA_ "Version" SG_ 1196 C_HCIMSSitHeightNValueSet "18.09.04";
BA_ "Description" SG_ 1196 CF_AVN_BodySpprtSet "18.11.00_This signal is for the seat body support USM";
BA_ "GenSigSendType" SG_ 1196 CF_AVN_BodySpprtSet 4;
BA_ "GenSigStartValue" SG_ 1196 CF_AVN_BodySpprtSet 3;
BA_ "UserSigValidity" SG_ 1196 CF_AVN_BodySpprtSet 3;
BA_REL_ "GenSigTimeoutTime" BU_SG_REL_ DPSU SG_ 1196 CF_AVN_BodySpprtSet 0;
BA_REL_ "GenSigTimeoutTime" BU_SG_REL_ DLBCU SG_ 1196 CF_AVN_BodySpprtSet 0;
BA_REL_ "GenSigTimeoutTime" BU_SG_REL_ DSAU SG_ 1196 CF_AVN_BodySpprtSet 0;
BA_ "Version" SG_ 1196 CF_AVN_BodySpprtSet "18.11.01";
BA_ "Description" SG_ 1196 CF_AVN_AirSptTimeNValueSet "18.08.09_This signal is for the seat massage function time setting";
BA_ "GenSigSendType" SG_ 1196 CF_AVN_AirSptTimeNValueSet 4;
BA_ "GenSigStartValue" SG_ 1196 CF_AVN_AirSptTimeNValueSet 7;
BA_ "UserSigValidity" SG_ 1196 CF_AVN_AirSptTimeNValueSet 3;
BA_REL_ "GenSigTimeoutTime" BU_SG_REL_ DLBCU SG_ 1196 CF_AVN_AirSptTimeNValueSet 0;
BA_ "Version" SG_ 1196 CF_AVN_AirSptTimeNValueSet "18.09.04";
BA_ "Description" SG_ 1196 CF_AVN_AirSptStrNValue "18.08.09_This signal is for the seat massage intensity USM";
BA_ "GenSigSendType" SG_ 1196 CF_AVN_AirSptStrNValue 4;
BA_ "GenSigStartValue" SG_ 1196 CF_AVN_AirSptStrNValue 3;
BA_ "UserSigValidity" SG_ 1196 CF_AVN_AirSptStrNValue 3;
BA_REL_ "GenSigTimeoutTime" BU_SG_REL_ DLBCU SG_ 1196 CF_AVN_AirSptStrNValue 0;
BA_ "Version" SG_ 1196 CF_AVN_AirSptStrNValue "18.09.04";
BA_ "Description" SG_ 1196 CF_AVN_SeatDrvModNValueSet "18.08.09_This signal is for the auto seat-drivemode user setting menu";
BA_ "GenSigSendType" SG_ 1196 CF_AVN_SeatDrvModNValueSet 4;
BA_ "GenSigStartValue" SG_ 1196 CF_AVN_SeatDrvModNValueSet 3;
BA_ "UserSigValidity" SG_ 1196 CF_AVN_SeatDrvModNValueSet 3;
BA_REL_ "GenSigTimeoutTime" BU_SG_REL_ DPSU SG_ 1196 CF_AVN_SeatDrvModNValueSet 0;
BA_REL_ "GenSigTimeoutTime" BU_SG_REL_ DLBCU SG_ 1196 CF_AVN_SeatDrvModNValueSet 0;
BA_REL_ "GenSigTimeoutTime" BU_SG_REL_ DSAU SG_ 1196 CF_AVN_SeatDrvModNValueSet 0;
BA_ "Version" SG_ 1196 CF_AVN_SeatDrvModNValueSet "18.09.04";
BA_ "Description" SG_ 1196 C_HCIMSHeightNvalueSet "18.08.09_";
BA_ "GenSigSendType" SG_ 1196 C_HCIMSHeightNvalueSet 4;
BA_ "UserSigValidity" SG_ 1196 C_HCIMSHeightNvalueSet 3;
BA_REL_ "GenSigTimeoutTime" BU_SG_REL_ DPSU SG_ 1196 C_HCIMSHeightNvalueSet 0;
BA_ "Version" SG_ 1196 C_HCIMSHeightNvalueSet "18.09.04";
BA_ "Description" SG_ 1196 C_SLB_SmartCtrl_NValue "USM Reqest for Smart Posture Care 2.0 On/Off";
BA_ "GenSigSendType" SG_ 1196 C_SLB_SmartCtrl_NValue 4;
BA_ "UserSigValidity" SG_ 1196 C_SLB_SmartCtrl_NValue 3;
BA_ "Version" SG_ 1196 C_SLB_SmartCtrl_NValue "19.04.01";
BA_ "Description" SG_ 1196 CF_AVN_CushSoftNValueSet "18.10.03_This signal is for the cushsoftness setting";
BA_ "GenSigSendType" SG_ 1196 CF_AVN_CushSoftNValueSet 4;
BA_ "GenSigStartValue" SG_ 1196 CF_AVN_CushSoftNValueSet 7;
BA_ "UserSigValidity" SG_ 1196 CF_AVN_CushSoftNValueSet 3;
BA_REL_ "GenSigTimeoutTime" BU_SG_REL_ DLBCU SG_ 1196 CF_AVN_CushSoftNValueSet 0;
BA_ "Version" SG_ 1196 CF_AVN_CushSoftNValueSet "18.10.05";
BA_ "Description" SG_ 1196 C_SmrtSldngDrNValueSet "USM request for Smart Sliding Door";
BA_ "GenSigSendType" SG_ 1196 C_SmrtSldngDrNValueSet 4;
BA_ "UserSigValidity" SG_ 1196 C_SmrtSldngDrNValueSet 3;
BA_ "Version" SG_ 1196 C_SmrtSldngDrNValueSet "19.01.10";
BA_ "Description" SG_ 1196 CF_AVN_TurboPressureUnit "USM Request for Turbo Boost Pressure Unit";
BA_ "GenSigSendType" SG_ 1196 CF_AVN_TurboPressureUnit 4;
BA_ "UserSigValidity" SG_ 1196 CF_AVN_TurboPressureUnit 3;
BA_ "Version" SG_ 1196 CF_AVN_TurboPressureUnit "19.06.02";
BA_ "Description" SG_ 1196 CF_AVN_CluTorqueUnit "USM Request for Torque Unit Setting";
BA_ "GenSigSendType" SG_ 1196 CF_AVN_CluTorqueUnit 4;
BA_ "UserSigValidity" SG_ 1196 CF_AVN_CluTorqueUnit 3;
BA_ "Version" SG_ 1196 CF_AVN_CluTorqueUnit "19.06.02";
BA_ "Description" SG_ 1196 AVN_Usm_CluThemeAutoSet "USM response for Cluster theme auto setting";
BA_ "GenSigSendType" SG_ 1196 AVN_Usm_CluThemeAutoSet 4;
BA_ "UserSigValidity" SG_ 1196 AVN_Usm_CluThemeAutoSet 3;
BA_ "Version" SG_ 1196 AVN_Usm_CluThemeAutoSet "19.06.00";
BA_ "Description" SG_ 1196 AVN_Usm_CluFuelEconomySet "USM request for Fuel economy auto reset";
BA_ "GenSigSendType" SG_ 1196 AVN_Usm_CluFuelEconomySet 4;
BA_ "UserSigValidity" SG_ 1196 AVN_Usm_CluFuelEconomySet 3;
BA_ "Version" SG_ 1196 AVN_Usm_CluFuelEconomySet "19.06.00";
BA_ "Description" SG_ 1196 CF_AVN_HCIMSButtonCommand "18.08.09_";
BA_ "GenSigSendType" SG_ 1196 CF_AVN_HCIMSButtonCommand 4;
BA_ "UserSigValidity" SG_ 1196 CF_AVN_HCIMSButtonCommand 3;
BA_REL_ "GenSigTimeoutTime" BU_SG_REL_ DPSU SG_ 1196 CF_AVN_HCIMSButtonCommand 0;
BA_ "Version" SG_ 1196 CF_AVN_HCIMSButtonCommand "18.09.04";
BA_ "GenMsgSendType" BO_ 1167 0;
BA_ "GenMsgCycleTime" BO_ 1167 1000;
BA_ "Description" SG_ 1167 ICU_Crc11Val "The data area for CRC calculation is based on the data length (DLC) of the message DB.

The CRC shall be calculated over the entire data block (excluding the CRC bytes) including the user data, alive counter and Data ID 

 

- CRC Polynomial (0x1D) , Initial Value : 0x00, XOR value : 0xFF, Data ID Mode : Both, Data ID : Message ID + 0xF800 

- The initial value is for CRC calculation and the message should be sent with the calculated result value. 

The mathematical expression to 8 bit CRC polynomial is given here. G(x) = x8 + x4 + x3 + x2 + 1";
BA_ "GenSigSendType" SG_ 1167 ICU_Crc11Val 4;
BA_ "GenSigStartValue" SG_ 1167 ICU_Crc11Val 255;
BA_ "UserSigValidity" SG_ 1167 ICU_Crc11Val 0;
BA_ "Version" SG_ 1167 ICU_Crc11Val "18.11.08";
BA_ "Description" SG_ 1167 Bat_dischrg "Battery discharge notification flag";
BA_ "GenSigSendType" SG_ 1167 Bat_dischrg 4;
BA_ "UserSigValidity" SG_ 1167 Bat_dischrg 3;
BA_ "Version" SG_ 1167 Bat_dischrg "21.07.05";
BA_ "Description" SG_ 1167 ICU_AlvCnt11Val "For the first transmission request for a data element the counter shall be initialized with 0 and shall be incremented by 1

for every subsequent send request. When the counter reaches the maximum value(0xE), then it shall restart with 0 for the next send request";
BA_ "GenSigSendType" SG_ 1167 ICU_AlvCnt11Val 4;
BA_ "UserSigValidity" SG_ 1167 ICU_AlvCnt11Val 0;
BA_ "Version" SG_ 1167 ICU_AlvCnt11Val "18.11.08";
BA_ "Description" SG_ 1167 Batt_SoCWarningValue "This signal is Battery SOC from battery sensor.";
BA_ "GenSigSendType" SG_ 1167 Batt_SoCWarningValue 4;
BA_ "GenSigStartValue" SG_ 1167 Batt_SoCWarningValue 255;
BA_ "UserSigValidity" SG_ 1167 Batt_SoCWarningValue 0;
BA_ "Version" SG_ 1167 Batt_SoCWarningValue "17.12.00";
BA_ "Description" SG_ 1167 C_StrgWhlHeatingOpt "Steering wheel heating option signal";
BA_ "GenSigSendType" SG_ 1167 C_StrgWhlHeatingOpt 4;
BA_ "UserSigValidity" SG_ 1167 C_StrgWhlHeatingOpt 3;
BA_ "Version" SG_ 1167 C_StrgWhlHeatingOpt "18.12.02";
BA_ "Description" SG_ 1167 C_StrgWhlHeatingSWInf "Steering wheel heating Step information signal";
BA_ "GenSigSendType" SG_ 1167 C_StrgWhlHeatingSWInf 4;
BA_ "UserSigValidity" SG_ 1167 C_StrgWhlHeatingSWInf 3;
BA_ "Version" SG_ 1167 C_StrgWhlHeatingSWInf "19.11.11";
BA_ "Description" SG_ 1167 ICU_BattAutoCutPreWrng "This is a warning signal before blocking the dark current of the ICU by the battery SOC.";
BA_ "GenSigSendType" SG_ 1167 ICU_BattAutoCutPreWrng 4;
BA_ "GenSigStartValue" SG_ 1167 ICU_BattAutoCutPreWrng 3;
BA_ "UserSigValidity" SG_ 1167 ICU_BattAutoCutPreWrng 0;
BA_REL_ "GenSigTimeoutTime" BU_SG_REL_ BLTN_CAM SG_ 1167 ICU_BattAutoCutPreWrng 5000;
BA_ "Version" SG_ 1167 ICU_BattAutoCutPreWrng "20.04.06";
BA_ "Description" SG_ 1167 IGN_AutoOff_WarnSta_CLU "This signal is for battery discharge warning (engine not running && IGN/ACC on)

To prevent battery discharge, ICU requests the Cluster to display warning and requests IBU to turn IGN/ACC off.";
BA_ "GenSigSendType" SG_ 1167 IGN_AutoOff_WarnSta_CLU 4;
BA_ "UserSigValidity" SG_ 1167 IGN_AutoOff_WarnSta_CLU 3;
BA_ "Version" SG_ 1167 IGN_AutoOff_WarnSta_CLU "20.07.10";
BA_ "Description" SG_ 1167 PDC_BatPwrStateClassA "Battery Power State ClassA";
BA_ "GenSigSendType" SG_ 1167 PDC_BatPwrStateClassA 4;
BA_ "UserSigValidity" SG_ 1167 PDC_BatPwrStateClassA 0;
BA_ "Version" SG_ 1167 PDC_BatPwrStateClassA "21.04.08";
BA_ "Description" SG_ 1167 PDC_BatPwrStateClassB "Battery Power State ClassB";
BA_ "GenSigSendType" SG_ 1167 PDC_BatPwrStateClassB 4;
BA_ "UserSigValidity" SG_ 1167 PDC_BatPwrStateClassB 0;
BA_ "Version" SG_ 1167 PDC_BatPwrStateClassB "21.04.08";
BA_ "Description" SG_ 1167 PDC_BatPwrStateClassC "Battery Power State ClassC";
BA_ "GenSigSendType" SG_ 1167 PDC_BatPwrStateClassC 4;
BA_ "UserSigValidity" SG_ 1167 PDC_BatPwrStateClassC 0;
BA_ "Version" SG_ 1167 PDC_BatPwrStateClassC "21.04.08";
BA_ "Description" SG_ 1167 PLBMAvailableState "Power supply Available status notification at PLBM. If this value is Set, BMS can request Discharge-request to PDC during parking mode";
BA_ "GenSigSendType" SG_ 1167 PLBMAvailableState 4;
BA_ "UserSigValidity" SG_ 1167 PLBMAvailableState 0;
BA_ "Version" SG_ 1167 PLBMAvailableState "21.06.11";
BA_ "Description" SG_ 1167 IGN_AutoOff_WarnSta "This signal is for battery discharge warning (engine not running && IGN/ACC on)

To prevent battery discharge, ICU requests the head unit to display warning and requests IBU to turn IGN/ACC off.";
BA_ "GenSigSendType" SG_ 1167 IGN_AutoOff_WarnSta 4;
BA_ "UserSigValidity" SG_ 1167 IGN_AutoOff_WarnSta 3;
BA_ "Version" SG_ 1167 IGN_AutoOff_WarnSta "20.03.03";
BA_ "GenMsgSendType" BO_ 1171 0;
BA_ "Description" SG_ 1171 RLPSM_SWVerMajor1 "Indicate the SCM software version as follows:

- The software version is displayed in three digits.

- The Major and Minor digits are separated by '.'

- Signal values are transmitted to ASCII codes.



¡Ø Example

RLPSM_SWVerMajor1 : 0x41 (HEX) -> ASCII CODE : 'A' 

RLPSM_SWVerMinor1 : 0x30 (HEX) -> ASCII CODE : '0'

RLPSM_SWVerMinor2 : 0x33 (HEX) -> ASCII CODE : '3'

=> RLPSM S/W Ver is displayed 'A.03'";
BA_ "GenSigSendType" SG_ 1171 RLPSM_SWVerMajor1 4;
BA_ "UserSigValidity" SG_ 1171 RLPSM_SWVerMajor1 0;
BA_ "RoutingFactor" SG_ 1171 RLPSM_SWVerMajor1 0;
BA_ "Version" SG_ 1171 RLPSM_SWVerMajor1 "21.07.00";
BA_ "Description" SG_ 1171 RLPSM_SWVerMinor2 "Indicate the APSM software version as follows:

- The software version is displayed in three digits.

- The Major and Minor digits are separated by '.'

- Signal values are transmitted to ASCII codes.



¡Ø Example

RLPSM_SWVerMajor1 : 0x41 (HEX) -> ASCII CODE : 'A' 

RLPSM_SWVerMinor1 : 0x30 (HEX) -> ASCII CODE : '0'

RLPSM_SWVerMinor2 : 0x33 (HEX) -> ASCII CODE : '3'

=> RLPSM S/W Ver is displayed 'A.03'";
BA_ "GenSigSendType" SG_ 1171 RLPSM_SWVerMinor2 4;
BA_ "UserSigValidity" SG_ 1171 RLPSM_SWVerMinor2 0;
BA_ "RoutingFactor" SG_ 1171 RLPSM_SWVerMinor2 0;
BA_ "Version" SG_ 1171 RLPSM_SWVerMinor2 "20.04.06";
BA_ "Description" SG_ 1171 RLPSM_SWVerMinor1 "Indicate the APSM software version as follows:

- The software version is displayed in three digits.

- The Major and Minor digits are separated by '.'

- Signal values are transmitted to ASCII codes.



¡Ø Example

RLPSM_SWVerMajor1 : 0x41 (HEX) -> ASCII CODE : 'A' 

RLPSM_SWVerMinor1 : 0x30 (HEX) -> ASCII CODE : '0'

RLPSM_SWVerMinor2 : 0x33 (HEX) -> ASCII CODE : '3'

=> RLPSM S/W Ver is displayed 'A.03'";
BA_ "GenSigSendType" SG_ 1171 RLPSM_SWVerMinor1 4;
BA_ "UserSigValidity" SG_ 1171 RLPSM_SWVerMinor1 0;
BA_ "RoutingFactor" SG_ 1171 RLPSM_SWVerMinor1 0;
BA_ "Version" SG_ 1171 RLPSM_SWVerMinor1 "20.04.06";
BA_ "GenMsgCycleTime" BO_ 1181 0;
BA_ "Description" SG_ 1181 RL_SHVU_SeatEcoSta "ÈÄ¼® LH ½ÃÆ® ¿¡ÄÚÇÃ·¯½º ¸ðµå ÁøÀÔ Á¤º¸";
BA_ "GenSigSendType" SG_ 1181 RL_SHVU_SeatEcoSta 4;
BA_ "UserSigValidity" SG_ 1181 RL_SHVU_SeatEcoSta 3;
BA_REL_ "GenSigTimeoutTime" BU_SG_REL_ ATS SG_ 1181 RL_SHVU_SeatEcoSta 0;
BA_REL_ "GenSigTimeoutTime" BU_SG_REL_ CGW_CCU SG_ 1181 RL_SHVU_SeatEcoSta 0;
BA_ "NetworkRequest" SG_ 1181 RL_SHVU_SeatEcoSta 0;
BA_ "NetworkRequestHoldingTime" SG_ 1181 RL_SHVU_SeatEcoSta 5000;
BA_ "Version" SG_ 1181 RL_SHVU_SeatEcoSta "21.07.06";
BA_ "GenMsgSendType" BO_ 1172 0;
BA_ "Description" SG_ 1172 RRPSM_SWVerMajor1 "Indicate the SCM software version as follows:

- The software version is displayed in three digits.

- The Major and Minor digits are separated by '.'

- Signal values are transmitted to ASCII codes.



¡Ø Example

RRPSM_SWVerMajor1 : 0x41 (HEX) -> ASCII CODE : 'A' 

RRPSM_SWVerMinor1 : 0x30 (HEX) -> ASCII CODE : '0'

RRPSM_SWVerMinor2 : 0x33 (HEX) -> ASCII CODE : '3'

=> RRPSM S/W Ver is displayed 'A.03'";
BA_ "GenSigSendType" SG_ 1172 RRPSM_SWVerMajor1 4;
BA_ "UserSigValidity" SG_ 1172 RRPSM_SWVerMajor1 0;
BA_ "RoutingFactor" SG_ 1172 RRPSM_SWVerMajor1 0;
BA_ "Version" SG_ 1172 RRPSM_SWVerMajor1 "21.07.00";
BA_ "Description" SG_ 1172 RRPSM_SWVerMinor2 "Indicate the APSM software version as follows:

- The software version is displayed in three digits.

- The Major and Minor digits are separated by '.'

- Signal values are transmitted to ASCII codes.



¡Ø Example

RRPSM_SWVerMajor1 : 0x41 (HEX) -> ASCII CODE : 'A' 

RRPSM_SWVerMinor1 : 0x30 (HEX) -> ASCII CODE : '0'

RRPSM_SWVerMinor2 : 0x33 (HEX) -> ASCII CODE : '3'

=> RRPSM S/W Ver is displayed 'A.03'";
BA_ "GenSigSendType" SG_ 1172 RRPSM_SWVerMinor2 4;
BA_ "UserSigValidity" SG_ 1172 RRPSM_SWVerMinor2 0;
BA_ "RoutingFactor" SG_ 1172 RRPSM_SWVerMinor2 0;
BA_ "Version" SG_ 1172 RRPSM_SWVerMinor2 "20.04.06";
BA_ "Description" SG_ 1172 RRPSM_SWVerMinor1 "Indicate the APSM software version as follows:

- The software version is displayed in three digits.

- The Major and Minor digits are separated by '.'

- Signal values are transmitted to ASCII codes.



¡Ø Example

RRPSM_SWVerMajor1 : 0x41 (HEX) -> ASCII CODE : 'A' 

RRPSM_SWVerMinor1 : 0x30 (HEX) -> ASCII CODE : '0'

RRPSM_SWVerMinor2 : 0x33 (HEX) -> ASCII CODE : '3'

=> RRPSM S/W Ver is displayed 'A.03'";
BA_ "GenSigSendType" SG_ 1172 RRPSM_SWVerMinor1 4;
BA_ "UserSigValidity" SG_ 1172 RRPSM_SWVerMinor1 0;
BA_ "RoutingFactor" SG_ 1172 RRPSM_SWVerMinor1 0;
BA_ "Version" SG_ 1172 RRPSM_SWVerMinor1 "20.04.06";
BA_ "GenMsgCycleTime" BO_ 1182 0;
BA_ "Description" SG_ 1182 RR_SHVU_SeatEcoSta "ÈÄ¼® RH ½ÃÆ® ¿¡ÄÚÇÃ·¯½º ¸ðµå ÁøÀÔ Á¤º¸";
BA_ "GenSigSendType" SG_ 1182 RR_SHVU_SeatEcoSta 4;
BA_ "UserSigValidity" SG_ 1182 RR_SHVU_SeatEcoSta 3;
BA_REL_ "GenSigTimeoutTime" BU_SG_REL_ ATS SG_ 1182 RR_SHVU_SeatEcoSta 0;
BA_REL_ "GenSigTimeoutTime" BU_SG_REL_ CGW_CCU SG_ 1182 RR_SHVU_SeatEcoSta 0;
BA_ "NetworkRequest" SG_ 1182 RR_SHVU_SeatEcoSta 0;
BA_ "NetworkRequestHoldingTime" SG_ 1182 RR_SHVU_SeatEcoSta 5000;
BA_ "Version" SG_ 1182 RR_SHVU_SeatEcoSta "21.07.06";
BA_ "GenMsgSendType" BO_ 208 0;
BA_ "Description" SG_ 208 RR_SHVU_DTCdisplay "0x00: DTC is not exist(Fail is not exist)/0x01:IGN2 Fuse Open Detection/0x02:Switch Input Detection at Same Time/0x03:NTC/Heating wire Open Detection/0x04:NTC+/NTC- Terminal Short Detection/0x05:NTC+/Heater+ Terminal Short Detection/0x06:NTC+/Heater-, Heater+/Heater-, Heater+/NTC- Terminal Short Detection/0x07:NTC+/Heater- Wiring Short Detection/0x08:NTC+/Heater-, Heater+/Heater-, Heater+/NTC- Wiring Short Detection/0x09:Target Temperature Dissatisfied/0x0A:Blower+/Blower- Short, Blower+/Blower Speed, Blower-/Blower Speed Wiring Short Detection/0x0B:Blower+/Blower RPM, Blower-/Blower RPM, Blower Speed/Blower RPM Short Detection/0x0C:Blower+, Blower-, Blower Speed Signal open Detection/0x0D:Blower RPM signal Open Detection/0x0E~0xFD:Unused/0xFE:No Display/0xFF:Invalid";
BA_ "GenSigSendType" SG_ 208 RR_SHVU_DTCdisplay 4;
BA_ "UserSigValidity" SG_ 208 RR_SHVU_DTCdisplay 3;
BA_REL_ "GenSigTimeoutTime" BU_SG_REL_ ATS SG_ 208 RR_SHVU_DTCdisplay 1500;
BA_ "NetworkRequest" SG_ 208 RR_SHVU_DTCdisplay 0;
BA_ "NetworkRequestHoldingTime" SG_ 208 RR_SHVU_DTCdisplay 5000;
BA_ "Version" SG_ 208 RR_SHVU_DTCdisplay "19.11.06";
BA_ "Description" SG_ 208 RR_SHVU_DiagMode "0x0:Default/0x1:DTC Mode/0x2:Normal Mode/0x3:Invalid";
BA_ "GenSigSendType" SG_ 208 RR_SHVU_DiagMode 4;
BA_ "UserSigValidity" SG_ 208 RR_SHVU_DiagMode 3;
BA_REL_ "GenSigTimeoutTime" BU_SG_REL_ ATS SG_ 208 RR_SHVU_DiagMode 1500;
BA_ "NetworkRequest" SG_ 208 RR_SHVU_DiagMode 0;
BA_ "NetworkRequestHoldingTime" SG_ 208 RR_SHVU_DiagMode 5000;
BA_ "Version" SG_ 208 RR_SHVU_DiagMode "19.11.06";
BA_ "GenMsgSendType" BO_ 761 0;
BA_ "Description" SG_ 761 SBCM_AST_Crc3Val "The data area for CRC calculation is based on the data length (DLC) of the message DB.

The CRC shall be calculated over the entire data block (excluding the CRC bytes) including the user data, alive counter and Data ID 

 

- CRC Polynomial (0x1D) , Initial Value : 0x00, XOR value : 0xFF, Data ID Mode : Both, Data ID : Message ID + 0xF800 

- The initial value is for CRC calculation and the message should be sent with the calculated result value. 

The mathematical expression to 8 bit CRC polynomial is given here. G(x) = x8 + x4 + x3 + x2 + 1";
BA_ "GenSigSendType" SG_ 761 SBCM_AST_Crc3Val 4;
BA_ "GenSigStartValue" SG_ 761 SBCM_AST_Crc3Val 255;
BA_ "UserSigValidity" SG_ 761 SBCM_AST_Crc3Val 3;
BA_ "RoutingFactor" SG_ 761 SBCM_AST_Crc3Val 0;
BA_ "Version" SG_ 761 SBCM_AST_Crc3Val "20.12.04";
BA_ "GenSigSendType" SG_ 761 CDM_TypeOption_AST 4;
BA_ "UserSigValidity" SG_ 761 CDM_TypeOption_AST 7;
BA_ "NetworkRequest" SG_ 761 CDM_TypeOption_AST 0;
BA_ "NetworkRequestHoldingTime" SG_ 761 CDM_TypeOption_AST 5000;
BA_ "RoutingFactor" SG_ 761 CDM_TypeOption_AST 0;
BA_ "Version" SG_ 761 CDM_TypeOption_AST "20.12.04";
BA_ "Description" SG_ 761 SBCM_AST_AlvCnt3Val "For the first transmission request for a data element the counter shall be initialized with 0 and shall be incremented by 1

for every subsequent send request. When the counter reaches the maximum value(0xE), then it shall restart with 0 for the next send request";
BA_ "GenSigSendType" SG_ 761 SBCM_AST_AlvCnt3Val 4;
BA_ "UserSigValidity" SG_ 761 SBCM_AST_AlvCnt3Val 3;
BA_ "RoutingFactor" SG_ 761 SBCM_AST_AlvCnt3Val 0;
BA_ "Version" SG_ 761 SBCM_AST_AlvCnt3Val "20.12.04";
BA_ "GenSigSendType" SG_ 761 CDM_ImmeChgSw_AST 4;
BA_ "UserSigValidity" SG_ 761 CDM_ImmeChgSw_AST 7;
BA_ "NetworkRequest" SG_ 761 CDM_ImmeChgSw_AST 0;
BA_ "NetworkRequestHoldingTime" SG_ 761 CDM_ImmeChgSw_AST 5000;
BA_ "RoutingFactor" SG_ 761 CDM_ImmeChgSw_AST 0;
BA_ "Version" SG_ 761 CDM_ImmeChgSw_AST "20.12.04";
BA_ "GenSigSendType" SG_ 761 CDM_ChgDrSwFrt_AST 4;
BA_ "UserSigValidity" SG_ 761 CDM_ChgDrSwFrt_AST 7;
BA_ "NetworkRequest" SG_ 761 CDM_ChgDrSwFrt_AST 0;
BA_ "NetworkRequestHoldingTime" SG_ 761 CDM_ChgDrSwFrt_AST 5000;
BA_ "RoutingFactor" SG_ 761 CDM_ChgDrSwFrt_AST 0;
BA_ "Version" SG_ 761 CDM_ChgDrSwFrt_AST "20.12.04";
BA_ "GenSigSendType" SG_ 761 CDM_OpnClsState_AST 4;
BA_ "UserSigValidity" SG_ 761 CDM_OpnClsState_AST 7;
BA_ "NetworkRequest" SG_ 761 CDM_OpnClsState_AST 0;
BA_ "NetworkRequestHoldingTime" SG_ 761 CDM_OpnClsState_AST 5000;
BA_ "RoutingFactor" SG_ 761 CDM_OpnClsState_AST 0;
BA_ "Version" SG_ 761 CDM_OpnClsState_AST "20.12.04";
BA_ "GenSigSendType" SG_ 761 CDM_WarnMsg_AST 4;
BA_ "UserSigValidity" SG_ 761 CDM_WarnMsg_AST 7;
BA_ "NetworkRequest" SG_ 761 CDM_WarnMsg_AST 0;
BA_ "NetworkRequestHoldingTime" SG_ 761 CDM_WarnMsg_AST 5000;
BA_ "RoutingFactor" SG_ 761 CDM_WarnMsg_AST 0;
BA_ "Version" SG_ 761 CDM_WarnMsg_AST "20.12.04";
BA_ "GenSigSendType" SG_ 761 Mirror_RH_FoldingSta 4;
BA_ "UserSigValidity" SG_ 761 Mirror_RH_FoldingSta 0;
BA_ "NetworkRequest" SG_ 761 Mirror_RH_FoldingSta 0;
BA_ "NetworkRequestHoldingTime" SG_ 761 Mirror_RH_FoldingSta 5000;
BA_ "RoutingFactor" SG_ 761 Mirror_RH_FoldingSta 0;
BA_ "Version" SG_ 761 Mirror_RH_FoldingSta "20.12.04";
BA_ "GenSigSendType" SG_ 761 Mirror_RH_UnfoldingSta 4;
BA_ "UserSigValidity" SG_ 761 Mirror_RH_UnfoldingSta 0;
BA_ "NetworkRequest" SG_ 761 Mirror_RH_UnfoldingSta 0;
BA_ "NetworkRequestHoldingTime" SG_ 761 Mirror_RH_UnfoldingSta 5000;
BA_ "RoutingFactor" SG_ 761 Mirror_RH_UnfoldingSta 0;
BA_ "Version" SG_ 761 Mirror_RH_UnfoldingSta "20.12.04";
BA_ "GenSigSendType" SG_ 761 CDM_CmdStatus_AST 4;
BA_ "UserSigValidity" SG_ 761 CDM_CmdStatus_AST 7;
BA_ "NetworkRequest" SG_ 761 CDM_CmdStatus_AST 0;
BA_ "NetworkRequestHoldingTime" SG_ 761 CDM_CmdStatus_AST 5000;
BA_ "RoutingFactor" SG_ 761 CDM_CmdStatus_AST 0;
BA_ "Version" SG_ 761 CDM_CmdStatus_AST "20.12.04";
BA_ "GenSigSendType" SG_ 761 AST_CrashMRActAlarm 4;
BA_ "UserSigValidity" SG_ 761 AST_CrashMRActAlarm 0;
BA_ "NetworkRequest" SG_ 761 AST_CrashMRActAlarm 0;
BA_ "NetworkRequestHoldingTime" SG_ 761 AST_CrashMRActAlarm 5000;
BA_ "RoutingFactor" SG_ 761 AST_CrashMRActAlarm 0;
BA_ "Version" SG_ 761 AST_CrashMRActAlarm "20.12.05";
BA_ "GenSigSendType" SG_ 761 IMS_OSMirPlayBackSta_RH 4;
BA_ "UserSigValidity" SG_ 761 IMS_OSMirPlayBackSta_RH 0;
BA_REL_ "GenSigTimeoutTime" BU_SG_REL_ DPSU SG_ 761 IMS_OSMirPlayBackSta_RH 1500;
BA_ "NetworkRequest" SG_ 761 IMS_OSMirPlayBackSta_RH 0;
BA_ "NetworkRequestHoldingTime" SG_ 761 IMS_OSMirPlayBackSta_RH 5;
BA_ "RoutingFactor" SG_ 761 IMS_OSMirPlayBackSta_RH 0;
BA_ "Version" SG_ 761 IMS_OSMirPlayBackSta_RH "20.12.04";
BA_ "Description" SG_ 761 Mirror_RHVerPosVal "This signal indicates RH Outside Mirror Vertical Position Sensor Voltage";
BA_ "GenSigSendType" SG_ 761 Mirror_RHVerPosVal 4;
BA_ "UserSigValidity" SG_ 761 Mirror_RHVerPosVal 0;
BA_ "NetworkRequest" SG_ 761 Mirror_RHVerPosVal 0;
BA_ "NetworkRequestHoldingTime" SG_ 761 Mirror_RHVerPosVal 5000;
BA_ "RoutingFactor" SG_ 761 Mirror_RHVerPosVal 0;
BA_ "Version" SG_ 761 Mirror_RHVerPosVal "20.12.04";
BA_ "Description" SG_ 761 Mirror_RHHorPosVal "This signal indicates RH Outside Mirror Horizontal Position Sensor Voltage";
BA_ "GenSigSendType" SG_ 761 Mirror_RHHorPosVal 4;
BA_ "UserSigValidity" SG_ 761 Mirror_RHHorPosVal 0;
BA_ "NetworkRequest" SG_ 761 Mirror_RHHorPosVal 0;
BA_ "NetworkRequestHoldingTime" SG_ 761 Mirror_RHHorPosVal 5000;
BA_ "RoutingFactor" SG_ 761 Mirror_RHHorPosVal 0;
BA_ "Version" SG_ 761 Mirror_RHHorPosVal "20.12.04";
BA_ "GenSigSendType" SG_ 761 SBCM_AST_DiagSta 4;
BA_ "UserSigValidity" SG_ 761 SBCM_AST_DiagSta 0;
BA_ "NetworkRequest" SG_ 761 SBCM_AST_DiagSta 0;
BA_ "NetworkRequestHoldingTime" SG_ 761 SBCM_AST_DiagSta 5000;
BA_ "RoutingFactor" SG_ 761 SBCM_AST_DiagSta 0;
BA_ "Version" SG_ 761 SBCM_AST_DiagSta "20.12.04";
BA_ "GenMsgSendType" BO_ 758 0;
BA_ "Description" SG_ 758 SBCM_DRV_Crc2Val "The data area for CRC calculation is based on the data length (DLC) of the message DB.

The CRC shall be calculated over the entire data block (excluding the CRC bytes) including the user data, alive counter and Data ID 

 

- CRC Polynomial (0x1D) , Initial Value : 0x00, XOR value : 0xFF, Data ID Mode : Both, Data ID : Message ID + 0xF800 

- The initial value is for CRC calculation and the message should be sent with the calculated result value. 

The mathematical expression to 8 bit CRC polynomial is given here. G(x) = x8 + x4 + x3 + x2 + 1";
BA_ "GenSigSendType" SG_ 758 SBCM_DRV_Crc2Val 4;
BA_ "GenSigStartValue" SG_ 758 SBCM_DRV_Crc2Val 255;
BA_ "UserSigValidity" SG_ 758 SBCM_DRV_Crc2Val 3;
BA_ "RoutingFactor" SG_ 758 SBCM_DRV_Crc2Val 0;
BA_ "Version" SG_ 758 SBCM_DRV_Crc2Val "20.12.04";
BA_ "Description" SG_ 758 DoorLock_CtrlDrLkUnLkSwSta_SBCM "Central Door Lock/Unlock Switch State";
BA_ "GenSigSendType" SG_ 758 DoorLock_CtrlDrLkUnLkSwSta_SBCM 4;
BA_ "UserSigValidity" SG_ 758 DoorLock_CtrlDrLkUnLkSwSta_SBCM 0;
BA_ "NetworkRequest" SG_ 758 DoorLock_CtrlDrLkUnLkSwSta_SBCM 0;
BA_ "NetworkRequestHoldingTime" SG_ 758 DoorLock_CtrlDrLkUnLkSwSta_SBCM 5000;
BA_ "RoutingFactor" SG_ 758 DoorLock_CtrlDrLkUnLkSwSta_SBCM 0;
BA_ "Version" SG_ 758 DoorLock_CtrlDrLkUnLkSwSta_SBCM "20.12.04";
BA_ "Description" SG_ 758 SBCM_DRV_AlvCnt2Val "For the first transmission request for a data element the counter shall be initialized with 0 and shall be incremented by 1

for every subsequent send request. When the counter reaches the maximum value(0xE), then it shall restart with 0 for the next send request";
BA_ "GenSigSendType" SG_ 758 SBCM_DRV_AlvCnt2Val 4;
BA_ "UserSigValidity" SG_ 758 SBCM_DRV_AlvCnt2Val 3;
BA_ "RoutingFactor" SG_ 758 SBCM_DRV_AlvCnt2Val 0;
BA_ "Version" SG_ 758 SBCM_DRV_AlvCnt2Val "20.12.04";
BA_ "GenSigSendType" SG_ 758 SBCM_PsvDrLkReq 4;
BA_ "UserSigValidity" SG_ 758 SBCM_PsvDrLkReq 0;
BA_ "NetworkRequest" SG_ 758 SBCM_PsvDrLkReq 0;
BA_ "RoutingFactor" SG_ 758 SBCM_PsvDrLkReq 0;
BA_ "Version" SG_ 758 SBCM_PsvDrLkReq "21.01.03";
BA_ "GenSigSendType" SG_ 758 USM_DrvGhostDoorSta 4;
BA_ "UserSigValidity" SG_ 758 USM_DrvGhostDoorSta 0;
BA_ "NetworkRequest" SG_ 758 USM_DrvGhostDoorSta 0;
BA_ "NetworkRequestHoldingTime" SG_ 758 USM_DrvGhostDoorSta 5000;
BA_ "RoutingFactor" SG_ 758 USM_DrvGhostDoorSta 0;
BA_ "Version" SG_ 758 USM_DrvGhostDoorSta "21.03.11";
BA_ "GenSigSendType" SG_ 758 Mirror_LH_FoldingSta 4;
BA_ "UserSigValidity" SG_ 758 Mirror_LH_FoldingSta 0;
BA_ "NetworkRequest" SG_ 758 Mirror_LH_FoldingSta 0;
BA_ "NetworkRequestHoldingTime" SG_ 758 Mirror_LH_FoldingSta 5000;
BA_ "RoutingFactor" SG_ 758 Mirror_LH_FoldingSta 0;
BA_ "Version" SG_ 758 Mirror_LH_FoldingSta "20.12.04";
BA_ "GenSigSendType" SG_ 758 Mirror_LH_UnfoldingSta 4;
BA_ "UserSigValidity" SG_ 758 Mirror_LH_UnfoldingSta 0;
BA_ "NetworkRequest" SG_ 758 Mirror_LH_UnfoldingSta 0;
BA_ "NetworkRequestHoldingTime" SG_ 758 Mirror_LH_UnfoldingSta 5000;
BA_ "RoutingFactor" SG_ 758 Mirror_LH_UnfoldingSta 0;
BA_ "Version" SG_ 758 Mirror_LH_UnfoldingSta "20.12.04";
BA_ "GenSigSendType" SG_ 758 DRV_CrashMRActAlarm 4;
BA_ "UserSigValidity" SG_ 758 DRV_CrashMRActAlarm 0;
BA_ "NetworkRequest" SG_ 758 DRV_CrashMRActAlarm 0;
BA_ "NetworkRequestHoldingTime" SG_ 758 DRV_CrashMRActAlarm 5000;
BA_ "RoutingFactor" SG_ 758 DRV_CrashMRActAlarm 0;
BA_ "Version" SG_ 758 DRV_CrashMRActAlarm "20.12.04";
BA_ "GenSigSendType" SG_ 758 MirrorFldReq 4;
BA_ "UserSigValidity" SG_ 758 MirrorFldReq 0;
BA_ "NetworkRequest" SG_ 758 MirrorFldReq 0;
BA_ "NetworkRequestHoldingTime" SG_ 758 MirrorFldReq 5;
BA_ "RoutingFactor" SG_ 758 MirrorFldReq 0;
BA_ "Version" SG_ 758 MirrorFldReq "20.12.04";
BA_ "GenSigSendType" SG_ 758 OMU_TypeOption_DRV 4;
BA_ "UserSigValidity" SG_ 758 OMU_TypeOption_DRV 0;
BA_ "NetworkRequest" SG_ 758 OMU_TypeOption_DRV 0;
BA_ "NetworkRequestHoldingTime" SG_ 758 OMU_TypeOption_DRV 5000;
BA_ "RoutingFactor" SG_ 758 OMU_TypeOption_DRV 0;
BA_ "Version" SG_ 758 OMU_TypeOption_DRV "20.12.04";
BA_ "GenSigSendType" SG_ 758 IMS_OSMirPlayBackSta_LH 4;
BA_ "UserSigValidity" SG_ 758 IMS_OSMirPlayBackSta_LH 0;
BA_REL_ "GenSigTimeoutTime" BU_SG_REL_ DPSU SG_ 758 IMS_OSMirPlayBackSta_LH 1500;
BA_ "NetworkRequest" SG_ 758 IMS_OSMirPlayBackSta_LH 0;
BA_ "NetworkRequestHoldingTime" SG_ 758 IMS_OSMirPlayBackSta_LH 5;
BA_ "RoutingFactor" SG_ 758 IMS_OSMirPlayBackSta_LH 0;
BA_ "Version" SG_ 758 IMS_OSMirPlayBackSta_LH "20.12.04";
BA_ "Description" SG_ 758 ECMMRR_PLUS "This signal for passenger outside mirror OEC function(or ECM)

SBCM_DRV receive the ECM voltage value via H/wiring and then send this signal to SBCM_AST";
BA_ "GenSigSendType" SG_ 758 ECMMRR_PLUS 4;
BA_ "UserSigValidity" SG_ 758 ECMMRR_PLUS 0;
BA_ "NetworkRequest" SG_ 758 ECMMRR_PLUS 0;
BA_ "NetworkRequestHoldingTime" SG_ 758 ECMMRR_PLUS 5000;
BA_ "RoutingFactor" SG_ 758 ECMMRR_PLUS 0;
BA_ "Version" SG_ 758 ECMMRR_PLUS "20.12.04";
BA_ "Description" SG_ 758 Mirror_LHVerPosVal "This signal indicates LH Outside Mirror Vertical Position Sensor Voltage";
BA_ "GenSigSendType" SG_ 758 Mirror_LHVerPosVal 4;
BA_ "UserSigValidity" SG_ 758 Mirror_LHVerPosVal 0;
BA_ "NetworkRequest" SG_ 758 Mirror_LHVerPosVal 0;
BA_ "NetworkRequestHoldingTime" SG_ 758 Mirror_LHVerPosVal 5000;
BA_ "RoutingFactor" SG_ 758 Mirror_LHVerPosVal 0;
BA_ "Version" SG_ 758 Mirror_LHVerPosVal "20.12.04";
BA_ "Description" SG_ 758 Mirror_LHHorPosVal "This signal indicates LH Outside Mirror Horizontal Position Sensor Voltage";
BA_ "GenSigSendType" SG_ 758 Mirror_LHHorPosVal 4;
BA_ "UserSigValidity" SG_ 758 Mirror_LHHorPosVal 0;
BA_ "NetworkRequest" SG_ 758 Mirror_LHHorPosVal 0;
BA_ "NetworkRequestHoldingTime" SG_ 758 Mirror_LHHorPosVal 5000;
BA_ "RoutingFactor" SG_ 758 Mirror_LHHorPosVal 0;
BA_ "Version" SG_ 758 Mirror_LHHorPosVal "20.12.04";
BA_ "GenSigSendType" SG_ 758 SBCM_DRV_DiagSta 4;
BA_ "UserSigValidity" SG_ 758 SBCM_DRV_DiagSta 0;
BA_ "NetworkRequest" SG_ 758 SBCM_DRV_DiagSta 0;
BA_ "NetworkRequestHoldingTime" SG_ 758 SBCM_DRV_DiagSta 5000;
BA_ "RoutingFactor" SG_ 758 SBCM_DRV_DiagSta 0;
BA_ "Version" SG_ 758 SBCM_DRV_DiagSta "20.12.04";
BA_ "GenMsgSendType" BO_ 763 0;
BA_ "Description" SG_ 763 SBCM_DRV_Crc3Val "The data area for CRC calculation is based on the data length (DLC) of the message DB.

The CRC shall be calculated over the entire data block (excluding the CRC bytes) including the user data, alive counter and Data ID 

 

- CRC Polynomial (0x1D) , Initial Value : 0x00, XOR value : 0xFF, Data ID Mode : Both, Data ID : Message ID + 0xF800 

- The initial value is for CRC calculation and the message should be sent with the calculated result value. 

The mathematical expression to 8 bit CRC polynomial is given here. G(x) = x8 + x4 + x3 + x2 + 1";
BA_ "GenSigSendType" SG_ 763 SBCM_DRV_Crc3Val 4;
BA_ "GenSigStartValue" SG_ 763 SBCM_DRV_Crc3Val 255;
BA_ "UserSigValidity" SG_ 763 SBCM_DRV_Crc3Val 3;
BA_ "Version" SG_ 763 SBCM_DRV_Crc3Val "20.12.04";
BA_ "Description" SG_ 763 CDM_TypeOption "0x1 : On (CDM is applied)";
BA_ "GenSigSendType" SG_ 763 CDM_TypeOption 4;
BA_ "UserSigValidity" SG_ 763 CDM_TypeOption 7;
BA_ "NetworkRequest" SG_ 763 CDM_TypeOption 0;
BA_ "NetworkRequestHoldingTime" SG_ 763 CDM_TypeOption 5000;
BA_ "Version" SG_ 763 CDM_TypeOption "20.12.04";
BA_ "Description" SG_ 763 SBCM_DRV_AlvCnt3Val "For the first transmission request for a data element the counter shall be initialized with 0 and shall be incremented by 1

for every subsequent send request. When the counter reaches the maximum value(0xE), then it shall restart with 0 for the next send request";
BA_ "GenSigSendType" SG_ 763 SBCM_DRV_AlvCnt3Val 4;
BA_ "UserSigValidity" SG_ 763 SBCM_DRV_AlvCnt3Val 3;
BA_ "Version" SG_ 763 SBCM_DRV_AlvCnt3Val "20.12.04";
BA_ "Description" SG_ 763 CDM_ImmeChgSw_SBCM "State of Immediate Charging Switch";
BA_ "GenSigSendType" SG_ 763 CDM_ImmeChgSw_SBCM 4;
BA_ "UserSigValidity" SG_ 763 CDM_ImmeChgSw_SBCM 7;
BA_ "Version" SG_ 763 CDM_ImmeChgSw_SBCM "20.12.04";
BA_ "Description" SG_ 763 CDM_ChgDrSwFrt_SBCM "State of Front Charging Door Open Switch";
BA_ "GenSigSendType" SG_ 763 CDM_ChgDrSwFrt_SBCM 4;
BA_ "UserSigValidity" SG_ 763 CDM_ChgDrSwFrt_SBCM 7;
BA_ "Version" SG_ 763 CDM_ChgDrSwFrt_SBCM "20.12.04";
BA_ "Description" SG_ 763 CDM_OpnClsState_SBCM "This signal indicates CDM Open/Close Status";
BA_ "GenSigSendType" SG_ 763 CDM_OpnClsState_SBCM 4;
BA_ "UserSigValidity" SG_ 763 CDM_OpnClsState_SBCM 7;
BA_ "Version" SG_ 763 CDM_OpnClsState_SBCM "20.12.04";
BA_ "Description" SG_ 763 CDM_WarnMsg_SBCM "Command for CDM Warning on cluster";
BA_ "GenSigSendType" SG_ 763 CDM_WarnMsg_SBCM 4;
BA_ "UserSigValidity" SG_ 763 CDM_WarnMsg_SBCM 7;
BA_ "Version" SG_ 763 CDM_WarnMsg_SBCM "20.12.04";
BA_ "Description" SG_ 763 CDM_CmdStatus_SBCM "User Condition Check For CDM Operation";
BA_ "GenSigSendType" SG_ 763 CDM_CmdStatus_SBCM 4;
BA_ "GenSigStartValue" SG_ 763 CDM_CmdStatus_SBCM 15;
BA_ "UserSigValidity" SG_ 763 CDM_CmdStatus_SBCM 7;
BA_ "Version" SG_ 763 CDM_CmdStatus_SBCM "20.12.04";
BA_ "GenSigSendType" SG_ 763 Warn_HoodSwSta_SBCM 4;
BA_ "UserSigValidity" SG_ 763 Warn_HoodSwSta_SBCM 0;
BA_REL_ "GenSigTimeoutTime" BU_SG_REL_ BLTN_CAM SG_ 763 Warn_HoodSwSta_SBCM 1500;
BA_ "NetworkRequest" SG_ 763 Warn_HoodSwSta_SBCM 0;
BA_ "NetworkRequestHoldingTime" SG_ 763 Warn_HoodSwSta_SBCM 5000;
BA_ "Version" SG_ 763 Warn_HoodSwSta_SBCM "21.09.08";
BA_ "Description" SG_ 763 Hood_TypeOption "If the E-Hood is applied, the signal will be send.";
BA_ "GenSigSendType" SG_ 763 Hood_TypeOption 4;
BA_ "UserSigValidity" SG_ 763 Hood_TypeOption 0;
BA_REL_ "GenSigTimeoutTime" BU_SG_REL_ BLTN_CAM SG_ 763 Hood_TypeOption 1500;
BA_ "NetworkRequest" SG_ 763 Hood_TypeOption 0;
BA_ "NetworkRequestHoldingTime" SG_ 763 Hood_TypeOption 5000;
BA_ "Version" SG_ 763 Hood_TypeOption "21.09.08";
BA_ "GenSigSendType" SG_ 763 CDM_InsideOpnSwSta 4;
BA_ "UserSigValidity" SG_ 763 CDM_InsideOpnSwSta 7;
BA_ "NetworkRequest" SG_ 763 CDM_InsideOpnSwSta 0;
BA_ "NetworkRequestHoldingTime" SG_ 763 CDM_InsideOpnSwSta 5000;
BA_ "Version" SG_ 763 CDM_InsideOpnSwSta "20.12.04";
BA_ "GenMsgSendType" BO_ 742 0;
BA_ "Description" SG_ 742 SGU_OptTyp "This signal indicates if smart glass is installed and whta kind of smart glass is.

bit0 : Smart Glass Installation

bit1 : Smart Roof Glass

bit2 : Rear Smart Door Glass

bit3~bit7 : Reserved";
BA_ "GenSigSendType" SG_ 742 SGU_OptTyp 4;
BA_ "UserSigValidity" SG_ 742 SGU_OptTyp 0;
BA_ "RoutingFactor" SG_ 742 SGU_OptTyp 0;
BA_ "Version" SG_ 742 SGU_OptTyp "21.06.12";
BA_ "Description" SG_ 742 SGU_FltSta "SGU Fault Status";
BA_ "GenSigSendType" SG_ 742 SGU_FltSta 4;
BA_ "UserSigValidity" SG_ 742 SGU_FltSta 0;
BA_ "RoutingFactor" SG_ 742 SGU_FltSta 0;
BA_ "Version" SG_ 742 SGU_FltSta "21.07.04";
BA_ "Description" SG_ 742 SGU_BlindOnOffSet "Roll Blind Open/Close Control Set Value";
BA_ "GenSigSendType" SG_ 742 SGU_BlindOnOffSet 4;
BA_ "UserSigValidity" SG_ 742 SGU_BlindOnOffSet 0;
BA_REL_ "GenSigTimeoutTime" BU_SG_REL_ CGW_CCU SG_ 742 SGU_BlindOnOffSet 1500;
BA_ "RoutingFactor" SG_ 742 SGU_BlindOnOffSet 0;
BA_ "Version" SG_ 742 SGU_BlindOnOffSet "21.07.05";
BA_ "Description" SG_ 742 SGU_FltVal "SGU Fault Value";
BA_ "GenSigSendType" SG_ 742 SGU_FltVal 4;
BA_ "UserSigValidity" SG_ 742 SGU_FltVal 0;
BA_ "RoutingFactor" SG_ 742 SGU_FltVal 0;
BA_ "Version" SG_ 742 SGU_FltVal "21.07.04";
BA_ "Description" SG_ 742 SGU_Roof_OprLv "Roof Smart Glass Operation Level";
BA_ "GenSigSendType" SG_ 742 SGU_Roof_OprLv 4;
BA_ "UserSigValidity" SG_ 742 SGU_Roof_OprLv 0;
BA_REL_ "GenSigTimeoutTime" BU_SG_REL_ CGW_CCU SG_ 742 SGU_Roof_OprLv 1500;
BA_ "RoutingFactor" SG_ 742 SGU_Roof_OprLv 0;
BA_ "Version" SG_ 742 SGU_Roof_OprLv "21.07.04";
BA_ "Description" SG_ 742 SGU_2ndLeftDoor_OprLv "2nd Row Left Door Smart Glass Operation Level";
BA_ "GenSigSendType" SG_ 742 SGU_2ndLeftDoor_OprLv 4;
BA_ "UserSigValidity" SG_ 742 SGU_2ndLeftDoor_OprLv 0;
BA_REL_ "GenSigTimeoutTime" BU_SG_REL_ CGW_CCU SG_ 742 SGU_2ndLeftDoor_OprLv 1500;
BA_ "RoutingFactor" SG_ 742 SGU_2ndLeftDoor_OprLv 0;
BA_ "Version" SG_ 742 SGU_2ndLeftDoor_OprLv "21.07.04";
BA_ "Description" SG_ 742 SGU_2ndRightDoor_OprLv "2nd Row Right Door Smart Glass Operation Level";
BA_ "GenSigSendType" SG_ 742 SGU_2ndRightDoor_OprLv 4;
BA_ "UserSigValidity" SG_ 742 SGU_2ndRightDoor_OprLv 0;
BA_REL_ "GenSigTimeoutTime" BU_SG_REL_ CGW_CCU SG_ 742 SGU_2ndRightDoor_OprLv 1500;
BA_ "RoutingFactor" SG_ 742 SGU_2ndRightDoor_OprLv 0;
BA_ "Version" SG_ 742 SGU_2ndRightDoor_OprLv "21.07.04";
BA_ "Description" SG_ 742 SGU_3rdLeftDoor_OprLv "3rd Row Left Door Smart Glass Operation Level";
BA_ "GenSigSendType" SG_ 742 SGU_3rdLeftDoor_OprLv 4;
BA_ "UserSigValidity" SG_ 742 SGU_3rdLeftDoor_OprLv 0;
BA_REL_ "GenSigTimeoutTime" BU_SG_REL_ CGW_CCU SG_ 742 SGU_3rdLeftDoor_OprLv 1500;
BA_ "RoutingFactor" SG_ 742 SGU_3rdLeftDoor_OprLv 0;
BA_ "Version" SG_ 742 SGU_3rdLeftDoor_OprLv "21.07.04";
BA_ "Description" SG_ 742 SGU_3rdRightDoor_OprLv "3rd Row Right Door Smart Glass Operation Level";
BA_ "GenSigSendType" SG_ 742 SGU_3rdRightDoor_OprLv 4;
BA_ "UserSigValidity" SG_ 742 SGU_3rdRightDoor_OprLv 0;
BA_REL_ "GenSigTimeoutTime" BU_SG_REL_ CGW_CCU SG_ 742 SGU_3rdRightDoor_OprLv 1500;
BA_ "RoutingFactor" SG_ 742 SGU_3rdRightDoor_OprLv 0;
BA_ "Version" SG_ 742 SGU_3rdRightDoor_OprLv "21.07.04";
BA_ "Description" SG_ 742 SGU_RearWindow_OprLv "Rear Window Smart Glass Operation Level";
BA_ "GenSigSendType" SG_ 742 SGU_RearWindow_OprLv 4;
BA_ "UserSigValidity" SG_ 742 SGU_RearWindow_OprLv 0;
BA_REL_ "GenSigTimeoutTime" BU_SG_REL_ CGW_CCU SG_ 742 SGU_RearWindow_OprLv 1500;
BA_ "RoutingFactor" SG_ 742 SGU_RearWindow_OprLv 0;
BA_ "Version" SG_ 742 SGU_RearWindow_OprLv "21.07.04";
BA_ "Description" SG_ 742 SGU_OprLvSet "Smart Glass Operation Level Set";
BA_ "GenSigSendType" SG_ 742 SGU_OprLvSet 4;
BA_ "UserSigValidity" SG_ 742 SGU_OprLvSet 0;
BA_REL_ "GenSigTimeoutTime" BU_SG_REL_ CGW_CCU SG_ 742 SGU_OprLvSet 1500;
BA_ "RoutingFactor" SG_ 742 SGU_OprLvSet 0;
BA_ "Version" SG_ 742 SGU_OprLvSet "21.07.05";
BA_ "Description" SG_ 742 SGU_RdySta "SGU Ready Status";
BA_ "GenSigSendType" SG_ 742 SGU_RdySta 4;
BA_ "UserSigValidity" SG_ 742 SGU_RdySta 0;
BA_ "RoutingFactor" SG_ 742 SGU_RdySta 0;
BA_ "Version" SG_ 742 SGU_RdySta "21.07.04";
VAL_ 223 ALBCU_SmartCtrl_1h 0 "Default" 1 "Group1" 2 "Group2" 3 "Group3" 4 "Group4" 5 "Group5" 6 "Group6" 7 "Group7" 8 "Group8" 9 "Group9" 10 "General Group" 11 "Unused" 12 "Unused" 13 "Unused" 14 "Unused" 15 "Invalid" ;
VAL_ 223 ALBCU_SmartCtrl_2h 0 "Default" 1 "Group1" 2 "Group2" 3 "Group3" 4 "Group4" 5 "Group5" 6 "Group6" 7 "Group7" 8 "Group8" 9 "Group9" 10 "General Group" 11 "Unused" 12 "Unused" 13 "Unused" 14 "Unused" 15 "Invalid" ;
VAL_ 223 ALBCU_SmartCtrl_Status 0 "Default" 1 "Start" 2 "Finished" 3 "Stop" 4 "Unused" 5 "Unused" 6 "Unused" 7 "Invalid" ;
VAL_ 1180 SHVU_Ast_Beep1Sound 0 "Beep1 mode Off" 1 "Beep1 mode On" 2 "Unused" 3 "Invalid" ;
VAL_ 1180 Ast_SHVU_SeatEcoSta 0 "Off(Initial Value)" 1 "On" 2 "Not Used" 3 "Error Indicator" ;
VAL_ 255 BckGls_RrGlsHtdOnCmd 0 "Off" 1 "On" 2 "Not Used" 3 "Error Indicator" ;
VAL_ 255 Wndshld_FrtGlsHtdOnCmd 0 "Off" 1 "On" 2 "Not Used" 3 "Error Indicator" ;
VAL_ 255 Mirror_MirFldOpt 0 "Not Applied" 1 "Applied" 2 "Not Used" 3 "Error Indicator" ;
VAL_ 255 Window_AsstPwrWdwSunroofEnblSta 0 "Disable" 1 "Enable" 2 "Not Used" 3 "Error Indicator" ;
VAL_ 255 Window_RrPwrWdwEnblSta 0 "Off" 1 "On" 2 "Not Used" 3 "Error Indicator" ;
VAL_ 255 Window_RrPwrWdwLkInd 0 "Off" 1 "On" 2 "Not Used" 3 "Error Indicator" ;
VAL_ 255 Window_DrvPwrWdwCmd 0 "NoAction" 1 "ManualUp" 2 "ManualDown" 3 "Error Indicator" ;
VAL_ 255 Window_AsstPwrWdwCmd 0 "NoAction" 1 "ManualUp" 2 "ManualDown" 3 "Error Indicator" ;
VAL_ 255 Window_RrLftPwrWdwCmd 0 "NoAction" 1 "ManualUp" 2 "ManualDown" 3 "Error Indicator" ;
VAL_ 255 Window_RrRtPwrWdwCmd 0 "NoAction" 1 "ManualUp" 2 "ManualDown" 3 "Error Indicator" ;
VAL_ 255 Mirror_FldUnfldCmd 0 "Off" 1 "Fold" 2 "Unfold" 3 "Error Indicator" ;
VAL_ 255 Mirror_FldCtrlSta 0 "Off" 1 "Fldng" 2 "Fld" 3 "Error Indicator" ;
VAL_ 255 Mirror_UnFldCtrlSta 0 "Off" 1 "UnFldng" 2 "UnFld" 3 "Error Indicator" ;
VAL_ 255 Mirror_PosMnlCmd 0 "Off" 1 "Up" 2 "Down" 3 "Left" 4 "Right" 5 "Not Used" 6 "Not Used" 7 "Error Indicator" ;
VAL_ 255 Mirror_SelSwIndCmd 0 "Off" 1 "Left" 2 "Neutral" 3 "Right" 4 "Not Used" 5 "Not Used" 6 "Not Used" 7 "Error Indicator" ;
VAL_ 255 BCM_SafetyWdwOptTyp2 0 "None" 1 "Driver Safety Window" 2 "Front Safety Window" 3 "All Safety Window" 4 "Not Used" 5 "Not Used" 6 "Not Used" 7 "Error Indicator" ;
VAL_ 255 Mirror_LHOSMirPlyBckSta 0 "Stop" 1 "Play 1" 2 "Play 2" 3 "Play 3" 4 "Smart IMS" 5 "Profile 1" 6 "Profile 2" 7 "Guest" 8 "Not Used" 9 "Not Used" 10 "Not Used" 11 "Not Used" 12 "Not Used" 13 "Not Used" 14 "Not Used" 15 "Error Indicator" ;
VAL_ 255 Mirror_RHOSMirPlyBckSta 0 "Stop" 1 "Play 1" 2 "Play 2" 3 "Play 3" 4 "Smart IMS" 5 "Profile 1" 6 "Profile 2" 7 "Guest" 8 "Not Used" 9 "Not Used" 10 "Not Used" 11 "Not Used" 12 "Not Used" 13 "Not Used" 14 "Not Used" 15 "Error Indicator" ;
VAL_ 255 Mirror_SelSwSta 0 "Off" 1 "Left" 2 "Neutral" 3 "Right" 4 "Not Used" 5 "Not Used" 6 "Not Used" 7 "Error Indicator" ;
VAL_ 255 BckGls_RrGlsHtdOpt 0 "Not Applied" 1 "Applied" 2 "Not Used" 3 "Error Indicator" ;
VAL_ 2344811009 BMS_Crc2Val 65535 "Signal Invalid (Message with unused CRC. CRC signal is transmitted fixed value)" ;
VAL_ 2344811009 BMS_AlvCnt2Val 255 "Signal Invalid (Message with unused Alive counter. Alive counter signal is transmitted fixed value)" ;
VAL_ 2344811009 xEV_SrvLmpReq 0 "Off" 1 "Service Lamp On" 2 "Not used" 3 "Error indicator" ;
VAL_ 2344811009 xEV_MainRlyOnSta 0 "Open" 1 "Close" 2 "Not used" 3 "Error indicator" ;
VAL_ 2344811009 xEV_SysFltSta 0 "Normal" 1 "Fault" 2 "Not used" 3 "Error indicator" ;
VAL_ 2344811009 xEV_InltTempVal 127 "Error value" ;
VAL_ 2344811009 xEV_MinBattCelVoltVal 255 "Error indicator" ;
VAL_ 2344811009 xEV_MaxBattCelVoltVal 255 "Error indicator" ;
VAL_ 2344811010 xEV_BattCurrVal 32767 "Error indicator" ;
VAL_ 2344811010 xEV_MinBattTempVal 127 "Error indicator" ;
VAL_ 2344811010 xEV_MaxBattTempVal 127 "Error indicator" ;
VAL_ 2344811010 xEV_FanSpdStpSta 0 "None" 1 "1step" 2 "2step" 3 "3step" 4 "4step" 5 "5step" 6 "6step" 7 "7step" 8 "8step" 9 "9step" ;
VAL_ 2344811010 xEV_12VRlyOffAlrmReq 0 "Normal" 1 "Pop up Request" 2 "Not used" 3 "Error indicator" ;
VAL_ 2344811010 xEV_12VRlyOnAlrmReq 0 "Normal" 1 "Pop up Request" 2 "Not used" 3 "Error indicator" ;
VAL_ 2344811010 xEV_SocDis 255 "Error value" ;
VAL_ 2344811011 xEV_12VAlarmReqForICU 0 "Normal" 1 "3rd cut off" 2 "Warn. msg & 3rd cut off req" 3 "reserved" ;
VAL_ 2344811011 xEV_AuxBattChrgReq 0 "Normal" 1 "Charge Request" 2 "Not used" 3 "Error Indicator" ;
VAL_ 2344811011 xEV_12VDarkCurrAlarmForICU 0 "Normal" 1 "Alarm Flag set" 2 "Not used" 3 "Error indicator" ;
VAL_ 2344811011 xEV_12VBatVLmt 255 "Error indicator" ;
VAL_ 2344811011 xEV_CharBatInfoReqForSDC 0 "Default(no request)" 1 "High volt bat. First" 2 "12 volt bat. First" 3 "Both of them possible" ;
VAL_ 2344811011 xEV_ClimateOffReq 0 "Default" 1 "Flag set" 2 "Not used" 3 "Error indicator" ;
VAL_ 2344811011 xEV_MainRlyOnRetrySta 0 "Normal" 1 "Relay ON Retry Operation" 2 "Not used" 3 "Error indicator" ;
VAL_ 2344811011 xEV_Bms_BlackBox_Data_req 0 "Default" 1 "Data Save Req (Isolation)" 2 "Data Set Clear" 3 "Error Indicator" ;
VAL_ 2344811011 xEV_12V_BatDchCurrLmt 255 "Error indicator" ;
VAL_ 2344811011 xEV_12VChargeReq 0 "Not Request(Normal)" 1 "Request" 2 "Not used" 3 "Error indicator" ;
VAL_ 2344811011 xEV_BmsRomType 0 "No Definition" 1 "Normal Battery Pack with Heater System" 2 "Normal Battery Pack without Heater System" 3 "Economy Battery Pack with Heater System" 4 "Economy Battery Pack without Heater System" 5 "Extented Battery Pack with Heater System" 6 "Extented Battery Pack without Heater System" 7 "Performance Battery Pack (Heater or Non Heater)" ;
VAL_ 2344811011 xEV_12V_CurrFltDetectReq 0 "Normal" 1 "Request" 2 "Not used" 3 "Error indicator" ;
VAL_ 2344811011 xEV_PRATempSnsVal_ 127 "Error indicator" ;
VAL_ 2344811011 xEV_PRATempSns2Val_ 127 "Error indicator" ;
VAL_ 2344811011 xEV_12VRlyOnSwReq 0 "Normal" 1 "Request" 2 "Not used" 3 "Error indicator" ;
VAL_ 2344811012 xEV_Bms_IsolDetDeactFuncSta 0 "Function disabled state" 1 "Functional activated state" 2 "Not used" 3 "Error indicator" ;
VAL_ 2344811012 xEV_Bms_CellBalDeactFuncSta 0 "Function disabled state" 1 "Functional activated state" 2 "Not used" 3 "Error indicator" ;
VAL_ 2344811012 xEV_BMS_SOC_2nd 65535 "Error Value" ;
VAL_ 2382595073 DATC_FrDrvBlwDis 0 "OFF" 1 "Blank Display" 2 "1 Step" 3 "2 Step" 4 "3 Step" 5 "4 Step" 6 "5 Step" 7 "6 Step" 8 "7 Step" 9 "8 Step" 10 "BLOWER AUTO" 11 "Reserved" 12 "Reserved" 13 "Reserved" 14 "Reserved" 15 "Error Indicator" ;
VAL_ 2382595073 DATC_FrPsBlwDis 0 "OFF" 1 "Blank Display(Blower ´Ü¼ö ¹ÌÇ¥½Ã, ¿¹)Auto ½Ã)" 2 "1 Step" 3 "2 Step" 4 "3 Step" 5 "4 Step" 6 "5 Step" 7 "6 Step" 8 "7 Step" 9 "8 Step" 10 "BLOWER AUTO" 11 "Reserved" 12 "Reserved" 13 "Reserved" 14 "Reserved" 15 "Error Indicator" ;
VAL_ 2382595073 DATC_HeatDis 0 "Heat OFF" 1 "Heat ON" 2 "Not used" 3 "Error Indicator" ;
VAL_ 2382595073 DATC_EVScrnDis 0 "Deactivated" 1 "Activated" 2 "Not used" 3 "Error Indicator" ;
VAL_ 2382595073 DATC_DrvOnlyDis 0 "Initial (Dual Temp Display)" 1 "Driver Only Status (Only Display Driver Temp)" 2 "Not used" 3 "Error Indicator" ;
VAL_ 2382595073 DATC_FrDrvBlwAutoDis 0 "Default" 1 "Blank" 2 "AUTO" 3 "Error Indicator" ;
VAL_ 2382595073 DATC_DiagCodeDis 0 "Blank Display / 0x1~0xFE(PHY=(HEX*1.0-1.0))" 255 "Error Indicator" ;
VAL_ 2382595073 DATC_RrChgReqDis 0 "Not requested" 1 "User Input" 2 "Not used" 3 "Error Indicator" ;
VAL_ 2382595073 DATC_RrClmtScrnDis 0 "Deactived" 1 "Actived" 2 "Not used" 3 "Error Indicator" ;
VAL_ 2382595073 DATC_AUTOStep 0 "Default" 1 "OFF" 2 "1st & 2nd & 3rd On (3 Step Type)" 3 "1st & 2nd On (3 Step Type)" 4 "1st On (3 Step Type)" 5 "1st & 2nd On (2 Step Type)" 6 "1st On (2 Step Type)" 7 "Reserved" 8 "Reserved" 9 "Reserved" 10 "Reserved" 11 "Reserved" 12 "Reserved" 13 "Reserved" 14 "Reserved" 15 "Error Indicator" ;
VAL_ 2382595073 DATC_IntakeDis 0 "Default" 1 "REC (Fresh off)" 2 "FRE (REC off)" 3 "Error indicator" ;
VAL_ 2382595073 DATC_MultiAirModSta 0 "Default" 1 "OFF" 2 "ON" 3 "Error Indicator" ;
VAL_ 2365803009 DATC_SwVer1 0 "0x0x00~0x7E:ASCII value" 126 "0x0x00~0x7E:ASCII value" 127 "Invalid" ;
VAL_ 2365803009 DATC_SwVer2 0 "0x0x00~0x7E:ASCII value" 126 "0x0x00~0x7E:ASCII value" 127 "Invalid" ;
VAL_ 2365803009 DATC_SwVer3 0 "0x0x00~0x7E:ASCII value" 126 "0x0x00~0x7E:ASCII value" 127 "Invalid" ;
VAL_ 2365803009 DATC_Typ2 255 "ErrorIndicator" ;
VAL_ 2365803010 DATC_SwVer4 0 "0x0x00~0x7E:ASCII value" 126 "0x0x00~0x7E:ASCII value" 127 "Invalid" ;
VAL_ 2365803010 DATC_SwVer5 0 "0x0x00~0x7E:ASCII value" 126 "0x0x00~0x7E:ASCII value" 127 "Invalid" ;
VAL_ 1174 Drv_SHVU_SeatOptSta 0 "Init" 1 "Heater only 2step" 2 "Heater only 3step" 3 "Vent only 2step" 4 "Vent only 3step" 5 "Heater and Vent 2step" 6 "Heater and Vent 3step" 7 "Invalid" ;
VAL_ 1174 Drv_SHVU_HtSwHiIndSta 0 "Off(Initial Value)" 1 "On" 2 "RESERVED" 3 "Error Indicator" ;
VAL_ 1174 Drv_SHVU_HtSwMidIndSta 0 "Off(Initial Value)" 1 "On" 2 "RESERVED" 3 "Error Indicator" ;
VAL_ 1174 Drv_SHVU_HtSwLowIndSta 0 "Off(Initial Value)" 1 "On" 2 "RESERVED" 3 "Error Indicator" ;
VAL_ 1174 Drv_SHVU_VntSwHiIndSta 0 "Off(Initial Value)" 1 "On" 2 "RESERVED" 3 "Error Indicator" ;
VAL_ 1174 Drv_SHVU_VntSwMidIndSta 0 "Off(Initial Value)" 1 "On" 2 "RESERVED" 3 "Error Indicator" ;
VAL_ 1174 Drv_SHVU_VntSwLowIndSta 0 "Off(Initial Value)" 1 "On" 2 "RESERVED" 3 "Error Indicator" ;
VAL_ 1174 Drv_SHVU_HtBlcUSMSta 0 "Default" 1 "Normal" 2 "Back 1" 3 "Back 2" 4 "Back 3" 5 "Cush 1" 6 "Cush 2" 7 "Cush 3" 8 "Reserved" 9 "Reserved" 10 "Reserved" 11 "Reserved" 12 "Reserved" 13 "Reserved" 14 "Reserved" 15 "Invalid" ;
VAL_ 1174 Drv_SHVU_SeatHtOperSta 0 "Init" 1 "RESERVED" 2 "Heater & Vent OFF" 3 "Vent Low" 4 "Vent Mid" 5 "Vent High" 6 "Heater Low" 7 "Heater Mid" 8 "Heater High" 9 "RESERVED" 10 "RESERVED" 11 "RESERVED" 12 "RESERVED" 13 "RESERVED" 14 "RESERVED" 15 "Invalid" ;
VAL_ 1174 Drv_SHVU_HtSwHiIndSta_RHD 0 "Off(Initial Value)" 1 "On" 2 "RESERVED" 3 "Error Indicator" ;
VAL_ 1174 Drv_SHVU_HtSwMidIndSta_RHD 0 "Off(Initial Value)" 1 "On" 2 "RESERVED" 3 "Error Indicator" ;
VAL_ 1174 Drv_SHVU_HtSwLowIndSta_RHD 0 "Off(Initial Value)" 1 "On" 2 "RESERVED" 3 "Error Indicator" ;
VAL_ 1174 Drv_SHVU_VntSwHiIndSta_RHD 0 "Off(Initial Value)" 1 "On" 2 "RESERVED" 3 "Error Indicator" ;
VAL_ 1174 Drv_SHVU_VntSwMidIndSta_RHD 0 "Off(Initial Value)" 1 "On" 2 "RESERVED" 3 "Error Indicator" ;
VAL_ 1174 Drv_SHVU_VntSwLowIndSta_RHD 0 "Off(Initial Value)" 1 "On" 2 "RESERVED" 3 "Error Indicator" ;
VAL_ 1174 Drv_SHVU_HtBlcUSMSta_RHD 0 "Default" 1 "Normal" 2 "Back 1" 3 "Back 2" 4 "Back 3" 5 "Cush 1" 6 "Cush 2" 7 "Cush 3" 8 "Reserved" 9 "Reserved" 10 "Reserved" 11 "Reserved" 12 "Reserved" 13 "Reserved" 14 "Reserved" 15 "Invalid" ;
VAL_ 1179 Drv_SHVU_SeatEcoSta 0 "Off(Initial Value)" 1 "On" 2 "RESERVED" 3 "Error Indicator" ;
VAL_ 1179 SHVU_Drv_Beep1Sound 0 "Beep1 mode Off" 1 "Beep1 mode On" 2 "RESERVED" 3 "Invalid" ;
VAL_ 1179 SHVU_CtrlScreenDis 0 "Default" 1 "Screen Display On" 2 "RESERVED" 3 "Invalid" ;
VAL_ 1189 C_RLTiltUpSw_HU 0 "Default" 1 "Off" 2 "On" 3 "Invalid" ;
VAL_ 1189 C_RRTiltDownSw_HU 0 "Default" 1 "Off" 2 "On" 3 "Invalid" ;
VAL_ 1189 C_RRTiltUpSw_HU 0 "Default" 1 "Off" 2 "On" 3 "Invalid" ;
VAL_ 1189 C_RLRclBwdSw_HU 0 "Default" 1 "Off" 2 "On" 3 "Invalid" ;
VAL_ 1189 C_RLRclFwdSw_HU 0 "Default" 1 "Off" 2 "On" 3 "Invalid" ;
VAL_ 1189 C_RLFldSw_HU 0 "Default" 1 "Off" 2 "On" 3 "Invalid" ;
VAL_ 1189 C_RRRclBwdSw_HU 0 "Default" 1 "Off" 2 "On" 3 "Invalid" ;
VAL_ 1189 C_RRRclFwdSw_HU 0 "Default" 1 "Off" 2 "On" 3 "Invalid" ;
VAL_ 1189 C_TLHrestFldSw_HU 0 "Default" 1 "Off" 2 "On" 3 "Invalid" ;
VAL_ 1189 C_TRHrestFldSw_HU 0 "default" 1 "OFF" 2 "ON" 3 "Invalid" ;
VAL_ 1189 C_RLRlxSW_HU 0 "Default" 1 "Off" 2 "On" 3 "Invalid" ;
VAL_ 1189 C_RRRlxSW_HU 0 "Default" 1 "Off" 2 "On" 3 "Invalid" ;
VAL_ 1189 C_TLFldSw_HU 0 "Default" 1 "Off" 2 "On" 3 "Invalid" ;
VAL_ 1189 C_TRFldSw_HU 0 "Default" 1 "Off" 2 "On" 3 "Invalid" ;
VAL_ 1189 C_RRFldSw_HU 0 "Default" 1 "Off" 2 "On" 3 "Invalid" ;
VAL_ 1189 C_RLTiltDownSw_HU 0 "Default" 1 "Off" 2 "On" 3 "Invalid" ;
VAL_ 1185 C_AstWindowCmdAVN 0 "No action" 1 "Manual Down" 2 "Manual Up" 3 "25% Open" 4 "50%Open" 5 "Auto Down" 6 "Auto Up" 7 "15% Open" 8 "Unused" 9 "Unused" 10 "Unused" 11 "Unused" 12 "Unused" 13 "Unused" 14 "Unused" 15 "Invalid" ;
VAL_ 1185 C_RrDefoggerCmdAVN 0 "Off" 1 "On" 2 "Reserved" 3 "Invalid" ;
VAL_ 1185 C_RRWindowCmdAVN 0 "No action" 1 "Manual Down" 2 "Manual Up" 3 "25% Open" 4 "50% Open" 5 "Auto Down" 6 "Auto Up" 7 "15% Open" 8 "Unused" 9 "Unused" 10 "Unused" 11 "Unused" 12 "Unused" 13 "Unused" 14 "Unused" 15 "Invalid" ;
VAL_ 1185 C_RLWindowCmdAVN 0 "No action" 1 "Manual Down" 2 "Manual Up" 3 "25% Open" 4 "50% Open" 5 "Auto Down" 6 "Auto UP" 7 "15% Open" 8 "Unused" 9 "Unused" 10 "Unused" 11 "Unused" 12 "Unused" 13 "Unused" 14 "Unused" 15 "Invalid" ;
VAL_ 1185 C_BlindCmdAVN 0 "No Action" 1 "R_Blind Auto Open" 2 "R_Blind Auto Close" 3 "Stop" 4 "reserved" 5 "reserved" 6 "reserved" 7 "Invalid" ;
VAL_ 1185 C_GlassCmdAVN 0 "No Action" 1 "Glass Auto Open" 2 "Glass Auto Close" 3 "Glass Auto Tilt Up" 4 "Stop" 5 "reserved" 6 "reserved" 7 "Invalid" ;
VAL_ 1185 C_DrvWindowCmdAVN 0 "No action" 1 "Manual Down" 2 "Manual Up" 3 "25% Open" 4 "50% Open" 5 "Auto Down" 6 "Auto Up" 7 "15% Open" 8 "Unused" 9 "Unused" 10 "Unused" 11 "Unused" 12 "Unused" 13 "Unused" 14 "Unused" 15 "Invalid" ;
VAL_ 1185 C_PTGCNTLCmdAVN 0 "Close" 1 "Open" 2 "Reserved" 3 "Invalid" ;
VAL_ 1186 C_PTGMStopRlyIBOX 0 "None" 1 "Lock" 2 "Unlock" 3 "Panic" 4 "Panic stop" 5 "Trunk (or Tail Gate)" 6 "Two step unlock warning" 7 "Invalid" ;
VAL_ 1186 C_PTGMCmdRlyIBOX 0 "Default" 1 "ON" 2 "OFF" 3 "Invalid" ;
VAL_ 1186 C_RemoteWdwCMDHU 0 "None" 1 "Auto Up" 2 "Auto Down" 3 "invalid" ;
VAL_ 1186 C_EsyAcsProfileID_HU 0 "Default" 1 "Profile 1" 2 "Profile 2" 3 "Invalid" ;
VAL_ 1186 C_TeleDefoggerHeatingCmdIBOX 0 "Off (default)" 1 "On(Remote Heating On)" 2 "Reserved" 3 "Invalid" ;
VAL_ 1186 C_TeleFrontHeatingCmdIBOX 0 "Off (Default)" 1 "On (Remote Heating On)" 2 "Reserved" 3 "Invalid" ;
VAL_ 1186 HU_CDMOpenCmd 0 "Default" 1 "CDM Open" 2 "CDM Close" 3 "Invalid" ;
VAL_ 1186 C_PreCrankReq 0 "Default" 1 "Req On" 2 "Not Support" 3 "Invalid" ;
VAL_ 1186 C_TeleAstSeatOpCmdIBOX 0 "Init" 1 "Unused" 2 "Seat Heat&Vent OFF" 3 "Seat_Vent_Low" 4 "Seat_Vent_Mid" 5 "Seat_Vent_High" 6 "Seat_Heat_Low" 7 "Seat_Heat_Mid" 8 "Seat_Heat_High" 9 "Unused" 10 "Unused" 11 "Unused" 12 "Unused" 13 "Unused" 14 "Unused" 15 "Invalid" ;
VAL_ 1186 C_TeleDrvSeatOpCmdIBOX 0 "Init" 1 "Unused" 2 "Seat Heat&Vent OFF" 3 "Seat_Vent_Low" 4 "Seat_Vent_Mid" 5 "Seat_Vent_High" 6 "Seat_Heat_Low" 7 "Seat_Heat_Mid" 8 "Seat_Heat_High" 9 "Unused" 10 "Unused" 11 "Unused" 12 "Unused" 13 "Unused" 14 "Unused" 15 "Invalid" ;
VAL_ 1186 C_TeleRRSeatOpCmdIBOX 0 "Init" 1 "Unused" 2 "Seat Heat&Vent OFF" 3 "Seat_Vent_Low" 4 "Seat_Vent_Mid" 5 "Seat_Vent_High" 6 "Seat_Heat_Low" 7 "Seat_Heat_Mid" 8 "Seat_Heat_High" 9 "Unused" 10 "Unused" 11 "Unused" 12 "Unused" 13 "Unused" 14 "Unused" 15 "Invalid" ;
VAL_ 1186 C_TeleRLSeatOpCmdIBOX 0 "Init" 1 "Unused" 2 "Seat Heat&Vent OFF" 3 "Seat_Vent_Low" 4 "Seat_Vent_Mid" 5 "Seat_Vent_High" 6 "Seat_Heat_Low" 7 "Seat_Heat_Mid" 8 "Seat_Heat_High" 9 "Unused" 10 "Unused" 11 "Unused" 12 "Unused" 13 "Unused" 14 "Unused" 15 "Invalid" ;
VAL_ 1186 C_HazardFromCCS 0 "Off" 1 "On (Remote Hazard On)" 2 "Reserved" 3 "Invalid" ;
VAL_ 1186 C_PanicFromCCS 0 "Off" 1 "On (Remote Horn and Hazard On)" 2 "Reserved" 3 "Invalid" ;
VAL_ 1186 C_CtrlDrUnlockRlyCCS 0 "0ff" 1 "On (Remote Unlock Command)" 2 "Reserved" 3 "Invalid" ;
VAL_ 1186 C_CtrlDrLockRlyCCS 0 "Off (default)" 1 "On (remote Lock Command)" 2 "Reserved" 3 "Invalid" ;
VAL_ 1186 C_DrvPSDCloseRlyIBOX 0 "OFF" 1 "ON" 2 "Panic stop" 3 "Invalid" ;
VAL_ 1186 C_DrvPSDOpenRlyIBOX 0 "OFF" 1 "ON" 2 "Panic stop" 3 "Invalid" ;
VAL_ 1186 C_AstPSDCloseRlyIBOX 0 "OFF" 1 "ON" 2 "Panic stop" 3 "Invalid" ;
VAL_ 1186 C_AstPSDOpenRlyIBOX 0 "OFF" 1 "ON" 2 "Panic stop" 3 "Invalid" ;
VAL_ 1193 C_PTGMNValueSet 0 "Default" 1 "Power Mode" 2 "Manual Mode" 3 "Invalid" ;
VAL_ 1193 CF_AVN_PSMNValueSet 0 "Default" 1 "Off(Disable)" 2 "50mm On(Enable)" 3 "75mm On(Enable)" 4 "Reserved" 5 "Reserved" 6 "Reserved" 7 "Invalid" ;
VAL_ 1193 C_HfreeTrunkTgNValueSet 0 "Default" 1 "HandsFree Off" 2 "HandsFree On" 3 "Reserved" 4 "Invalid" 5 "Reserved" 6 "Reserved" 7 "Reserved" ;
VAL_ 1193 CF_AVN_TrfChgSet 0 "Default" 1 "Disable(Off)" 2 "Enable(On)" 3 "Invalid" ;
VAL_ 1193 CF_AVN_SCMNValueSet 0 "Default" 1 "Steering Off" 2 "Steering On" 3 "Invalid" ;
VAL_ 1193 CF_AVN_ADrUNValueSet 0 "Default" 1 "Off" 2 "Key Out On(All Doors)" 3 "Shift Lever On(All Doors)" 4 "Override" 5 "Invalid" 6 "Key Out On(Driver Door)" 7 "Shift Lever On(Driver Door)" ;
VAL_ 1193 CF_AVN_OTTurnNValueSet 0 "Default" 1 "One Touch Turn Off" 2 "3 Flashing" 3 "5 Flashing" 4 "7 Flashing" 5 "Invalid" 6 "Reserved" 7 "Reserved" ;
VAL_ 1193 CF_Gway_WPCNValueSet 0 "Default" 1 "Off(Disable)" 2 "On(Enable)" 3 "Invalid" ;
VAL_ 1193 C_AVN_RearWiperNValueSet 0 "Default" 1 "Rear Wiper(Reverse) Off" 2 "Rear Wiper(Reverse) On" 3 "Invalid" ;
VAL_ 1193 C_UnlockWelocomeNValueSet 0 "Default" 1 "Off" 2 "On" 3 "Invalid" ;
VAL_ 1193 C_SmartWelocomeNValueSet 0 "Default" 1 "Off" 2 "On" 3 "Invalid" ;
VAL_ 1193 CF_AVN_PTGSpeedNValueSet 0 "Default" 1 "Fast" 2 "Slow" 3 "Invalid" ;
VAL_ 1193 CR_Datc_DRSeatWheel_USM_Set 0 "Default" 1 "Off" 2 "On" 3 "Invalid" ;
VAL_ 1193 CF_AVN_TTUnlockNValueSet 0 "Default" 1 "Off" 2 "On" 3 "Invalid" ;
VAL_ 1193 CF_Gway_RWPCNValueSet 0 "Default" 1 "Off" 2 "On" 3 "Invalid" ;
VAL_ 1193 C_PSDNValueSet 0 "Default" 1 "Power Mode" 2 "Manual Mode" 3 "Invalid" ;
VAL_ 1193 CF_Avn_HAPTICWARNINGNValueSet 0 "Default" 1 "Weak" 2 "Medium" 3 "Strong" 4 "Reserved" 5 "Reserved" 6 "Off" 7 "Invalid" ;
VAL_ 1193 CR_Datc_DRSeatHeat_USM_Set 0 "Default" 1 "Off" 2 "On" 3 "Invalid" ;
VAL_ 1193 C_WALNValueSet 0 "Default" 1 "Off" 2 "On" 3 "Invalid" ;
VAL_ 1193 C_ApprUnlockNValue 0 "Defualt" 1 "Approach Unlock OFF" 2 "Approach Unlock ON" 3 "Invalid" ;
VAL_ 1193 CF_AVN_SEW_NEWNValueSet 0 "Default" 1 "Off" 2 "On(Warning)" 3 "Invalid" ;
VAL_ 1193 CF_AVN_SEA_NEWNValueSet 0 "Default" 1 "Off" 2 "On(Assist)" 3 "Invalid" ;
VAL_ 1193 CF_AVN_EscortHLNValueSet 0 "Default" 1 "Escort Off" 2 "Escort On" 3 "Invalid" ;
VAL_ 1195 CF_AVN_CluWelcomeSnd 0 "Default" 1 "Off" 2 "On" 3 "Invalid" ;
VAL_ 1195 CF_AVN_CluTransmissionDisp 0 "Default" 1 "Off" 2 "On" 3 "Invalid" ;
VAL_ 1195 CF_AVN_CluWiperLight 0 "Default" 1 "Off" 2 "On" 3 "Invalid" ;
VAL_ 1195 CF_AVN_CluRoadInfoGuide 0 "Default" 1 "Off" 2 "On" 3 "Invalid" ;
VAL_ 1195 CF_AVN_CluUserSettingPeriod 0 "0~99month" 1 "0~99month" 2 "0~99month" 3 "0~99month" 4 "0~99month" 5 "0~99month" 6 "0~99month" 7 "0~99month" 8 "0~99month" 9 "0~99month" 10 "0~99month" 11 "0~99month" 12 "0~99month" 13 "0~99month" 14 "0~99month" 15 "0~99month" 16 "0~99month" 17 "0~99month" 18 "0~99month" 19 "0~99month" 20 "0~99month" 21 "0~99month" 22 "0~99month" 23 "0~99month" 24 "0~99month" 25 "0~99month" 26 "0~99month" 27 "0~99month" 28 "0~99month" 29 "0~99month" 30 "0~99month" 31 "0~99month" 32 "0~99month" 33 "0~99month" 34 "0~99month" 35 "0~99month" 36 "0~99month" 37 "0~99month" 38 "0~99month" 39 "0~99month" 40 "0~99month" 41 "0~99month" 42 "0~99month" 43 "0~99month" 44 "0~99month" 45 "0~99month" 46 "0~99month" 47 "0~99month" 48 "0~99month" 49 "0~99month" 50 "0~99month" 51 "0~99month" 52 "0~99month" 53 "0~99month" 54 "0~99month" 55 "0~99month" 56 "0~99month" 57 "0~99month" 58 "0~99month" 59 "0~99month" 60 "0~99month" 61 "0~99month" 62 "0~99month" 63 "0~99month" 64 "0~99month" 65 "0~99month" 66 "0~99month" 67 "0~99month" 68 "0~99month" 69 "0~99month" 70 "0~99month" 71 "0~99month" 72 "0~99month" 73 "0~99month" 74 "0~99month" 75 "0~99month" 76 "0~99month" 77 "0~99month" 78 "0~99month" 79 "0~99month" 80 "0~99month" 81 "0~99month" 82 "0~99month" 83 "0~99month" 84 "0~99month" 85 "0~99month" 86 "0~99month" 87 "0~99month" 88 "0~99month" 89 "0~99month" 90 "0~99month" 91 "0~99month" 92 "0~99month" 93 "0~99month" 94 "0~99month" 95 "0~99month" 96 "0~99month" 97 "0~99month" 98 "0~99month" 99 "0~99month" 100 "Reserved" 101 "Reserved" 102 "Reserved" 103 "Reserved" 104 "Reserved" 105 "Reserved" 106 "Reserved" 107 "Reserved" 108 "Reserved" 109 "Reserved" 110 "Reserved" 111 "Reserved" 112 "Reserved" 113 "Reserved" 114 "Reserved" 115 "Reserved" 116 "Reserved" 117 "Reserved" 118 "Reserved" 119 "Reserved" 120 "Reserved" 121 "Reserved" 122 "Reserved" 123 "Reserved" 124 "Reserved" 125 "Reserved" 126 "Reserved" 127 "Invalid" ;
VAL_ 1195 CF_AVN_CluAutoInitFuelEconomy 0 "Default" 1 "Off" 2 "Driving" 3 "Refuel" 4 "Reserved" 5 "Reserved" 6 "Reserved" 7 "Invalid" ;
VAL_ 1195 CF_AVN_CluFuelEconUnit_mi 0 "Default" 1 "US gallon" 2 "UK gallon" 3 "Reserved" ;
VAL_ 1195 CF_AVN_CluFuelEconUnit_km 0 "Default" 1 "km/L, km/kg, km/kWh" 2 "L/100km, kg/100km, kWh/100km" 3 "Reserved" ;
VAL_ 1195 CF_AVN_CluUserSettingDistance 0 "0x0x0~0x1869F:0~9999km_mi" 99999 "0x0x0~0x1869F:0~9999km_mi" 131071 "Invalid" ;
VAL_ 1195 CF_AVN_CluRheostatLvl 0 "Reserved" 1 "Step 1" 2 "Step 2" 3 "Step 3" 4 "Step 4" 5 "Step 5" 6 "Step 6" 7 "Step 7" 8 "Step 8" 9 "Step 9" 10 "Step 10" 11 "Step 11" 12 "Step 12" 13 "Step 13" 14 "Step 14" 15 "Step 15" 16 "Step 16" 17 "Step 17" 18 "Step 18" 19 "Step 19" 20 "Step 20(Reset Value)" 21 "Step 21(Detent)" 22 "Reserved" 23 "Reserved" 24 "Reserved" 25 "Reserved" 26 "Reserved" 27 "Reserved" 28 "Reserved" 29 "Reserved" 30 "Reserved" 31 "Invalid" ;
VAL_ 1195 CF_AVN_CluVoiceVolume 0 "Default" 1 "Level0" 2 "Level1" 3 "Level2" 4 "Level3" 5 "Reserved" 6 "Reserved" 7 "Invalid" ;
VAL_ 1195 CF_AVN_EVReset 0 "Default" 1 "USM Reset" 2 "Reserved" 3 "Invalid" ;
VAL_ 1195 CF_AVN_UnitReset 0 "Default" 1 "Unit Reset" 2 "Reserved" 3 "Invalid" ;
VAL_ 1195 CF_AVN_IcyRoadWarn 0 "Default" 1 "Off" 2 "On" 3 "Invalid" ;
VAL_ 1195 CF_AVN_CluServiceReminderReset 0 "Default" 1 "Service Reminder Reset" 2 "Reserved" 3 "Invalid" ;
VAL_ 1195 CF_AVN_CluUSMReset 0 "Default" 1 "USM Reset" 2 "Reserved" 3 "Invalid" ;
VAL_ 1195 CF_AVN_CluServiceReminderSet 0 "Default" 1 "Off" 2 "On" 3 "Invalid" ;
VAL_ 1196 C_HCIMSWeightNValueSet 0 "Default" 1 "Under 49.4kg" 2 "49.5~59.4kg" 3 "59.5~69.4kg" 4 "69.5~79.4kg" 5 "79.5~89.4kg" 6 "89.5~99.4kg" 7 "99.5~109.4kg" 8 "109.5~119.4kg" 9 "More than 119.5kg" 10 "Reserved" 11 "Reserved" 12 "Reserved" 13 "Reserved" 14 "Reserved" 15 "Invalid" ;
VAL_ 1196 C_HCIMSSitHeightNValueSet 0 "Default" 1 "Tall" 2 "Middle" 3 "Short" 4 "Reserved" 5 "Reserved" 6 "Reserved" 7 "Reserved" 8 "Reserved" 9 "Reserved" 10 "Reserved" 11 "Reserved" 12 "Reserved" 13 "Reserved" 14 "Reserved" 15 "Invalid" ;
VAL_ 1196 CF_AVN_BodySpprtSet 0 "Default" 1 "Off" 2 "On" 3 "Invalid" ;
VAL_ 1196 CF_AVN_AirSptTimeNValueSet 0 "Default" 1 "Short" 2 "Normal" 3 "Long" 4 "Reserved" 5 "Reserved" 6 "Reserved" 7 "Invalid" ;
VAL_ 1196 CF_AVN_AirSptStrNValue 0 "Default" 1 "Normal" 2 "Intense" 3 "Invalid" ;
VAL_ 1196 CF_AVN_SeatDrvModNValueSet 0 "Default" 1 "Off" 2 "On" 3 "Invalid" ;
VAL_ 1196 C_HCIMSHeightNvalueSet 0 "Default" 1 "Less than 147.5cm" 2 "147.5~152.4cm" 3 "152.5~157.4cm" 4 "157.5~162.4cm" 5 "162.5~167.4cm" 6 "167.5~172.4cm" 7 "172.5~177.4cm" 8 "177.5~182.4cm" 9 "182.5~187.4cm" 10 "187.5~192.4cm" 11 "192.5~197.4cm" 12 "more than 197.5cm" 13 "Reserved" 14 "Reserved" 15 "Invalid" ;
VAL_ 1196 C_SLB_SmartCtrl_NValue 0 "Init" 1 "Disable" 2 "Enable" 3 "Invalid" ;
VAL_ 1196 CF_AVN_CushSoftNValueSet 0 "Default" 1 "Soft" 2 "Mid" 3 "Hard" 4 "Reserved" 5 "Reserved" 6 "Off" 7 "Invalid" ;
VAL_ 1196 C_SmrtSldngDrNValueSet 0 "Default" 1 "Off" 2 "On" 3 "Reserved" 4 "Reserved" 5 "Reserved" 6 "Reserved" 7 "Invalid" ;
VAL_ 1196 CF_AVN_TurboPressureUnit 0 "Default" 1 "Psi" 2 "kPa" 3 "bar" 4 "Reserved" 5 "Reserved" 6 "Reserved" 7 "Invalid" ;
VAL_ 1196 CF_AVN_CluTorqueUnit 0 "Default" 1 "Nm" 2 "lb_ft" 3 "Invalid" ;
VAL_ 1196 AVN_Usm_CluThemeAutoSet 0 "Default" 1 "Off" 2 "On" 3 "Invalid" ;
VAL_ 1196 AVN_Usm_CluFuelEconomySet 0 "Default" 1 "Off" 2 "After Ignition" 3 "After Refueling" 4 "Accumulated Fuel Economy" 5 "Reserved" 6 "Reserved" 7 "Invalid" ;
VAL_ 1196 CF_AVN_HCIMSButtonCommand 0 "Default" 1 "Health Care IMS Exit" 2 "Detail View" 3 "Move to recommend position" 4 "Current position Analysis" 5 "Move to setting page" 6 "Save view" 7 "IMS1 saved" 8 "IMS2 saved" 9 "Summary view" 10 "Smart IMS On" 11 "Reserved" 12 "Reserved" 13 "Reserved" 14 "Reserved" 15 "Invalid" ;
VAL_ 1167 Bat_dischrg 0 "Flag OFF" 1 "Flag ON" 2 "Reserved" 3 "Reserved" ;
VAL_ 1167 Batt_SoCWarningValue 0 "0x0x0~0x64:0 ~ 100%" 100 "0x0x0~0x64:0 ~ 100%" 101 "0x65~0xFE:Reserved" 254 "0x65~0xFE:Reserved" 255 "Invalid" ;
VAL_ 1167 C_StrgWhlHeatingOpt 0 "Not Applied" 1 "Applied(steering wheel applied)" 2 "Reserved" 3 "Invalid" ;
VAL_ 1167 C_StrgWhlHeatingSWInf 0 "Default" 1 "1step opt(On/Off)" 2 "2step opt(step1,step2,Off)" 3 "Invalid" ;
VAL_ 1167 ICU_BattAutoCutPreWrng 0 "No Warning" 1 "Warning" 2 "Not Used" 3 "Invalid" ;
VAL_ 1167 IGN_AutoOff_WarnSta_CLU 0 "No Warning" 1 "Power Off Warning" 2 "Reserved" 3 "Error Indicator" ;
VAL_ 1167 PDC_BatPwrStateClassA 0 "Invaild" 1 "Low power condition for ClassA-load operation during park mode" 2 "High power condition for ClassA-load operation during park mode" 3 "Reserved" ;
VAL_ 1167 PDC_BatPwrStateClassB 0 "Invaild" 1 "Low power condition for ClassB-load operation during park mode" 2 "High power condition for ClassB-load operation during park mode" 3 "Reserved" ;
VAL_ 1167 PDC_BatPwrStateClassC 0 "Invaild" 1 "Low power condition for ClassC-load operation during park mode" 2 "High power condition for ClassC-load operation during park mode" 3 "Reserved" ;
VAL_ 1167 PLBMAvailableState 0 "Invaild" 1 "PLBM Power is available" ;
VAL_ 1167 IGN_AutoOff_WarnSta 0 "No Warning" 1 "Power Off Warning" 2 "Reserved" 3 "Error Indicator" ;
VAL_ 1171 RLPSM_SWVerMajor1 0 "0x0x0~0x7F:ASCII Code Value (HEX)" 127 "0x0x0~0x7F:ASCII Code Value (HEX)" ;
VAL_ 1171 RLPSM_SWVerMinor2 0 "0x0x0~0x7F:ASCII Code Value (HEX)" 127 "0x0x0~0x7F:ASCII Code Value (HEX)" ;
VAL_ 1171 RLPSM_SWVerMinor1 0 "0x0x0~0x7F:ASCII Code Value (HEX)" 127 "0x0x0~0x7F:ASCII Code Value (HEX)" ;
VAL_ 1181 RL_SHVU_SeatEcoSta 0 "Off(Initial Value)" 1 "On" 2 "RESERVED" 3 "Error Indicator" ;
VAL_ 1172 RRPSM_SWVerMajor1 0 "0x0x0~0x7F:ASCII Code Value (HEX)" 127 "0x0x0~0x7F:ASCII Code Value (HEX)" ;
VAL_ 1172 RRPSM_SWVerMinor2 0 "0x0x0~0x7F:ASCII Code Value (HEX)" 127 "0x0x0~0x7F:ASCII Code Value (HEX)" ;
VAL_ 1172 RRPSM_SWVerMinor1 0 "0x0x0~0x7F:ASCII Code Value (HEX)" 127 "0x0x0~0x7F:ASCII Code Value (HEX)" ;
VAL_ 1182 RR_SHVU_SeatEcoSta 0 "Off(Initial Value)" 1 "On" 2 "RESERVED" 3 "Error Indicator" ;
VAL_ 208 RR_SHVU_DTCdisplay 0 "DTC is not exist(Fail is not exist)" 1 "IGN2 Fuse Open Detection" 2 "Switch Input Detection at Same Time" 3 "NTC/Heating wire Open Detection" 4 "NTC+/NTC- Terminal Short Detection" 5 "NTC+/Heater+ Terminal Short Detection" 6 "NTC+/Heater-, Heater+/Heater-, Heater+/NTC- Terminal Short Detection" 7 "NTC+/Heater- Wiring Short Detection" 8 "NTC+/Heater-, Heater+/Heater-, Heater+/NTC- Wiring Short Detection" 9 "Target Temperature Dissatisfied" 10 "Blower+/Blower- Short, Blower+/Blower Speed, Blower-/Blower Speed Wiring Short Detection" 11 "Blower+/Blower RPM, Blower-/Blower RPM, Blower Speed/Blower RPM Short Detection" 12 "Blower+, Blower-, Blower Speed Signal open Detection" 13 "Blower RPM signal Open Detection" 14 "0xE~0xFD:Unused" 253 "0xE~0xFD:Unused" 254 "No Display" 255 "Invalid" ;
VAL_ 208 RR_SHVU_DiagMode 0 "Default" 1 "DTC Mode" 2 "Normal Mode" 3 "Invalid" ;
VAL_ 761 CDM_TypeOption_AST 0 "Off" 1 "On" 2 "Error Indicator" 3 "Invalid" ;
VAL_ 761 CDM_ImmeChgSw_AST 0 "Default" 1 "Off" 2 "On" 3 "Invalid" ;
VAL_ 761 CDM_ChgDrSwFrt_AST 0 "Default" 1 "Close" 2 "Open" 3 "Invalid" ;
VAL_ 761 CDM_OpnClsState_AST 0 "Default" 1 "Open" 2 "Close" 3 "Invalid" ;
VAL_ 761 CDM_WarnMsg_AST 0 "Default" 1 "Normal" 2 "ChargeDoorErrorState" 3 "Invalid" ;
VAL_ 761 Mirror_RH_FoldingSta 0 "Off" 1 "Folding" 2 "Not Used" 3 "Error Indicator" ;
VAL_ 761 Mirror_RH_UnfoldingSta 0 "Off" 1 "Unfolding" 2 "Not Used" 3 "Error Indicator" ;
VAL_ 761 CDM_CmdStatus_AST 0 "Open (AVN)" 1 "Open (SMK)" 2 "Open (Sensor Switch)" 3 "Open (Command Hard Switch)" 4 "Open (Anti - Pinch)" 5 "Close (AVN)" 6 "Close (SMK)" 7 "Close (Assist Mode)" 8 "Close (Command Hard Switch)" 9 "Close (Connector)" 10 "Close (Gear Position)" 11 "Close (Time Over)" 12 "Close (Anti - Pinch)" 13 "Close (Sensor Switch)" 14 "Stall (Stop)" 15 "Invalid" ;
VAL_ 761 AST_CrashMRActAlarm 0 "Off" 1 "On" 2 "Not Used" 3 "Error Indicator" ;
VAL_ 761 IMS_OSMirPlayBackSta_RH 0 "Stop" 1 "Play 1" 2 "Play 2" 3 "Smart IMS" 4 "Profile 1" 5 "Profile 2" 6 "Guest" 7 "Invalid" ;
VAL_ 761 Mirror_RHVerPosVal 251 "Reserved" 252 "Reserved" 253 "Reserved" 254 "Reserved" 255 "Error Indicator" ;
VAL_ 761 Mirror_RHHorPosVal 251 "Reserved" 252 "Reserved" 253 "Reserved" 254 "Reserved" 255 "Error Indicator" ;
VAL_ 761 SBCM_AST_DiagSta 0 "Default" 1 "Normal Operation" 2 "AST Indicator Circuit Failure" 3 "Invalid" ;
VAL_ 758 DoorLock_CtrlDrLkUnLkSwSta_SBCM 0 "Off" 1 "On" 2 "Not Used" 3 "Error Indicator" ;
VAL_ 758 SBCM_PsvDrLkReq 0 "None" 1 "Lock" 2 "Passive Trunk Lock" 3 "Not Used" ;
VAL_ 758 USM_DrvGhostDoorSta 0 "Default" 1 "Off" 2 "On" 3 "Invalid" ;
VAL_ 758 Mirror_LH_FoldingSta 0 "Off" 1 "Folding" 2 "Not Used" 3 "Error Indicator" ;
VAL_ 758 Mirror_LH_UnfoldingSta 0 "Off" 1 "Unfolding" 2 "Not Used" 3 "Error Indicator" ;
VAL_ 758 DRV_CrashMRActAlarm 0 "Off" 1 "On" 2 "Not Used" 3 "Error Indicator" ;
VAL_ 758 MirrorFldReq 0 "Default" 1 "Folding Request" 2 "Unfolding Request" 3 "Invalid" ;
VAL_ 758 OMU_TypeOption_DRV 0 "Off" 1 "On" 2 "Not Used" 3 "Error Indicator" ;
VAL_ 758 IMS_OSMirPlayBackSta_LH 0 "Stop" 1 "Play 1" 2 "Play 2" 3 "Smart IMS" 4 "Profile 1" 5 "Profile 2" 6 "Guest" 7 "Invalid" ;
VAL_ 758 ECMMRR_PLUS 0 "0x0x0~0x7D:0~1.25 V" 125 "0x0x0~0x7D:0~1.25 V" 126 "0x7E~0xFE:Reserved" 254 "0x7E~0xFE:Reserved" 255 "Invalid" ;
VAL_ 758 Mirror_LHVerPosVal 251 "Reserved" 252 "Reserved" 253 "Reserved" 254 "Reserved" 255 "Error Indicator" ;
VAL_ 758 Mirror_LHHorPosVal 251 "Reserved" 252 "Reserved" 253 "Reserved" 254 "Reserved" 255 "Error Indicator" ;
VAL_ 758 SBCM_DRV_DiagSta 0 "Default" 1 "Normal Operation" 2 "DRV Indicator Circuit Failure" 3 "Invalid" ;
VAL_ 763 CDM_TypeOption 0 "Off" 1 "On" 2 "Error Indicator" 3 "Reserved" ;
VAL_ 763 CDM_ImmeChgSw_SBCM 0 "Default" 1 "Off" 2 "On" 3 "Invalid" ;
VAL_ 763 CDM_ChgDrSwFrt_SBCM 0 "Default" 1 "Close" 2 "Open" 3 "Invalid" ;
VAL_ 763 CDM_OpnClsState_SBCM 0 "Default" 1 "Open" 2 "Close" 3 "Invalid" ;
VAL_ 763 CDM_WarnMsg_SBCM 0 "Default" 1 "Normal" 2 "ChargeDoorErrorState" 3 "Invalid" ;
VAL_ 763 CDM_CmdStatus_SBCM 0 "Open (AVN)" 1 "Open (SMK)" 2 "Open (Sensor Switch)" 3 "Open (Command Hard Switch)" 4 "Open (Anti - Pinch)" 5 "Close (AVN)" 6 "Close (SMK)" 7 "Close (Assist Mode)" 8 "Close (Command Hard Switch)" 9 "Close (Connector)" 10 "Close (Gear Position)" 11 "Close (Time Over)" 12 "Close (Anti - Pinch)" 13 "Close (Sensor Switch)" 14 "Stall (Stop)" 15 "Invalid" ;
VAL_ 763 Warn_HoodSwSta_SBCM 0 "Off" 1 "On" 2 "RESERVED" 3 "Error Indicator" ;
VAL_ 763 Hood_TypeOption 0 "Off" 1 "On" 2 "RESERVED" 3 "Error Indicator" ;
VAL_ 763 CDM_InsideOpnSwSta 0 "Off" 1 "On" 2 "Not Used" 3 "Error Indicator" ;
VAL_ 742 SGU_FltSta 0 "Normal" 1 "Fault" 2 "Not Used" 3 "Error Indicator" ;
VAL_ 742 SGU_BlindOnOffSet 0 "USM Activation" 1 "Off" 2 "On" 3 "Invalid" ;
VAL_ 742 SGU_Roof_OprLv 0 "USM Activation" 1 "OFF" 2 "Level 1" 3 "Level 2" 4 "Level 3" 5 "Reserved" 6 "Reserved" 7 "Invalid" ;
VAL_ 742 SGU_2ndLeftDoor_OprLv 0 "USM Activation" 1 "Off" 2 "Level 1" 3 "Level 2" 4 "Level 3" 5 "Reserved" 6 "Reserved" 7 "Invalid" ;
VAL_ 742 SGU_2ndRightDoor_OprLv 0 "USM Activation" 1 "Off" 2 "Level 1" 3 "Level 2" 4 "Level 3" 5 "Reserved" 6 "Reserved" 7 "Invalid" ;
VAL_ 742 SGU_3rdLeftDoor_OprLv 0 "USM Activation" 1 "Off" 2 "Level 1" 3 "Level 2" 4 "Level 3" 5 "Reserved" 6 "Reserved" 7 "Invalid" ;
VAL_ 742 SGU_3rdRightDoor_OprLv 0 "USM Activation" 1 "Off" 2 "Level 1" 3 "Level 2" 4 "Level 3" 5 "Reserved" 6 "Reserved" 7 "Invalid" ;
VAL_ 742 SGU_RearWindow_OprLv 0 "USM Activation" 1 "Off" 2 "Level 1" 3 "Level 2" 4 "Level 3" 5 "Reserved" 6 "Reserved" 7 "Invalid" ;
VAL_ 742 SGU_OprLvSet 0 "Default" 1 "Level 1" 2 "Level 2" 3 "Level 3" 4 "Level 4" 5 "Level 5" 6 "Level 6" 7 "Invalid" ;
VAL_ 742 SGU_RdySta 0 "Off" 1 "Ready" 2 "Sleep" 3 "Reserved" ;
